VERSION ""

NS_ :

BS_:

BU_: DCM CCU C_ECU C_ECU_GW

BO_ 1546 BAT60A: 32 C_ECU_GW
 SG_ BAT60A_29_4_LVB_VOL : 236|8@1+ (0.1,0) [0|25] "V" Vector__XXX
 SG_ BAT60A_29_3_EXWATTMPERR : 235|1@1+ (1,0) [0|1] "" Vector__XXX
 SG_ BAT60A_29_2_SNSWATTMPERR : 234|1@1+ (1,0) [0|1] "" Vector__XXX
 SG_ BAT60A_29_1_SNSSMKEMSERR : 233|1@1+ (1,0) [0|1] "" Vector__XXX
 SG_ BAT60A_29_0_SNSEXTMP2ERR : 232|1@1+ (1,0) [0|1] "" Vector__XXX
 SG_ BAT60A_28_7_SNSEXTMP1ERR : 231|1@1+ (1,0) [0|1] "" Vector__XXX
 SG_ BAT60A_28_6_DEVTSTCK3ERR : 230|1@1+ (1,0) [0|1] "" Vector__XXX
 SG_ BAT60A_28_5_DEVTSTCK2ERR : 229|1@1+ (1,0) [0|1] "" Vector__XXX
 SG_ BAT60A_28_4_DEVTSTCK1ERR : 228|1@1+ (1,0) [0|1] "" Vector__XXX
 SG_ BAT60A_28_3_OVERTLVL2ERR : 227|1@1+ (1,0) [0|1] "" Vector__XXX
 SG_ BAT60A_28_2_OVERTLVL1ERR : 226|1@1+ (1,0) [0|1] "" Vector__XXX
 SG_ BAT60A_28_1_RESDEVERR : 225|1@1+ (1,0) [0|1] "" Vector__XXX
 SG_ BAT60A_28_0_PWLINEOV6ERR : 224|1@1+ (1,0) [0|1] "" Vector__XXX
 SG_ BAT60A_27_7_PWLINEOV5ERR : 223|1@1+ (1,0) [0|1] "" Vector__XXX
 SG_ BAT60A_27_6_PWLINEOV4ERR : 222|1@1+ (1,0) [0|1] "" Vector__XXX
 SG_ BAT60A_27_5_PWLINEOV3ERR : 221|1@1+ (1,0) [0|1] "" Vector__XXX
 SG_ BAT60A_27_4_PWLINEOV2ERR : 220|1@1+ (1,0) [0|1] "" Vector__XXX
 SG_ BAT60A_27_3_PWLINEOV1ERR : 219|1@1+ (1,0) [0|1] "" Vector__XXX
 SG_ BAT60A_27_2_VWOUTOVERERR : 218|1@1+ (1,0) [0|1] "" Vector__XXX
 SG_ BAT60A_27_1_VWINOVERERR : 217|1@1+ (1,0) [0|1] "" Vector__XXX
 SG_ BAT60A_27_0_ACTESTDEVERR : 216|1@1+ (1,0) [0|1] "" Vector__XXX
 SG_ BAT60A_26_7_RWOUTUNDERR : 215|1@1+ (1,0) [0|1] "" Vector__XXX
 SG_ BAT60A_26_6_RWINOVRERR : 214|1@1+ (1,0) [0|1] "" Vector__XXX
 SG_ BAT60A_26_5_HVOFFISOERR : 213|1@1+ (1,0) [0|1] "" Vector__XXX
 SG_ BAT60A_26_4_HVONISOERR : 212|1@1+ (1,0) [0|1] "" Vector__XXX
 SG_ BAT60A_26_3_HVSUMCOMPERR : 211|1@1+ (1,0) [0|1] "" Vector__XXX
 SG_ BAT60A_26_2_CEUNDULV2ERR : 210|1@1+ (1,0) [0|1] "" Vector__XXX
 SG_ BAT60A_26_1_CEOVRULV2ERR : 209|1@1+ (1,0) [0|1] "" Vector__XXX
 SG_ BAT60A_26_0_ICHPEAKERR : 208|1@1+ (1,0) [0|1] "" Vector__XXX
 SG_ BAT60A_25_7_IDCHAPEAKERR : 207|1@1+ (1,0) [0|1] "" Vector__XXX
 SG_ BAT60A_25_6_HVOVRULV2ERR : 206|1@1+ (1,0) [0|1] "" Vector__XXX
 SG_ BAT60A_25_5_HVUNDULV2ERR : 205|1@1+ (1,0) [0|1] "" Vector__XXX
 SG_ BAT60A_25_4_CEUNDULV1ERR : 204|1@1+ (1,0) [0|1] "" Vector__XXX
 SG_ BAT60A_25_3_CEOVRULV1ERR : 203|1@1+ (1,0) [0|1] "" Vector__XXX
 SG_ BAT60A_25_2_HVOVRULV1ERR : 202|1@1+ (1,0) [0|1] "" Vector__XXX
 SG_ BAT60A_25_1_CEUDIFDYNERR : 201|1@1+ (1,0) [0|1] "" Vector__XXX
 SG_ BAT60A_25_0_OVERSOCERR : 200|1@1+ (1,0) [0|1] "" Vector__XXX
 SG_ BAT60A_24_7_UNDERSOCERR : 199|1@1+ (1,0) [0|1] "" Vector__XXX
 SG_ BAT60A_24_6_HVUNDULV1ERR : 198|1@1+ (1,0) [0|1] "" Vector__XXX
 SG_ BAT60A_24_5_ISOMEASERR : 197|1@1+ (1,0) [0|1] "" Vector__XXX
 SG_ BAT60A_24_4_CHGAWINOVERR : 196|1@1+ (1,0) [0|1] "" Vector__XXX
 SG_ BAT60A_24_3_CEUHIDIFERR : 195|1@1+ (1,0) [0|1] "" Vector__XXX
 SG_ BAT60A_23_6_HVB_OUTLIMFCT : 190|5@1+ (1,0) [0|30] "" Vector__XXX
 SG_ BAT60A_23_1_HVB_INLIMFCT : 185|5@1+ (1,0) [0|30] "" Vector__XXX
 SG_ BAT60A_22_4_HVB_WOUT : 180|10@1- (1,-510) [-510|511] "kW" Vector__XXX
 SG_ BAT60A_21_2_HVB_WIN : 170|10@1- (1,-510) [-510|511] "kW" Vector__XXX
 SG_ BAT60A_20_5_HVB_OPRMODE : 165|5@1+ (1,0) [0|30] "" Vector__XXX
 SG_ BAT60A_19_1_HVB_CELLSOHRMIN : 153|7@1+ (1,0) [0|100] "%" Vector__XXX
 SG_ BAT60A_18_2_HVB_CELLSOHRMAX : 146|7@1+ (1,0) [0|100] "%" Vector__XXX
 SG_ BAT60A_17_3_HVB_CELLSOHCMIN : 139|7@1+ (1,0) [0|100] "%" Vector__XXX
 SG_ BAT60A_16_4_HVB_CELLSOHCMAX : 132|7@1+ (1,0) [0|100] "%" Vector__XXX
 SG_ BAT60A_15_5_HVB_SOC : 125|7@1+ (1,0) [0|100] "%" Vector__XXX
 SG_ BAT60A_14_5_HVB_WATTEMP : 117|8@1- (1,-125) [-125|126] "℃" Vector__XXX
 SG_ BAT60A_13_5_JB_TEMPSNS : 109|8@1- (1,-125) [-125|126] "℃" Vector__XXX
 SG_ BAT60A_12_5_HVB_CELLTEMPMINNO : 101|8@1+ (1,0) [0|255] "" Vector__XXX
 SG_ BAT60A_11_5_HVB_CELLTEMPMAXNO : 93|8@1+ (1,0) [0|255] "" Vector__XXX
 SG_ BAT60A_10_5_HVB_CELLTEMPMIN : 85|8@1- (1,-125) [-125|126] "℃" Vector__XXX
 SG_ BAT60A_9_5_HVB_CELLTEMPMAX : 77|8@1- (1,-125) [-125|126] "℃" Vector__XXX
 SG_ BAT60A_8_2_HVB_CUR : 66|11@1- (1,-1020) [-1020|1021] "A" Vector__XXX
 SG_ BAT60A_7_2_HVB_CELLVOLMINNO : 58|8@1+ (1,0) [0|255] "" Vector__XXX
 SG_ BAT60A_6_2_HVB_CELLVOLMAXNO : 50|8@1+ (1,0) [0|255] "" Vector__XXX
 SG_ BAT60A_4_5_HVB_CELLVOLMIN : 37|13@1+ (1,0) [0|8190] "mV" Vector__XXX
 SG_ BAT60A_3_0_HVB_CELLVOLMAX : 24|13@1+ (1,0) [0|8190] "mV" Vector__XXX
 SG_ BAT60A_2_0_E2E_COUNTER : 16|8@1+ (1,0) [0|255] "" Vector__XXX
 SG_ BAT60A_0_0_E2E_CRC : 0|16@1+ (1,0) [0|65535] "" Vector__XXX

BO_ 1680 BAT690: 32 C_ECU_GW
 SG_ BAT690_28_2_CHG_REMTI_GRF26 : 226|8@1+ (45,0) [0|10800] "sec"  CCU
 SG_ BAT690_27_2_CHG_REMTI_GRF25 : 218|8@1+ (45,0) [0|10800] "sec"  CCU
 SG_ BAT690_26_2_CHG_REMTI_GRF24 : 210|8@1+ (45,0) [0|10800] "sec"  CCU
 SG_ BAT690_25_2_CHG_REMTI_GRF23 : 202|8@1+ (45,0) [0|10800] "sec"  CCU
 SG_ BAT690_24_2_CHG_REMTI_GRF22 : 194|8@1+ (45,0) [0|10800] "sec"  CCU
 SG_ BAT690_23_2_CHG_REMTI_GRF21 : 186|8@1+ (45,0) [0|10800] "sec"  CCU
 SG_ BAT690_22_2_CHG_REMTI_GRF20 : 178|8@1+ (45,0) [0|10800] "sec"  CCU
 SG_ BAT690_21_2_CHG_REMTI_GRF19 : 170|8@1+ (45,0) [0|10800] "sec"  CCU
 SG_ BAT690_20_2_CHG_REMTI_GRF18 : 162|8@1+ (45,0) [0|10800] "sec"  CCU
 SG_ BAT690_19_2_CHG_REMTI_GRF17 : 154|8@1+ (45,0) [0|10800] "sec"  CCU
 SG_ BAT690_18_2_CHG_REMTI_GRF16 : 146|8@1+ (45,0) [0|10800] "sec"  CCU
 SG_ BAT690_17_2_CHG_REMTI_GRF15 : 138|8@1+ (45,0) [0|10800] "sec"  CCU
 SG_ BAT690_16_2_CHG_REMTI_GRF14 : 130|8@1+ (45,0) [0|10800] "sec"  CCU
 SG_ BAT690_15_2_CHG_REMTI_GRF13 : 122|8@1+ (45,0) [0|10800] "sec"  CCU
 SG_ BAT690_14_2_CHG_REMTI_GRF12 : 114|8@1+ (45,0) [0|10800] "sec"  CCU
 SG_ BAT690_13_2_CHG_REMTI_GRF11 : 106|8@1+ (45,0) [0|10800] "sec"  CCU
 SG_ BAT690_12_2_CHG_REMTI_GRF10 : 98|8@1+ (45,0) [0|10800] "sec"  CCU
 SG_ BAT690_11_2_CHG_REMTI_GRF9 : 90|8@1+ (45,0) [0|10800] "sec"  CCU
 SG_ BAT690_10_2_CHG_REMTI_GRF8 : 82|8@1+ (45,0) [0|10800] "sec"  CCU
 SG_ BAT690_9_2_CHG_REMTI_GRF7 : 74|8@1+ (45,0) [0|10800] "sec"  CCU
 SG_ BAT690_8_2_CHG_REMTI_GRF6 : 66|8@1+ (45,0) [0|10800] "sec"  CCU
 SG_ BAT690_7_2_CHG_REMTI_GRF5 : 58|8@1+ (45,0) [0|10800] "sec"  CCU
 SG_ BAT690_6_2_CHG_REMTI_GRF4 : 50|8@1+ (45,0) [0|10800] "sec"  CCU
 SG_ BAT690_5_2_CHG_REMTI_GRF3 : 42|8@1+ (45,0) [0|10800] "sec"  CCU
 SG_ BAT690_4_2_CHG_REMTI_GRF2 : 34|8@1+ (45,0) [0|10800] "sec"  CCU
 SG_ BAT690_3_2_CHG_REMTI_GRF1 : 26|8@1+ (45,0) [0|10800] "sec"  CCU
 SG_ BAT690_3_0_CHG_REMTI_GRF : 24|2@1+ (1,0) [0|3] ""  CCU
 SG_ BAT690_2_0_E2E_COUNTER : 16|8@1+ (1,0) [0|255] ""  CCU
 SG_ BAT690_0_0_E2E_CRC : 0|16@1+ (1,0) [0|65535] ""  CCU

BO_ 862 BAT35E: 32 C_ECU_GW
 SG_ BAT35E_4_4_HVB_CONDCHK_FLG : 36|2@1+ (1,0) [0|3] ""  DCM
 SG_ BAT35E_3_2_HVB_CTRLSOC_PERC : 26|10@1+ (0.1,0) [0|100] "%" Vector__XXX
 SG_ BAT35E_3_0_HVB_WRN_TEMP : 24|2@1+ (1,0) [0|3] "" Vector__XXX
 SG_ BAT35E_2_0_E2E_COUNTER : 16|8@1+ (1,0) [0|255] ""  DCM
 SG_ BAT35E_0_0_E2E_CRC : 0|16@1+ (1,0) [0|65535] ""  DCM

BO_ 861 BAT35D: 32 C_ECU_GW
 SG_ BAT35D_28_5_HVB_ACTCHGWIN : 229|16@1+ (1,0) [0|65533] "kW"  DCM,CCU
 SG_ BAT35D_27_2_HVB_TEMPAVE : 218|11@1+ (0.5,-50) [-50|150] "℃"  CCU
 SG_ BAT35D_25_1_HVB_AVBENE_UPL : 201|17@1+ (1,0) [0|131000] "Wh"  CCU
 SG_ BAT35D_23_0_HVB_AVBENE_CUR : 184|17@1+ (1,0) [0|131000] "Wh"  CCU
 SG_ BAT35D_20_7_HVB_AVBENE_LOL : 167|17@1+ (1,0) [0|131000] "Wh"  CCU
 SG_ BAT35D_18_2_HVB_DISPSOHODO : 146|21@1+ (1,0) [0|1609343] "km"  DCM
 SG_ BAT35D_17_0_HVB_DISPSOH_PERC : 136|8@1+ (1,0) [0|100] "%"  DCM
 SG_ BAT35D_15_7_HVB_DISPSOH_R_AH : 127|9@1+ (1,0) [0|500] "Ah"  DCM
 SG_ BAT35D_14_6_HVB_DISPSOH_AH : 118|9@1+ (1,0) [0|500] "Ah"  DCM
 SG_ BAT35D_13_0_CHG_REMTI_UPS_ACN : 104|14@1+ (1,0) [0|15840] "min"  DCM,CCU
 SG_ BAT35D_11_2_CHG_REMTI_UPS : 90|14@1+ (1,0) [0|15840] "min"  DCM,CCU
 SG_ BAT35D_9_4_CHG_REMTI_BLK_ACN : 76|14@1+ (1,0) [0|15840] "min"  DCM,CCU
 SG_ BAT35D_7_6_CHG_REMTI_BLK : 62|14@1+ (1,0) [0|15840] "min"  DCM,CCU
 SG_ BAT35D_6_0_CHG_REMTI_ACN : 48|14@1+ (1,0) [0|15840] "min"  CCU
 SG_ BAT35D_4_2_CHG_REMTI : 34|14@1+ (1,0) [0|15840] "min"  CCU
 SG_ BAT35D_3_0_HVB_DISPSOC_PERC : 24|8@1+ (1,0) [0|100] "%"  DCM,CCU
 SG_ BAT35D_2_0_E2E_COUNTER : 16|8@1+ (1,0) [0|255] ""  DCM
 SG_ BAT35D_0_0_E2E_CRC : 0|16@1+ (1,0) [0|65535] ""  DCM

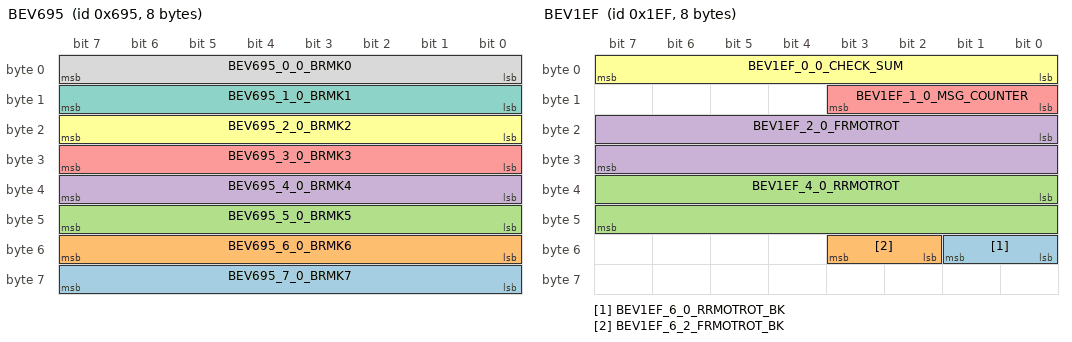
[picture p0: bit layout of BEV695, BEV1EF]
BO_ 1685 BEV695: 8 C_ECU_GW
 SG_ BEV695_7_0_BRMK7 : 56|8@1+ (1,0) [0|255] "" Vector__XXX
 SG_ BEV695_6_0_BRMK6 : 48|8@1+ (1,0) [0|255] "" Vector__XXX
 SG_ BEV695_5_0_BRMK5 : 40|8@1+ (1,0) [0|255] "" Vector__XXX
 SG_ BEV695_4_0_BRMK4 : 32|8@1+ (1,0) [0|255] "" Vector__XXX
 SG_ BEV695_3_0_BRMK3 : 24|8@1+ (1,0) [0|255] "" Vector__XXX
 SG_ BEV695_2_0_BRMK2 : 16|8@1+ (1,0) [0|255] "" Vector__XXX
 SG_ BEV695_1_0_BRMK1 : 8|8@1+ (1,0) [0|255] "" Vector__XXX
 SG_ BEV695_0_0_BRMK0 : 0|8@1+ (1,0) [0|255] "" Vector__XXX

BO_ 1539 BEV603: 32 C_ECU_GW
 SG_ BEV603_15_0_BATTEMPSTS_DISP : 120|3@1+ (1,0) [0|5] "" Vector__XXX
 SG_ BEV603_14_0_RR_MTRTEMPSTS_DISP : 112|3@1+ (1,0) [0|5] "" Vector__XXX
 SG_ BEV603_14_3_FR_MTRTEMPSTS_DISP : 115|3@1+ (1,0) [0|5] "" Vector__XXX
 SG_ BEV603_13_0_BATTEMP_DISP : 104|8@1+ (1,-30) [-30|225] "℃" Vector__XXX
 SG_ BEV603_12_0_RR_MTRTEMP_DISP : 96|8@1+ (1,-30) [-30|225] "℃" Vector__XXX
 SG_ BEV603_11_0_FR_MTRTEMP_DISP : 88|8@1+ (1,-30) [-30|225] "℃" Vector__XXX
 SG_ BEV603_10_2_TRQFLCREQ : 82|2@1+ (1,0) [0|3] "" Vector__XXX
 SG_ BEV603_10_4_TRQFLCNG : 84|1@1+ (1,0) [0|1] ""  CCU
 SG_ BEV603_10_5_TRQFLCSTATE : 85|1@1+ (1,0) [0|1] ""  CCU
 SG_ BEV603_10_6_TRQFLCDISP : 86|1@1+ (1,0) [0|1] ""  CCU
 SG_ BEV603_10_7_TRQVIBREQ : 87|1@1+ (1,0) [0|1] "" Vector__XXX
 SG_ BEV603_9_4_PADL_INHBUZ : 76|1@1+ (1,0) [0|1] "" Vector__XXX
 SG_ BEV603_9_5_PADL_LVL : 77|3@1+ (1,0) [0|7] "" Vector__XXX
 SG_ BEV603_8_1_XMODE_INH : 65|1@1+ (1,0) [0|1] ""  CCU
 SG_ BEV603_8_2_SIDRIVE_INH : 66|1@1+ (1,0) [0|1] ""  CCU
 SG_ BEV603_8_3_SIDRIVE_INHBUZ : 67|1@1+ (1,0) [0|1] "" Vector__XXX
 SG_ BEV603_8_4_ARBIT_SIDR : 68|1@1+ (1,0) [0|1] "" Vector__XXX
 SG_ BEV603_8_5_SIDRIVE_DISP : 69|3@1+ (1,0) [0|7] "" Vector__XXX
 SG_ BEV603_7_4_ADPDEC_INHBUZ : 60|1@1+ (1,0) [0|1] "" Vector__XXX
 SG_ BEV603_7_5_ADPDEC_INH_ALL : 61|1@1+ (1,0) [0|1] ""  CCU
 SG_ BEV603_7_6_ADPDEC_DISP : 62|1@1+ (1,0) [0|1] ""  CCU
 SG_ BEV603_7_7_ADPDEC_EQ : 63|1@1+ (1,0) [0|1] ""  CCU
 SG_ BEV603_6_0_AWD_MODE : 48|3@1+ (1,0) [0|7] "" Vector__XXX
 SG_ BEV603_6_3_AWD_STS_DISP : 51|4@1+ (1,0) [0|7] "" Vector__XXX
 SG_ BEV603_6_4_DECSEL_INHMSG : 52|4@1+ (1,0) [0|15] "" Vector__XXX
 SG_ BEV603_6_7_AWD_MODE_EQUIP : 55|1@1+ (1,0) [0|1] "" Vector__XXX
 SG_ BEV603_5_0_PDLBZR : 40|1@1+ (1,0) [0|1] "" Vector__XXX
 SG_ BEV603_5_1_SFTDN_PERM : 41|1@1+ (1,0) [0|1] "" Vector__XXX
 SG_ BEV603_5_2_SFTUP_PERM : 42|1@1+ (1,0) [0|1] "" Vector__XXX
 SG_ BEV603_5_3_GEARSFT_MODE : 43|2@1+ (1,0) [0|3] ""  CCU
 SG_ BEV603_5_4_DECSEL_INH_INDI : 44|1@1+ (1,0) [0|1] "" Vector__XXX
 SG_ BEV603_5_5_DECSEL_INH_B : 45|1@1+ (1,0) [0|1] "" Vector__XXX
 SG_ BEV603_5_6_DECSEL_INH_D : 46|1@1+ (1,0) [0|1] "" Vector__XXX
 SG_ BEV603_5_7_DECSEL_INH_ALL : 47|1@1+ (1,0) [0|1] "" Vector__XXX
 SG_ BEV603_4_1_DECSEL_DISP_INDI : 33|1@1+ (1,0) [0|1] "" Vector__XXX
 SG_ BEV603_4_2_DECSEL_DISP_B : 34|2@1+ (1,0) [0|3] "" Vector__XXX
 SG_ BEV603_4_4_DECLV_DECSEL : 36|4@1+ (1,0) [0|8] "" Vector__XXX
 SG_ BEV603_4_6_DECSEL_DISP_ALL : 38|2@1+ (1,0) [0|3] "" Vector__XXX
 SG_ BEV603_3_0_GEARLV_MANU : 24|4@1+ (1,0) [0|8] ""  CCU
 SG_ BEV603_3_1_DECSEL_EQ_INDI : 25|1@1+ (1,0) [0|1] "" Vector__XXX
 SG_ BEV603_3_2_DECSEL_EQ_B : 26|2@1+ (1,0) [0|3] "" Vector__XXX
 SG_ BEV603_3_4_GEARLV_AUTO : 28|4@1+ (1,0) [0|8] ""  CCU
 SG_ BEV603_3_6_DECSEL_EQ_ALL : 30|2@1+ (1,0) [0|3] "" Vector__XXX
 SG_ BEV603_2_0_E2E_COUNTER : 16|8@1+ (1,0) [0|255] ""  CCU
 SG_ BEV603_0_0_E2E_CRC : 0|16@1+ (1,0) [0|65535] ""  CCU

BO_ 1538 BEV602: 32 C_ECU_GW
 SG_ BEV602_18_0_V2L_OUTLET_VOLTAGE : 144|8@1+ (0.01,0) [0|250] "V"  CCU
 SG_ BEV602_16_0_LV_SYS_STATUS : 128|2@1+ (1,0) [0|3] "" Vector__XXX
 SG_ BEV602_15_0_DCM_REMOTE_INFO : 120|4@1+ (1,0) [0|7] ""  DCM
 SG_ BEV602_14_7_RR_DISPMSG_RES_UNADJ : 119|1@1+ (1,0) [0|1] "" Vector__XXX
 SG_ BEV602_14_6_FR_DISPMSG_RES_UNADJ : 118|1@1+ (1,0) [0|1] "" Vector__XXX
 SG_ BEV602_14_4_DISPMSG_SC_SGLPH : 116|2@1+ (1,0) [0|3] "" Vector__XXX
 SG_ BEV602_14_2_CERT2_MODE : 114|2@1+ (1,0) [0|2] "" Vector__XXX
 SG_ BEV602_14_0_SW_PWR_SPL : 112|2@1+ (1,0) [0|3] ""  CCU
 SG_ BEV602_13_0_TCSLMP_REQ : 104|1@1+ (1,0) [0|1] "" Vector__XXX
 SG_ BEV602_13_1_AWDLMP_REQ : 105|2@1+ (1,0) [0|3] "" Vector__XXX
 SG_ BEV602_13_3_AWDWRNMSG_REQ : 107|4@1+ (1,0) [0|2] "" Vector__XXX
 SG_ BEV602_12_0_BOSLMP_REQ : 96|2@1+ (1,0) [0|3] "" Vector__XXX
 SG_ BEV602_11_3_LVB_ABN : 91|3@1+ (1,0) [0|4] "" Vector__XXX
 SG_ BEV602_11_6_CERT4_MODE : 94|1@1+ (1,0) [0|1] "" Vector__XXX
 SG_ BEV602_11_7_CERT2_MODE : 95|1@1+ (1,0) [0|1] "" Vector__XXX
 SG_ BEV602_10_0_FACT_CERT_MODE : 80|1@1+ (1,0) [0|1] "" Vector__XXX
 SG_ BEV602_10_1_FACT_MODE : 81|1@1+ (1,0) [0|1] "" Vector__XXX
 SG_ BEV602_10_2_EVBATLO_CAU : 82|3@1+ (1,0) [0|7] ""  DCM,CCU
 SG_ BEV602_10_5_PWRLMT_ID : 85|3@1+ (1,0) [0|3] "" Vector__XXX
 SG_ BEV602_9_1_DCRCHK_DSP_REQ : 73|3@1+ (1,0) [0|4] "" Vector__XXX
 SG_ BEV602_9_4_LVB_FNCLMT_MSG : 76|3@1+ (1,0) [0|3] ""  CCU
 SG_ BEV602_9_7_CHG_MSG : 79|1@1+ (1,0) [0|1] "" Vector__XXX
 SG_ BEV602_8_0_LVB_ABN_DCDC : 64|3@1+ (1,0) [0|2] "" Vector__XXX
 SG_ BEV602_8_4_LVB_ABN_LIB : 68|3@1+ (1,0) [0|3] "" Vector__XXX
 SG_ BEV602_8_7_CHG_CAU : 71|1@1+ (1,0) [0|1] "" Vector__XXX
 SG_ BEV602_7_0_V2L_STOP_MSG : 56|8@1+ (1,0) [0|8] ""  DCM,CCU
 SG_ BEV602_6_0_V2L_SOC_LOWLMT : 48|8@1+ (0.01,0) [0|255] "%"  DCM,CCU
 SG_ BEV602_5_0_V2L_OUTSTS_2 : 40|1@1+ (1,0) [0|1] ""  CCU
 SG_ BEV602_5_1_V2L_OUTSTS_1 : 41|1@1+ (1,0) [0|1] ""  DCM,CCU
 SG_ BEV602_5_2_ACCHCAU : 42|1@1+ (1,0) [0|1] "" Vector__XXX
 SG_ BEV602_5_3_EVIND : 43|5@1+ (1,0) [0|49] ""  DCM
 SG_ BEV602_4_0_BEV_OBD_CAU : 32|3@1+ (1,0) [0|7] "" Vector__XXX
 SG_ BEV602_4_3_EV_CAU : 35|2@1+ (1,0) [0|3] "" Vector__XXX
 SG_ BEV602_4_5_PIROFF_MSG : 37|1@1+ (1,0) [0|1] "" Vector__XXX
 SG_ BEV602_3_0_DRVRDY : 24|2@1+ (1,0) [0|3] "" Vector__XXX
 SG_ BEV602_3_2_RANGE_POS : 26|3@1+ (1,0) [0|7] ""  CCU
 SG_ BEV602_2_0_E2E_COUNTER : 16|8@1+ (1,0) [0|255] ""  DCM,CCU
 SG_ BEV602_0_0_E2E_CRC : 0|16@1+ (1,0) [0|65535] ""  DCM,CCU

BO_ 541 BEV21D: 32 C_ECU_GW
 SG_ BEV21D_4_0_V2L_PWR_2 : 32|8@1+ (0.1,0) [0|25.5] "kW"  CCU
 SG_ BEV21D_3_0_V2L_PWR_1 : 24|8@1+ (0.1,0) [0|25.5] "kW"  DCM,CCU
 SG_ BEV21D_2_0_E2E_COUNTER : 16|8@1+ (1,0) [0|255] ""  DCM,CCU
 SG_ BEV21D_0_0_E2E_CRC : 0|16@1+ (1,0) [0|65535] ""  DCM,CCU

BO_ 269 BEV10D: 32 C_ECU_GW
 SG_ BEV10D_22_0_SNDGAIN_CHG : 176|4@1+ (1,0) [0|15] ""  CCU
 SG_ BEV10D_21_0_EVENT_VOL_B : 168|8@1+ (1,0) [0|255] ""  CCU
 SG_ BEV10D_20_0_EVENT_VOL_A : 160|8@1+ (1,0) [0|255] ""  CCU
 SG_ BEV10D_18_0_RR_MTRTRQ_SND : 144|16@1- (0.03125,0) [-1024|1023.96875] "Nm"  CCU
 SG_ BEV10D_16_0_FR_MTRTRQ_SND : 128|16@1- (0.03125,0) [-1024|1023.96875] "Nm"  CCU
 SG_ BEV10D_15_6_ENGON_SND : 126|1@1+ (1,0) [0|1] ""  CCU
 SG_ BEV10D_15_7_BKF_SND : 127|1@1+ (1,0) [0|1] ""  CCU
 SG_ BEV10D_14_0_V_ENGRPM_SND : 112|14@1+ (1,0) [0|16383] "rpm"  CCU
 SG_ BEV10D_12_0_V_RZRPM_DISP : 96|8@1+ (50,5000) [5000|17750] "rpm" Vector__XXX
 SG_ BEV10D_11_6_SNDOUT_SET : 94|1@1+ (1,0) [0|1] ""  CCU
 SG_ BEV10D_10_0_V_ENGRPM_DISP : 80|14@1+ (1,0) [0|16383] "rpm" Vector__XXX
 SG_ BEV10D_9_1_PMINPWRLMTNTC : 73|7@1+ (1,0) [0|100] "%" Vector__XXX
 SG_ BEV10D_8_0_PMOUTPWRLMTNTC : 64|9@1+ (1,0) [0|511] "%" Vector__XXX
 SG_ BEV10D_7_2_DCLLO_DISP : 58|2@1+ (1,0) [0|3] "" Vector__XXX
 SG_ BEV10D_7_4_PMINPWRLMTSTS : 60|1@1+ (1,0) [0|1] "" Vector__XXX
 SG_ BEV10D_7_5_PMOUTPWRLMTSTS : 61|1@1+ (1,0) [0|1] "" Vector__XXX
 SG_ BEV10D_6_0_PMPWR : 48|10@1- (1,0) [-512|511] "%" Vector__XXX
 SG_ BEV10D_5_1_PMINPWRLMT : 41|7@1+ (1,0) [0|100] "%" Vector__XXX
 SG_ BEV10D_4_0_PMOUTPWRLMT : 32|9@1+ (1,0) [0|511] "%" Vector__XXX
 SG_ BEV10D_3_0_LVB_SOC_LIB : 24|8@1+ (1,0) [0|255] ""  CCU
 SG_ BEV10D_2_0_E2E_COUNTER : 16|8@1+ (1,0) [0|255] ""  CCU
 SG_ BEV10D_0_0_E2E_CRC : 0|16@1+ (1,0) [0|65535] ""  CCU

BO_ 495 BEV1EF: 8 C_ECU_GW
 SG_ BEV1EF_6_0_RRMOTROT_BK : 48|2@1+ (1,0) [0|3] "" Vector__XXX
 SG_ BEV1EF_6_2_FRMOTROT_BK : 50|2@1+ (1,0) [0|3] "" Vector__XXX
 SG_ BEV1EF_4_0_RRMOTROT : 32|16@1- (1,0) [-32768|32767] "rpm" Vector__XXX
 SG_ BEV1EF_2_0_FRMOTROT : 16|16@1- (1,0) [-32768|32767] "rpm" Vector__XXX
 SG_ BEV1EF_1_0_MSG_COUNTER : 8|4@1+ (1,0) [0|15] "" Vector__XXX
 SG_ BEV1EF_0_0_CHECK_SUM : 0|8@1+ (1,0) [0|255] "" Vector__XXX

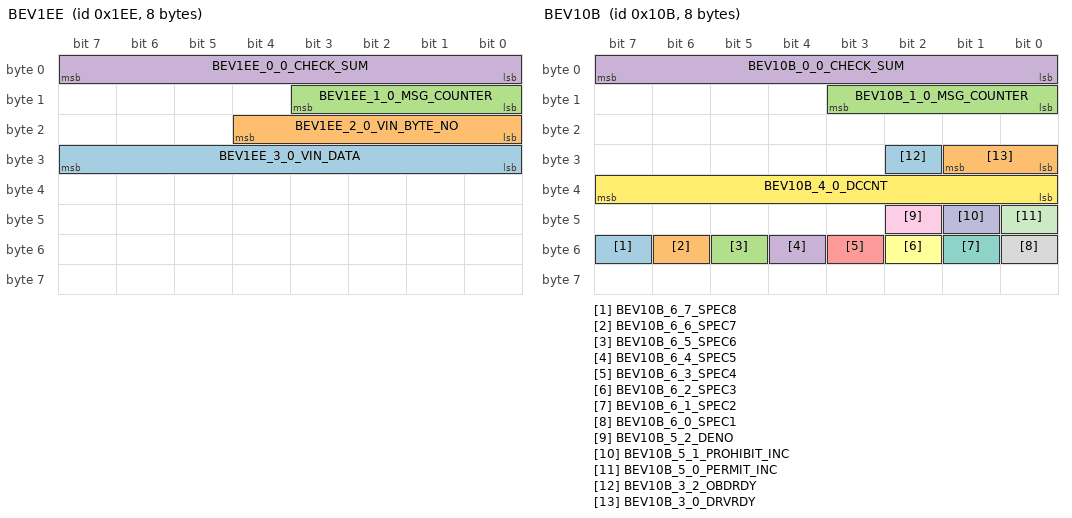
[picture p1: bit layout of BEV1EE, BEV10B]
BO_ 494 BEV1EE: 8 C_ECU_GW
 SG_ BEV1EE_3_0_VIN_DATA : 24|8@1+ (1,0) [0|255] ""  DCM,CCU
 SG_ BEV1EE_2_0_VIN_BYTE_NO : 16|5@1+ (1,0) [0|17] ""  DCM,CCU
 SG_ BEV1EE_1_0_MSG_COUNTER : 8|4@1+ (1,0) [0|15] ""  DCM
 SG_ BEV1EE_0_0_CHECK_SUM : 0|8@1+ (1,0) [0|255] ""  DCM

BO_ 267 BEV10B: 8 C_ECU_GW
 SG_ BEV10B_6_7_SPEC8 : 55|1@1+ (1,0) [0|1] "" Vector__XXX
 SG_ BEV10B_6_6_SPEC7 : 54|1@1+ (1,0) [0|1] "" Vector__XXX
 SG_ BEV10B_6_5_SPEC6 : 53|1@1+ (1,0) [0|1] "" Vector__XXX
 SG_ BEV10B_6_4_SPEC5 : 52|1@1+ (1,0) [0|1] "" Vector__XXX
 SG_ BEV10B_6_3_SPEC4 : 51|1@1+ (1,0) [0|1] "" Vector__XXX
 SG_ BEV10B_6_2_SPEC3 : 50|1@1+ (1,0) [0|1] "" Vector__XXX
 SG_ BEV10B_6_1_SPEC2 : 49|1@1+ (1,0) [0|1] "" Vector__XXX
 SG_ BEV10B_6_0_SPEC1 : 48|1@1+ (1,0) [0|1] "" Vector__XXX
 SG_ BEV10B_5_2_DENO : 42|1@1+ (1,0) [0|1] "" Vector__XXX
 SG_ BEV10B_5_1_PROHIBIT_INC : 41|1@1+ (1,0) [0|1] "" Vector__XXX
 SG_ BEV10B_5_0_PERMIT_INC : 40|1@1+ (1,0) [0|1] "" Vector__XXX
 SG_ BEV10B_4_0_DCCNT : 32|8@1+ (1,0) [0|255] "" Vector__XXX
 SG_ BEV10B_3_2_OBDRDY : 26|1@1+ (1,0) [0|1] "" Vector__XXX
 SG_ BEV10B_3_0_DRVRDY : 24|2@1+ (1,0) [0|3] "" Vector__XXX
 SG_ BEV10B_1_0_MSG_COUNTER : 8|4@1+ (1,0) [0|15] "" Vector__XXX
 SG_ BEV10B_0_0_CHECK_SUM : 0|8@1+ (1,0) [0|255] "" Vector__XXX

BO_ 117 BEV075: 8 C_ECU_GW
 SG_ BEV075_1_0_MSG_COUNTER : 8|4@1+ (1,0) [0|15] "" Vector__XXX
 SG_ BEV075_0_0_CHECK_SUM : 0|8@1+ (1,0) [0|255] "" Vector__XXX

BO_ 116 BEV074: 8 C_ECU_GW
 SG_ BEV074_7_0_LVPWRDWN : 56|6@1+ (1,0) [0|3] ""  CCU
 SG_ BEV074_7_6_CHRCONSTA : 62|1@1+ (1,0) [0|1] "" Vector__XXX
 SG_ BEV074_7_7_VEHICLE_IGN : 63|1@1+ (1,0) [0|1] "" Vector__XXX
 SG_ BEV074_6_0_EV_CAU : 48|2@1+ (1,0) [0|3] ""  DCM
 SG_ BEV074_6_2_BEV_OBD_CAU : 50|3@1+ (1,0) [0|7] "" Vector__XXX
 SG_ BEV074_6_5_SIDRIVE_DISP : 53|3@1+ (1,0) [0|7] "" Vector__XXX
 SG_ BEV074_5_0_ACCHG_STATE : 40|1@1+ (1,0) [0|1] ""  CCU
 SG_ BEV074_5_1_DCCHG_STATE : 41|1@1+ (1,0) [0|1] ""  CCU
 SG_ BEV074_5_2_RANGE_DG : 42|1@1+ (1,0) [0|1] "" Vector__XXX
 SG_ BEV074_5_3_ACCP_DG : 43|1@1+ (1,0) [0|1] "" Vector__XXX
 SG_ BEV074_5_4_REZ_SPD_BK : 44|2@1+ (1,0) [0|3] "" Vector__XXX
 SG_ BEV074_5_6_OBDRDY : 46|1@1+ (1,0) [0|1] "" Vector__XXX
 SG_ BEV074_5_7_FHVB : 47|1@1+ (1,0) [0|1] "" Vector__XXX
 SG_ BEV074_3_0_RANGE_POS : 24|3@1+ (1,0) [0|7] ""  DCM,CCU
 SG_ BEV074_3_3_DRVRDY : 27|2@1+ (1,0) [0|3] ""  DCM
 SG_ BEV074_3_5_HVSYSTS : 29|2@1+ (1,0) [0|3] "" Vector__XXX
 SG_ BEV074_3_7_REZ_SPD_GL : 31|9@1- (1,0) [-256|255] "km/h" Vector__XXX
 SG_ BEV074_2_0_ACCP_USR : 16|8@1+ (0.5,0) [0|127.5] "%" Vector__XXX
 SG_ BEV074_1_0_MSG_COUNTER : 8|4@1+ (1,0) [0|15] ""  DCM
 SG_ BEV074_1_4_RANGE_DG2 : 12|1@1+ (1,0) [0|1] "" Vector__XXX
 SG_ BEV074_1_5_REZ_SPD_BK : 13|3@1+ (1,0) [0|5] "" Vector__XXX
 SG_ BEV074_0_0_CHECK_SUM : 0|8@1+ (1,0) [0|255] ""  DCM

BO_ 2564481473 DCM18DAE1C1: 64 DCM
 SG_ DCM18DAE1C1_DIAG_DATA_EXT7 : 455|64@0+ (1,0) [0|1.844674407371E+19] ""  C_ECU
 SG_ DCM18DAE1C1_DIAG_DATA_EXT6 : 391|64@0+ (1,0) [0|1.844674407371E+19] ""  C_ECU
 SG_ DCM18DAE1C1_DIAG_DATA_EXT5 : 327|64@0+ (1,0) [0|1.844674407371E+19] ""  C_ECU
 SG_ DCM18DAE1C1_DIAG_DATA_EXT4 : 263|64@0+ (1,0) [0|1.844674407371E+19] ""  C_ECU
 SG_ DCM18DAE1C1_DIAG_DATA_EXT3 : 199|64@0+ (1,0) [0|1.844674407371E+19] ""  C_ECU
 SG_ DCM18DAE1C1_DIAG_DATA_EXT2 : 135|64@0+ (1,0) [0|1.844674407371E+19] ""  C_ECU
 SG_ DCM18DAE1C1_DIAG_DATA_EXT1 : 71|64@0+ (1,0) [0|1.844674407371E+19] ""  C_ECU
 SG_ DCM18DAE1C1_DIAG_DATA : 7|64@0+ (1,0) [0|1.844674407371E+19] ""  C_ECU

BO_ 2564473313 CECU18DAC1E1: 64 C_ECU
 SG_ CECU18DAC1E1_DIAG_DATA_EXT7 : 455|64@0+ (1,0) [0|1.844674407371E+19] ""  DCM
 SG_ CECU18DAC1E1_DIAG_DATA_EXT6 : 391|64@0+ (1,0) [0|1.844674407371E+19] ""  DCM
 SG_ CECU18DAC1E1_DIAG_DATA_EXT5 : 327|64@0+ (1,0) [0|1.844674407371E+19] ""  DCM
 SG_ CECU18DAC1E1_DIAG_DATA_EXT4 : 263|64@0+ (1,0) [0|1.844674407371E+19] ""  DCM
 SG_ CECU18DAC1E1_DIAG_DATA_EXT3 : 199|64@0+ (1,0) [0|1.844674407371E+19] ""  DCM
 SG_ CECU18DAC1E1_DIAG_DATA_EXT2 : 135|64@0+ (1,0) [0|1.844674407371E+19] ""  DCM
 SG_ CECU18DAC1E1_DIAG_DATA_EXT1 : 71|64@0+ (1,0) [0|1.844674407371E+19] ""  DCM
 SG_ CECU18DAC1E1_DIAG_DATA : 7|64@0+ (1,0) [0|1.844674407371E+19] ""  DCM

BO_ 2564481217 DCM18DAE0C1: 8 DCM
 SG_ DCM18DAE0C1_DIAG_DATA : 7|64@0+ (1,0) [0|1.844674407371E+19] ""  C_ECU_GW

BO_ 2564473312 DNT18DAC1E0: 8 C_ECU_GW
 SG_ DNT18DAC1E0_DIAG_DATA : 7|64@0+ (1,0) [0|1.844674407371E+19] ""  DCM

BO_ 2564468769 BIU18DAB021: 8 C_ECU_GW
 SG_ BIU18DAB021_DIAG_DATA : 7|64@0+ (1,0) [0|1.844674407371E+19] ""  CCU

BO_ 2564432304 AVN18DA21B0: 8 CCU
 SG_ AVN18DA21B0_DIAG_DATA : 7|64@0+ (1,0) [0|1.844674407371E+19] ""  C_ECU_GW

BO_ 2564481200 AVN18DAE0B0: 64 CCU
 SG_ AVN18DAE0B0_DIAG_DATA_EXT7 : 455|64@0+ (1,0) [0|1.844674407371E+19] ""  C_ECU_GW
 SG_ AVN18DAE0B0_DIAG_DATA_EXT6 : 391|64@0+ (1,0) [0|1.844674407371E+19] ""  C_ECU_GW
 SG_ AVN18DAE0B0_DIAG_DATA_EXT5 : 327|64@0+ (1,0) [0|1.844674407371E+19] ""  C_ECU_GW
 SG_ AVN18DAE0B0_DIAG_DATA_EXT4 : 263|64@0+ (1,0) [0|1.844674407371E+19] ""  C_ECU_GW
 SG_ AVN18DAE0B0_DIAG_DATA_EXT3 : 199|64@0+ (1,0) [0|1.844674407371E+19] ""  C_ECU_GW
 SG_ AVN18DAE0B0_DIAG_DATA_EXT2 : 135|64@0+ (1,0) [0|1.844674407371E+19] ""  C_ECU_GW
 SG_ AVN18DAE0B0_DIAG_DATA_EXT1 : 71|64@0+ (1,0) [0|1.844674407371E+19] ""  C_ECU_GW
 SG_ AVN18DAE0B0_DIAG_DATA : 7|64@0+ (1,0) [0|1.844674407371E+19] ""  C_ECU_GW

BO_ 2564468960 DNT18DAB0E0: 64 C_ECU_GW
 SG_ DNT18DAB0E0_DIAG_DATA_EXT7 : 455|64@0+ (1,0) [0|1.844674407371E+19] ""  CCU
 SG_ DNT18DAB0E0_DIAG_DATA_EXT6 : 391|64@0+ (1,0) [0|1.844674407371E+19] ""  CCU
 SG_ DNT18DAB0E0_DIAG_DATA_EXT5 : 327|64@0+ (1,0) [0|1.844674407371E+19] ""  CCU
 SG_ DNT18DAB0E0_DIAG_DATA_EXT4 : 263|64@0+ (1,0) [0|1.844674407371E+19] ""  CCU
 SG_ DNT18DAB0E0_DIAG_DATA_EXT3 : 199|64@0+ (1,0) [0|1.844674407371E+19] ""  CCU
 SG_ DNT18DAB0E0_DIAG_DATA_EXT2 : 135|64@0+ (1,0) [0|1.844674407371E+19] ""  CCU
 SG_ DNT18DAB0E0_DIAG_DATA_EXT1 : 71|64@0+ (1,0) [0|1.844674407371E+19] ""  CCU
 SG_ DNT18DAB0E0_DIAG_DATA : 7|64@0+ (1,0) [0|1.844674407371E+19] ""  CCU

BO_ 2564550625 CECU18DBEFE1: 8 C_ECU
 SG_ CECU18DBEFE1_DIAG_DATA : 7|64@0+ (1,0) [0|1.844674407371E+19] ""  DCM,CCU

BO_ 2564550624 DNT18DBEFE0: 8 C_ECU_GW
 SG_ DNT18DBEFE0_DIAG_DATA : 7|64@0+ (1,0) [0|1.844674407371E+19] ""  DCM,CCU

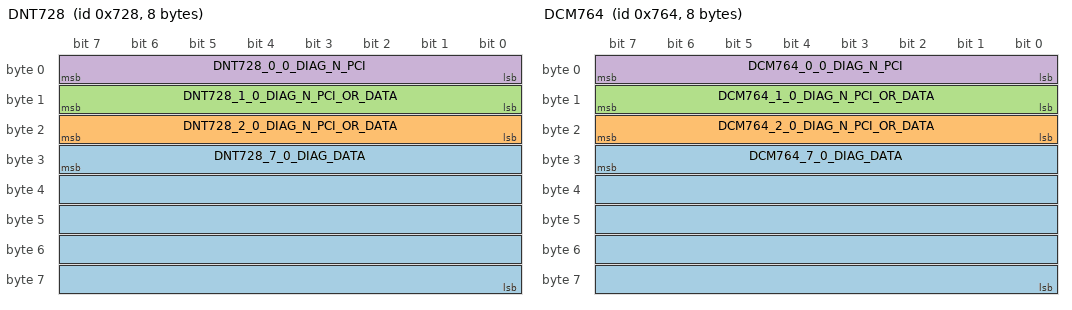
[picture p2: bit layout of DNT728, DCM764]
BO_ 1832 DNT728: 8 C_ECU_GW
 SG_ DNT728_7_0_DIAG_DATA : 31|40@0+ (1,0) [0|1099511627775] "" Vector__XXX
 SG_ DNT728_2_0_DIAG_N_PCI_OR_DATA : 23|8@0+ (1,0) [0|255] "" Vector__XXX
 SG_ DNT728_1_0_DIAG_N_PCI_OR_DATA : 15|8@0+ (1,0) [0|255] "" Vector__XXX
 SG_ DNT728_0_0_DIAG_N_PCI : 7|8@0+ (1,0) [0|255] "" Vector__XXX

BO_ 2564481456 AVN18DAE1B0: 64 CCU
 SG_ AVN18DAE1B0_DIAG_DATA_EXT7 : 455|64@0+ (1,0) [0|1.844674407371E+19] ""  C_ECU
 SG_ AVN18DAE1B0_DIAG_DATA_EXT6 : 391|64@0+ (1,0) [0|1.844674407371E+19] ""  C_ECU
 SG_ AVN18DAE1B0_DIAG_DATA_EXT5 : 327|64@0+ (1,0) [0|1.844674407371E+19] ""  C_ECU
 SG_ AVN18DAE1B0_DIAG_DATA_EXT4 : 263|64@0+ (1,0) [0|1.844674407371E+19] ""  C_ECU
 SG_ AVN18DAE1B0_DIAG_DATA_EXT3 : 199|64@0+ (1,0) [0|1.844674407371E+19] ""  C_ECU
 SG_ AVN18DAE1B0_DIAG_DATA_EXT2 : 135|64@0+ (1,0) [0|1.844674407371E+19] ""  C_ECU
 SG_ AVN18DAE1B0_DIAG_DATA_EXT1 : 71|64@0+ (1,0) [0|1.844674407371E+19] ""  C_ECU
 SG_ AVN18DAE1B0_DIAG_DATA : 7|64@0+ (1,0) [0|1.844674407371E+19] ""  C_ECU

BO_ 2564468961 CECU18DAB0E1: 64 C_ECU
 SG_ CECU18DAB0E1_DIAG_DATA_EXT7 : 455|64@0+ (1,0) [0|1.844674407371E+19] ""  CCU
 SG_ CECU18DAB0E1_DIAG_DATA_EXT6 : 391|64@0+ (1,0) [0|1.844674407371E+19] ""  CCU
 SG_ CECU18DAB0E1_DIAG_DATA_EXT5 : 327|64@0+ (1,0) [0|1.844674407371E+19] ""  CCU
 SG_ CECU18DAB0E1_DIAG_DATA_EXT4 : 263|64@0+ (1,0) [0|1.844674407371E+19] ""  CCU
 SG_ CECU18DAB0E1_DIAG_DATA_EXT3 : 199|64@0+ (1,0) [0|1.844674407371E+19] ""  CCU
 SG_ CECU18DAB0E1_DIAG_DATA_EXT2 : 135|64@0+ (1,0) [0|1.844674407371E+19] ""  CCU
 SG_ CECU18DAB0E1_DIAG_DATA_EXT1 : 71|64@0+ (1,0) [0|1.844674407371E+19] ""  CCU
 SG_ CECU18DAB0E1_DIAG_DATA : 7|64@0+ (1,0) [0|1.844674407371E+19] ""  CCU

BO_ 2564481573 CECU18DAE225: 64 C_ECU
 SG_ CECU18DAE225_DIAG_DATA_EXT7 : 455|64@0+ (1,0) [0|1.844674407371E+19] ""  DCM
 SG_ CECU18DAE225_DIAG_DATA_EXT6 : 391|64@0+ (1,0) [0|1.844674407371E+19] ""  DCM
 SG_ CECU18DAE225_DIAG_DATA_EXT5 : 327|64@0+ (1,0) [0|1.844674407371E+19] ""  DCM
 SG_ CECU18DAE225_DIAG_DATA_EXT4 : 263|64@0+ (1,0) [0|1.844674407371E+19] ""  DCM
 SG_ CECU18DAE225_DIAG_DATA_EXT3 : 199|64@0+ (1,0) [0|1.844674407371E+19] ""  DCM
 SG_ CECU18DAE225_DIAG_DATA_EXT2 : 135|64@0+ (1,0) [0|1.844674407371E+19] ""  DCM
 SG_ CECU18DAE225_DIAG_DATA_EXT1 : 71|64@0+ (1,0) [0|1.844674407371E+19] ""  DCM
 SG_ CECU18DAE225_DIAG_DATA : 7|64@0+ (1,0) [0|1.844674407371E+19] ""  DCM

BO_ 2564433378 DCM18DA25E2: 64 DCM
 SG_ DCM18DA25E2_DIAG_DATA_EXT7 : 455|64@0+ (1,0) [0|1.844674407371E+19] ""  C_ECU
 SG_ DCM18DA25E2_DIAG_DATA_EXT6 : 391|64@0+ (1,0) [0|1.844674407371E+19] ""  C_ECU
 SG_ DCM18DA25E2_DIAG_DATA_EXT5 : 327|64@0+ (1,0) [0|1.844674407371E+19] ""  C_ECU
 SG_ DCM18DA25E2_DIAG_DATA_EXT4 : 263|64@0+ (1,0) [0|1.844674407371E+19] ""  C_ECU
 SG_ DCM18DA25E2_DIAG_DATA_EXT3 : 199|64@0+ (1,0) [0|1.844674407371E+19] ""  C_ECU
 SG_ DCM18DA25E2_DIAG_DATA_EXT2 : 135|64@0+ (1,0) [0|1.844674407371E+19] ""  C_ECU
 SG_ DCM18DA25E2_DIAG_DATA_EXT1 : 71|64@0+ (1,0) [0|1.844674407371E+19] ""  C_ECU
 SG_ DCM18DA25E2_DIAG_DATA : 7|64@0+ (1,0) [0|1.844674407371E+19] ""  C_ECU

BO_ 1892 DCM764: 8 Vector__XXX
 SG_ DCM764_7_0_DIAG_DATA : 31|40@0+ (1,0) [0|1099511627775] ""  C_ECU_GW
 SG_ DCM764_2_0_DIAG_N_PCI_OR_DATA : 23|8@0+ (1,0) [0|255] ""  C_ECU_GW
 SG_ DCM764_1_0_DIAG_N_PCI_OR_DATA : 15|8@0+ (1,0) [0|255] ""  C_ECU_GW
 SG_ DCM764_0_0_DIAG_N_PCI : 7|8@0+ (1,0) [0|255] ""  C_ECU_GW

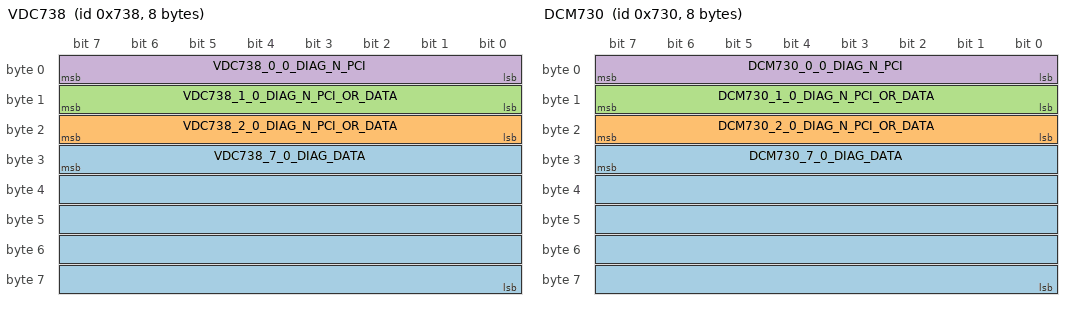
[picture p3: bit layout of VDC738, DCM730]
BO_ 1848 VDC738: 8 C_ECU_GW
 SG_ VDC738_7_0_DIAG_DATA : 31|40@0+ (1,0) [0|1099511627775] "" Vector__XXX
 SG_ VDC738_2_0_DIAG_N_PCI_OR_DATA : 23|8@0+ (1,0) [0|255] "" Vector__XXX
 SG_ VDC738_1_0_DIAG_N_PCI_OR_DATA : 15|8@0+ (1,0) [0|255] "" Vector__XXX
 SG_ VDC738_0_0_DIAG_N_PCI : 7|8@0+ (1,0) [0|255] "" Vector__XXX

BO_ 1840 DCM730: 8 Vector__XXX
 SG_ DCM730_7_0_DIAG_DATA : 31|40@0+ (1,0) [0|1099511627775] ""  C_ECU_GW
 SG_ DCM730_2_0_DIAG_N_PCI_OR_DATA : 23|8@0+ (1,0) [0|255] ""  C_ECU_GW
 SG_ DCM730_1_0_DIAG_N_PCI_OR_DATA : 15|8@0+ (1,0) [0|255] ""  C_ECU_GW
 SG_ DCM730_0_0_DIAG_N_PCI : 7|8@0+ (1,0) [0|255] ""  C_ECU_GW

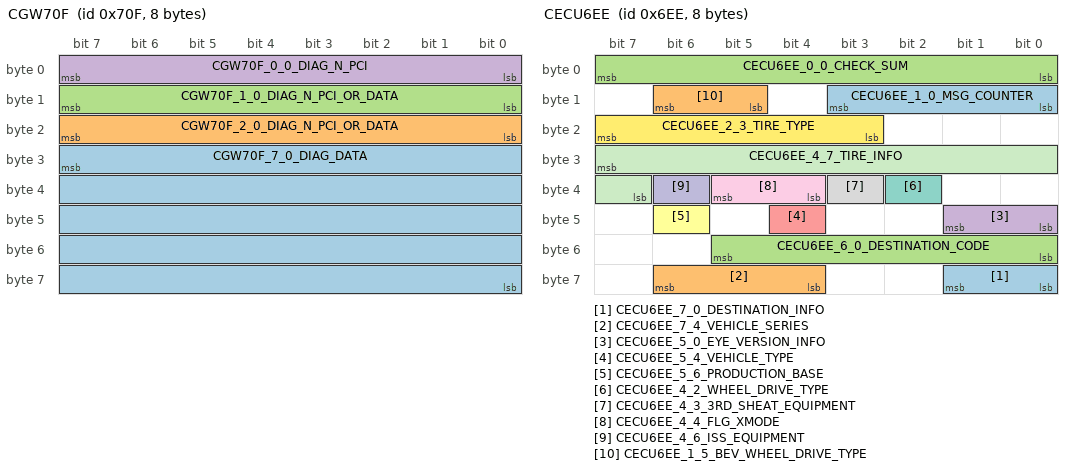
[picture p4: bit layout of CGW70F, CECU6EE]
BO_ 1807 CGW70F: 8 C_ECU
 SG_ CGW70F_7_0_DIAG_DATA : 31|40@0+ (1,0) [0|1099511627775] "" Vector__XXX
 SG_ CGW70F_2_0_DIAG_N_PCI_OR_DATA : 23|8@0+ (1,0) [0|255] "" Vector__XXX
 SG_ CGW70F_1_0_DIAG_N_PCI_OR_DATA : 15|8@0+ (1,0) [0|255] "" Vector__XXX
 SG_ CGW70F_0_0_DIAG_N_PCI : 7|8@0+ (1,0) [0|255] "" Vector__XXX

BO_ 1774 CECU6EE: 8 C_ECU
 SG_ CECU6EE_7_0_DESTINATION_INFO : 57|2@0+ (1,0) [0|3] ""  DCM
 SG_ CECU6EE_7_4_VEHICLE_SERIES : 62|3@0+ (1,0) [0|7] ""  DCM,CCU
 SG_ CECU6EE_6_0_DESTINATION_CODE : 53|6@0+ (1,0) [0|37] ""  DCM,CCU
 SG_ CECU6EE_5_0_EYE_VERSION_INFO : 41|2@0+ (1,0) [0|3] ""  DCM
 SG_ CECU6EE_5_4_VEHICLE_TYPE : 44|1@0+ (1,0) [0|1] ""  DCM,CCU
 SG_ CECU6EE_5_6_PRODUCTION_BASE : 46|1@0+ (1,0) [0|1] "" Vector__XXX
 SG_ CECU6EE_4_2_WHEEL_DRIVE_TYPE : 34|1@0+ (1,0) [0|1] "" Vector__XXX
 SG_ CECU6EE_4_3_3RD_SHEAT_EQUIPMENT : 35|1@0+ (1,0) [0|1] ""  DCM
 SG_ CECU6EE_4_4_FLG_XMODE : 37|2@0+ (1,0) [0|3] ""  DCM
 SG_ CECU6EE_4_6_ISS_EQUIPMENT : 38|1@0+ (1,0) [0|1] ""  CCU
 SG_ CECU6EE_4_7_TIRE_INFO : 31|9@0+ (1,0) [0|381] "" Vector__XXX
 SG_ CECU6EE_2_3_TIRE_TYPE : 23|5@0+ (1,0) [0|511] "" Vector__XXX
 SG_ CECU6EE_1_0_MSG_COUNTER : 11|4@0+ (1,0) [0|15] ""  DCM,CCU
 SG_ CECU6EE_1_5_BEV_WHEEL_DRIVE_TYPE : 14|2@0+ (1,0) [0|3] ""  CCU
 SG_ CECU6EE_0_0_CHECK_SUM : 7|8@0+ (1,0) [0|255] ""  DCM,CCU

BO_ 1773 CECU6ED: 8 C_ECU
 SG_ CECU6ED_7_0_VEHICLE_TYPE_DETAIL : 59|4@0+ (1,0) [0|15] ""  DCM,CCU
 SG_ CECU6ED_7_7_STEERHEAT_EQUIPMENT : 63|1@0+ (1,0) [0|1] ""  CCU
 SG_ CECU6ED_6_0_SRH_EQUIPMENT : 48|1@0+ (1,0) [0|1] ""  CCU
 SG_ CECU6ED_6_1_EMBENAVI_EQUIPMENT : 49|1@0+ (1,0) [0|1] ""  CCU
 SG_ CECU6ED_6_2_RAB_EQUIPMENT_INFO : 50|1@0+ (1,0) [0|1] "" Vector__XXX
 SG_ CECU6ED_6_3_RRHEACON_EQUIPMENT : 51|1@0+ (1,0) [0|1] ""  CCU
 SG_ CECU6ED_6_4_AUTOMIRROR_EQUIPMENT : 52|1@0+ (1,0) [0|1] ""  CCU
 SG_ CECU6ED_6_5_SXMANTENNA_EQUIPMENT : 53|1@0+ (1,0) [0|1] ""  CCU
 SG_ CECU6ED_6_7_SPORTSCONT_EQUIPMENT : 55|1@0+ (1,0) [0|1] ""  CCU
 SG_ CECU6ED_5_0_TRANSMISSION_TYPE : 40|1@0+ (1,0) [0|1] ""  DCM,CCU
 SG_ CECU6ED_5_2_KICKSENSOR_EQUIPMENT : 42|1@0+ (1,0) [0|1] ""  CCU
 SG_ CECU6ED_5_3_RRSEAT_OCCUPANT : 43|1@0+ (1,0) [0|1] "" Vector__XXX
 SG_ CECU6ED_5_4_HANDLE : 44|1@0+ (1,0) [0|1] ""  DCM,CCU
 SG_ CECU6ED_5_5_RRWIPER_EQUIPMENT : 45|1@0+ (1,0) [0|1] ""  CCU
 SG_ CECU6ED_5_7_SRM_EQUIPMENT : 47|1@0+ (1,0) [0|1] ""  CCU
 SG_ CECU6ED_4_0_VEHICLE_HEIGHT : 34|3@0+ (1,0) [0|7] "" Vector__XXX
 SG_ CECU6ED_4_4_SEATHEATER_EQUIPMENT : 37|2@0+ (1,0) [0|3] ""  DCM,CCU
 SG_ CECU6ED_3_0_YEAR_CHANGE : 27|4@0+ (1,0) [0|15] ""  CCU
 SG_ CECU6ED_3_4_HEV_INFO : 30|3@0+ (1,0) [0|7] ""  DCM,CCU
 SG_ CECU6ED_2_0_RRDIFF_TEMPLAMP_INFO : 17|2@0+ (1,0) [0|3] "" Vector__XXX
 SG_ CECU6ED_2_2_AHL_EQUIPMENT : 19|2@0+ (1,0) [0|3] "" Vector__XXX
 SG_ CECU6ED_2_4_LSD_TYPE : 23|4@0+ (1,0) [0|15] "" Vector__XXX
 SG_ CECU6ED_1_0_MSG_COUNTER : 11|4@0+ (1,0) [0|15] ""  DCM,CCU
 SG_ CECU6ED_1_5_WARNINGBOX_EQUIPMENT : 13|1@0+ (1,0) [0|1] "" Vector__XXX
 SG_ CECU6ED_0_0_CHECK_SUM : 7|8@0+ (1,0) [0|255] ""  DCM,CCU

BO_ 1772 CECU6EC: 8 C_ECU
 SG_ CECU6EC_7_0_ACC_B_EQUIPMENT : 63|8@0+ (1,0) [0|255] "" Vector__XXX
 SG_ CECU6EC_6_0_SMT_EQUIPMENT : 48|1@0+ (1,0) [0|1] ""  CCU
 SG_ CECU6EC_6_1_DCCD_EQUIPMENT : 49|1@0+ (1,0) [0|1] "" Vector__XXX
 SG_ CECU6EC_6_2_PRG_EQUIPMENT : 50|1@0+ (1,0) [0|1] ""  CCU
 SG_ CECU6EC_6_3_DKY_EQUIPMENT : 51|1@0+ (1,0) [0|1] ""  CCU
 SG_ CECU6EC_6_4_PSC_EQUIPMENT : 52|1@0+ (1,0) [0|1] ""  CCU
 SG_ CECU6EC_6_5_ILLUM_EQUIPMENT : 53|1@0+ (1,0) [0|1] "" Vector__XXX
 SG_ CECU6EC_6_6_CAB_EQUIPMENT : 54|1@0+ (1,0) [0|1] "" Vector__XXX
 SG_ CECU6EC_6_7_ACC_A_EQUIPMENT : 55|1@0+ (1,0) [0|1] "" Vector__XXX
 SG_ CECU6EC_5_0_CCU_EQUIPMENT : 40|1@0+ (1,0) [0|1] "" Vector__XXX
 SG_ CECU6EC_5_1_EAM_EQUIPMENT : 41|1@0+ (1,0) [0|1] ""  CCU
 SG_ CECU6EC_5_2_RCR_L_EQUIPMENT : 42|1@0+ (1,0) [0|1] "" Vector__XXX
 SG_ CECU6EC_5_3_RCR_R_EQUIPMENT : 43|1@0+ (1,0) [0|1] "" Vector__XXX
 SG_ CECU6EC_5_4_FCR_L_EQUIPMENT : 44|1@0+ (1,0) [0|1] ""  CCU
 SG_ CECU6EC_5_5_FCR_R_EQUIPMENT : 45|1@0+ (1,0) [0|1] ""  CCU
 SG_ CECU6EC_5_6_VSS_EQUIPMENT : 46|1@0+ (1,0) [0|1] ""  CCU
 SG_ CECU6EC_5_7_RES_EQUIPMENT : 47|1@0+ (1,0) [0|1] "" Vector__XXX
 SG_ CECU6EC_4_0_LCT_EQUIPMENT : 32|1@0+ (1,0) [0|1] "" Vector__XXX
 SG_ CECU6EC_4_1_DAM_EQUIPMENT : 33|1@0+ (1,0) [0|1] "" Vector__XXX
 SG_ CECU6EC_4_2_MVS_EQUIPMENT : 34|1@0+ (1,0) [0|1] "" Vector__XXX
 SG_ CECU6EC_4_3_TCU_EQUIPMENT : 35|1@0+ (1,0) [0|1] "" Vector__XXX
 SG_ CECU6EC_4_4_TPM_EQUIPMENT : 36|1@0+ (1,0) [0|1] ""  CCU
 SG_ CECU6EC_4_5_DCM_EQUIPMENT : 37|1@0+ (1,0) [0|1] ""  CCU
 SG_ CECU6EC_4_6_MED_EQUIPMENT : 38|1@0+ (1,0) [0|1] "" Vector__XXX
 SG_ CECU6EC_4_7_MEP_EQUIPMENT : 39|1@0+ (1,0) [0|1] "" Vector__XXX
 SG_ CECU6EC_3_0_DATA_STATE : 24|1@0+ (1,0) [0|1] ""  CCU
 SG_ CECU6EC_3_1_EYE_EQUIPMENT : 25|1@0+ (1,0) [0|1] ""  CCU
 SG_ CECU6EC_3_2_HEV_EQUIPMENT : 26|1@0+ (1,0) [0|1] "" Vector__XXX
 SG_ CECU6EC_3_3_SNR_EQUIPMENT : 27|1@0+ (1,0) [0|1] "" Vector__XXX
 SG_ CECU6EC_3_4_EPB_EQUIPMENT : 28|1@0+ (1,0) [0|1] ""  CCU
 SG_ CECU6EC_3_5_DMS_EQUIPMENT : 29|1@0+ (1,0) [0|1] ""  CCU
 SG_ CECU6EC_3_6_BST_EQUIPMENT : 30|1@0+ (1,0) [0|1] "" Vector__XXX
 SG_ CECU6EC_3_7_MCA_EQUIPMENT : 31|1@0+ (1,0) [0|1] "" Vector__XXX
 SG_ CECU6EC_1_0_MSG_COUNTER : 11|4@0+ (1,0) [0|15] ""  DCM,CCU
 SG_ CECU6EC_0_0_CHECK_SUM : 7|8@0+ (1,0) [0|255] ""  DCM,CCU

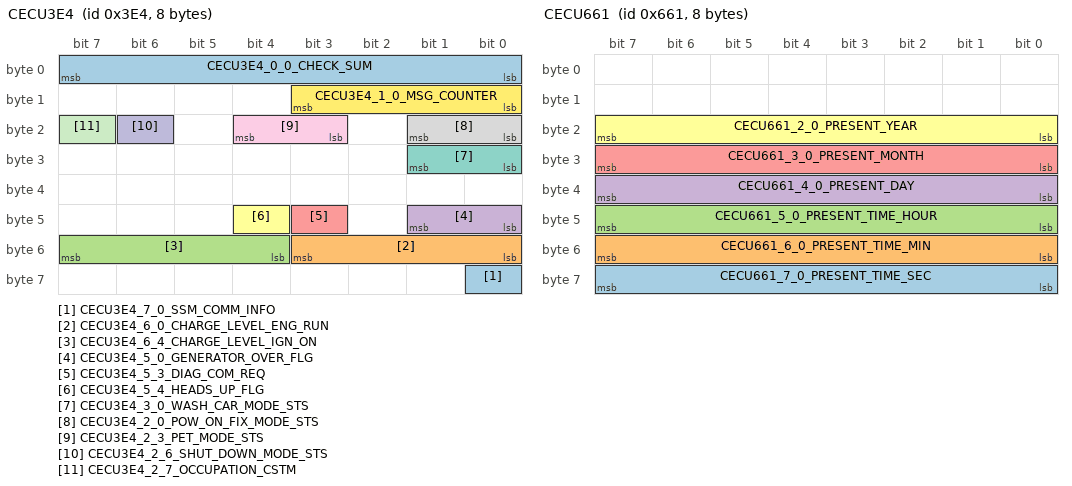
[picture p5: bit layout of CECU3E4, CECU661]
BO_ 996 CECU3E4: 8 C_ECU
 SG_ CECU3E4_7_0_SSM_COMM_INFO : 56|1@0+ (1,0) [0|1] "" Vector__XXX
 SG_ CECU3E4_6_0_CHARGE_LEVEL_ENG_RUN : 51|4@0+ (1,0) [0|9] "" Vector__XXX
 SG_ CECU3E4_6_4_CHARGE_LEVEL_IGN_ON : 55|4@0+ (1,0) [0|9] ""  CCU
 SG_ CECU3E4_5_0_GENERATOR_OVER_FLG : 41|2@0+ (1,0) [0|3] "" Vector__XXX
 SG_ CECU3E4_5_3_DIAG_COM_REQ : 43|1@0+ (1,0) [0|1] "" Vector__XXX
 SG_ CECU3E4_5_4_HEADS_UP_FLG : 44|1@0+ (1,0) [0|1] "" Vector__XXX
 SG_ CECU3E4_3_0_WASH_CAR_MODE_STS : 25|2@0+ (1,0) [0|3] "" Vector__XXX
 SG_ CECU3E4_2_0_POW_ON_FIX_MODE_STS : 17|2@0+ (1,0) [0|3] ""  CCU
 SG_ CECU3E4_2_3_PET_MODE_STS : 20|2@0+ (1,0) [0|3] ""  CCU
 SG_ CECU3E4_2_6_SHUT_DOWN_MODE_STS : 22|1@0+ (1,0) [0|1] ""  CCU
 SG_ CECU3E4_2_7_OCCUPATION_CSTM : 23|1@0+ (1,0) [0|1] ""  CCU
 SG_ CECU3E4_1_0_MSG_COUNTER : 11|4@0+ (1,0) [0|15] ""  CCU
 SG_ CECU3E4_0_0_CHECK_SUM : 7|8@0+ (1,0) [0|255] ""  CCU

BO_ 1280 CGW500: 8 C_ECU
 SG_ CGW500_1_4_ActiveWakeUpBit : 12|1@1+ (1,0) [0|1] ""  DCM,CCU
 SG_ CGW500_0_0_SourceNodeID : 0|8@1+ (1,0) [0|255] ""  DCM,CCU

BO_ 1633 CECU661: 8 C_ECU
 SG_ CECU661_7_0_PRESENT_TIME_SEC : 63|8@0+ (1,0) [0|89] "s"  DCM,CCU
 SG_ CECU661_6_0_PRESENT_TIME_MIN : 55|8@0+ (1,0) [0|89] "m"  DCM,CCU
 SG_ CECU661_5_0_PRESENT_TIME_HOUR : 47|8@0+ (1,0) [0|35] "h"  DCM,CCU
 SG_ CECU661_4_0_PRESENT_DAY : 39|8@0+ (1,0) [1|49] "Day"  DCM,CCU
 SG_ CECU661_3_0_PRESENT_MONTH : 31|8@0+ (1,0) [1|18] "Month"  DCM,CCU
 SG_ CECU661_2_0_PRESENT_YEAR : 23|8@0+ (1,0) [0|153] "Year"  DCM,CCU

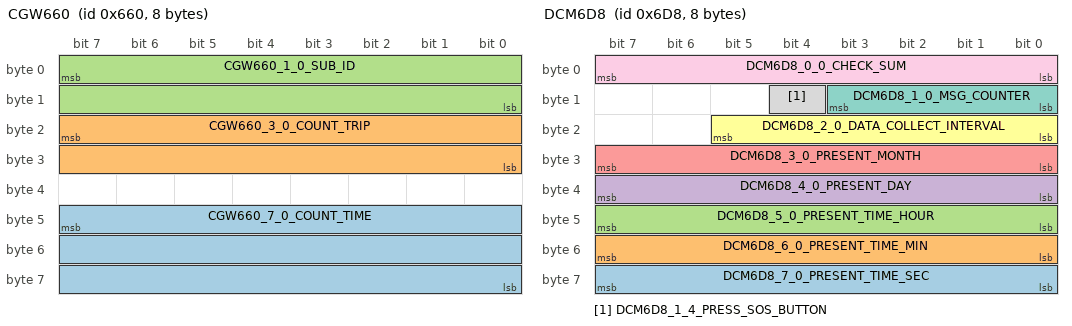
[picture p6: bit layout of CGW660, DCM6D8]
BO_ 1632 CGW660: 8 C_ECU
 SG_ CGW660_7_0_COUNT_TIME : 47|24@0+ (100,0) [0|1677721400] "ms"  DCM,CCU
 SG_ CGW660_3_0_COUNT_TRIP : 23|16@0+ (1,0) [0|65534] "trip"  DCM,CCU
 SG_ CGW660_1_0_SUB_ID : 7|16@0+ (1,0) [0|65535] ""  DCM

BO_ 1752 DCM6D8: 8 DCM
 SG_ DCM6D8_7_0_PRESENT_TIME_SEC : 56|8@1+ (1,0) [0|255] "s"  C_ECU_GW
 SG_ DCM6D8_6_0_PRESENT_TIME_MIN : 48|8@1+ (1,0) [0|255] "m"  C_ECU_GW
 SG_ DCM6D8_5_0_PRESENT_TIME_HOUR : 40|8@1+ (1,0) [0|255] "h"  C_ECU_GW
 SG_ DCM6D8_4_0_PRESENT_DAY : 32|8@1+ (1,0) [0|255] "Day"  C_ECU_GW
 SG_ DCM6D8_3_0_PRESENT_MONTH : 24|8@1+ (1,0) [0|255] "Month"  C_ECU_GW
 SG_ DCM6D8_2_0_DATA_COLLECT_INTERVAL : 16|6@1+ (1,0) [0|63] "min"  C_ECU_GW
 SG_ DCM6D8_1_0_MSG_COUNTER : 8|4@1+ (1,0) [0|15] ""  C_ECU_GW
 SG_ DCM6D8_1_4_PRESS_SOS_BUTTON : 12|1@1+ (1,0) [0|1] ""  C_ECU_GW
 SG_ DCM6D8_0_0_CHECK_SUM : 0|8@1+ (1,0) [0|255] ""  C_ECU_GW

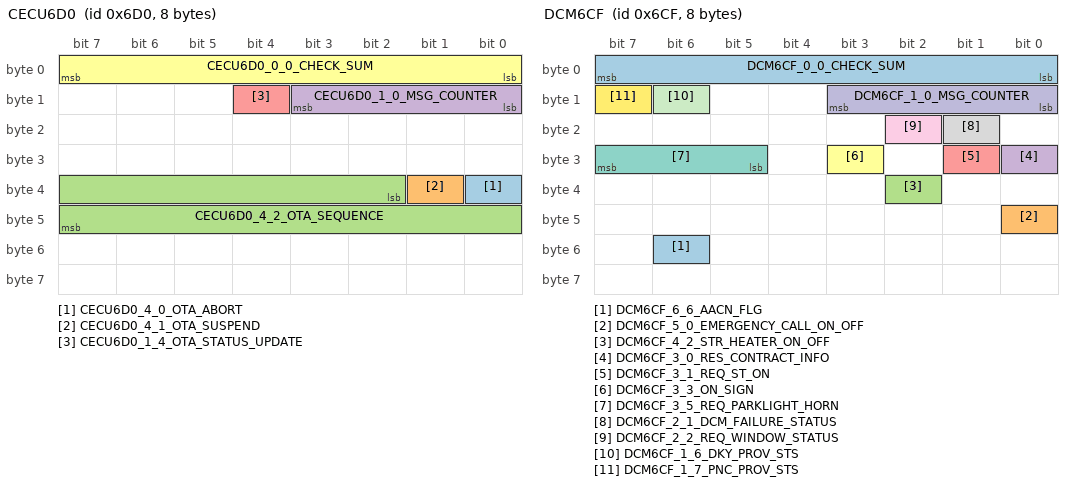
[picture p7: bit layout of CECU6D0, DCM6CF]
BO_ 1744 CECU6D0: 8 C_ECU
 SG_ CECU6D0_4_0_OTA_ABORT : 32|1@1+ (1,0) [0|1] ""  DCM
 SG_ CECU6D0_4_1_OTA_SUSPEND : 33|1@1+ (1,0) [0|1] ""  DCM
 SG_ CECU6D0_4_2_OTA_SEQUENCE : 34|14@1+ (1,0) [0|33170] ""  DCM
 SG_ CECU6D0_1_0_MSG_COUNTER : 8|4@1+ (1,0) [0|15] ""  DCM,CCU
 SG_ CECU6D0_1_4_OTA_STATUS_UPDATE : 12|1@1+ (1,0) [0|0] ""  CCU
 SG_ CECU6D0_0_0_CHECK_SUM : 0|8@1+ (1,0) [0|255] ""  DCM,CCU

BO_ 1743 DCM6CF: 8 DCM
 SG_ DCM6CF_6_6_AACN_FLG : 54|1@1+ (1,0) [0|1] ""  C_ECU_GW
 SG_ DCM6CF_5_0_EMERGENCY_CALL_ON_OFF : 40|1@1+ (1,0) [0|1] ""  C_ECU_GW
 SG_ DCM6CF_4_2_STR_HEATER_ON_OFF : 34|1@1+ (1,0) [0|1] ""  CCU,C_ECU_GW
 SG_ DCM6CF_3_0_RES_CONTRACT_INFO : 24|1@1+ (1,0) [0|1] ""  C_ECU_GW
 SG_ DCM6CF_3_1_REQ_ST_ON : 25|1@1+ (1,0) [0|1] ""  C_ECU_GW
 SG_ DCM6CF_3_3_ON_SIGN : 27|1@1+ (1,0) [0|1] ""  C_ECU_GW
 SG_ DCM6CF_3_5_REQ_PARKLIGHT_HORN : 29|3@1+ (1,0) [0|7] ""  C_ECU_GW
 SG_ DCM6CF_2_1_DCM_FAILURE_STATUS : 17|1@1+ (1,0) [0|1] ""  C_ECU,C_ECU_GW
 SG_ DCM6CF_2_2_REQ_WINDOW_STATUS : 18|1@1+ (1,0) [0|1] ""  C_ECU_GW
 SG_ DCM6CF_1_0_MSG_COUNTER : 8|4@1+ (1,0) [0|15] ""  CCU,C_ECU,C_ECU_GW
 SG_ DCM6CF_1_6_DKY_PROV_STS : 14|1@1+ (1,0) [0|1] ""  CCU,C_ECU,C_ECU_GW
 SG_ DCM6CF_1_7_PNC_PROV_STS : 15|1@1+ (1,0) [0|1] ""  C_ECU_GW
 SG_ DCM6CF_0_0_CHECK_SUM : 0|8@1+ (1,0) [0|255] ""  CCU,C_ECU,C_ECU_GW

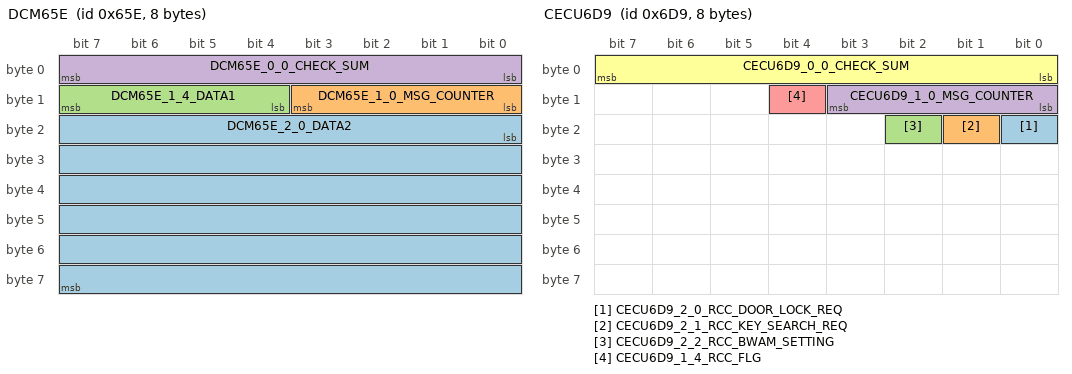
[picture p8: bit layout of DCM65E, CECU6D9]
BO_ 1630 DCM65E: 8 DCM
 SG_ DCM65E_2_0_DATA2 : 16|48@1+ (1,0) [0|281474976710660] ""  C_ECU_GW
 SG_ DCM65E_1_0_MSG_COUNTER : 8|4@1+ (1,0) [0|15] ""  C_ECU_GW
 SG_ DCM65E_1_4_DATA1 : 12|4@1+ (1,0) [0|15] ""  C_ECU_GW
 SG_ DCM65E_0_0_CHECK_SUM : 0|8@1+ (1,0) [0|255] ""  C_ECU_GW

BO_ 1301 DCM515: 8 DCM
 SG_ DCM515_1_4_ActiveWakeUpBit : 12|1@1+ (1,0) [0|1] ""  CCU,C_ECU
 SG_ DCM515_0_0_SourceNodeID : 0|8@1+ (1,0) [0|255] ""  CCU,C_ECU

BO_ 1749 CECU6D5: 8 C_ECU
 SG_ CECU6D5_6_0_CSTM_FMHD : 48|3@1+ (1,0) [0|7] ""  CCU
 SG_ CECU6D5_5_0_CSTM_WRH : 40|1@1+ (1,0) [0|1] ""  CCU
 SG_ CECU6D5_5_1_CSTM_LMHD : 41|2@1+ (1,0) [0|3] ""  CCU
 SG_ CECU6D5_5_3 : 43|2@1+ (1,0) [0|3] ""  CCU
 SG_ CECU6D5_5_5_CSTM_HBA : 45|2@1+ (1,0) [0|3] "" Vector__XXX
 SG_ CECU6D5_5_7_ADB_ACTIVE : 47|1@1+ (1,0) [0|1] "" Vector__XXX
 SG_ CECU6D5_4_0_JUDGE_ILL : 32|1@1+ (1,0) [0|1] "" Vector__XXX
 SG_ CECU6D5_4_1_HEADLAMP_AUTO_SW : 33|1@1+ (1,0) [0|1] ""  CCU
 SG_ CECU6D5_4_2_IND_ACTIVE_HBA : 34|2@1+ (1,0) [0|3] "" Vector__XXX
 SG_ CECU6D5_4_4_FGT_LGTOFF_WARNING : 36|1@1+ (1,0) [0|1] "" Vector__XXX
 SG_ CECU6D5_3_0_CRN_R_REQ : 24|2@1+ (1,0) [0|3] "" Vector__XXX
 SG_ CECU6D5_3_2_CRN_L_REQ : 26|2@1+ (1,0) [0|3] "" Vector__XXX
 SG_ CECU6D5_3_4_FMH : 28|1@1+ (1,0) [0|1] "" Vector__XXX
 SG_ CECU6D5_3_5_LMH : 29|1@1+ (1,0) [0|1] "" Vector__XXX
 SG_ CECU6D5_2_0_LGT_1 : 16|1@1+ (1,0) [0|1] "" Vector__XXX
 SG_ CECU6D5_2_1_LGT_LO : 17|1@1+ (1,0) [0|1] "" Vector__XXX
 SG_ CECU6D5_2_2_LGT_HI : 18|2@1+ (1,0) [0|1] "" Vector__XXX
 SG_ CECU6D5_2_4_FFOG_RELAY_REQ : 20|1@1+ (1,0) [0|1] "" Vector__XXX
 SG_ CECU6D5_2_5_RFOG_RELAY_REQ : 21|1@1+ (1,0) [0|1] "" Vector__XXX
 SG_ CECU6D5_2_6_LGT_DRL : 22|1@1+ (1,0) [0|1] "" Vector__XXX
 SG_ CECU6D5_1_0_MSG_COUNTER : 8|4@1+ (1,0) [0|15] ""  CCU
 SG_ CECU6D5_0_0_CHECK_SUM : 0|8@1+ (1,0) [0|255] ""  CCU

BO_ 1753 CECU6D9: 8 C_ECU
 SG_ CECU6D9_2_0_RCC_DOOR_LOCK_REQ : 16|1@1+ (1,0) [0|1] "" Vector__XXX
 SG_ CECU6D9_2_1_RCC_KEY_SEARCH_REQ : 17|1@1+ (1,0) [0|1] "" Vector__XXX
 SG_ CECU6D9_2_2_RCC_BWAM_SETTING : 18|1@1+ (1,0) [0|1] "" Vector__XXX
 SG_ CECU6D9_1_0_MSG_COUNTER : 8|4@1+ (1,0) [0|15] ""  DCM
 SG_ CECU6D9_1_4_RCC_FLG : 12|1@1+ (1,0) [0|1] ""  DCM,CCU
 SG_ CECU6D9_0_0_CHECK_SUM : 0|8@1+ (1,0) [0|255] ""  DCM

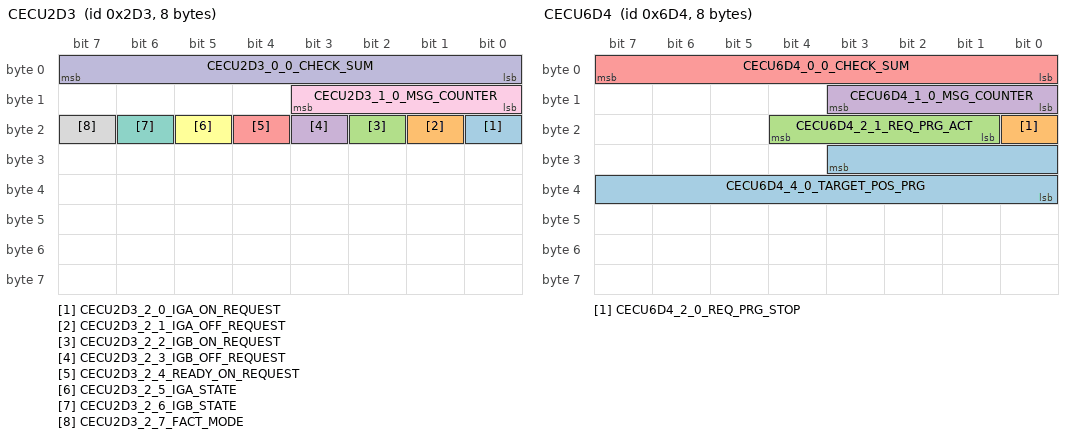
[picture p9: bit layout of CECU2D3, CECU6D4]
BO_ 723 CECU2D3: 8 C_ECU
 SG_ CECU2D3_2_0_IGA_ON_REQUEST : 16|1@1+ (1,0) [0|1] "" Vector__XXX
 SG_ CECU2D3_2_1_IGA_OFF_REQUEST : 17|1@1+ (1,0) [0|1] "" Vector__XXX
 SG_ CECU2D3_2_2_IGB_ON_REQUEST : 18|1@1+ (1,0) [0|1] "" Vector__XXX
 SG_ CECU2D3_2_3_IGB_OFF_REQUEST : 19|1@1+ (1,0) [0|1] "" Vector__XXX
 SG_ CECU2D3_2_4_READY_ON_REQUEST : 20|1@1+ (1,0) [0|1] "" Vector__XXX
 SG_ CECU2D3_2_5_IGA_STATE : 21|1@1+ (1,0) [0|1] ""  DCM,CCU
 SG_ CECU2D3_2_6_IGB_STATE : 22|1@1+ (1,0) [0|1] ""  DCM,CCU
 SG_ CECU2D3_2_7_FACT_MODE : 23|1@1+ (1,0) [0|1] "" Vector__XXX
 SG_ CECU2D3_1_0_MSG_COUNTER : 8|4@1+ (1,0) [0|15] ""  DCM
 SG_ CECU2D3_0_0_CHECK_SUM : 0|8@1+ (1,0) [0|255] ""  DCM

BO_ 1748 CECU6D4: 8 C_ECU
 SG_ CECU6D4_4_0_TARGET_POS_PRG : 27|12@0+ (1,0) [0|4095] "" Vector__XXX
 SG_ CECU6D4_2_0_REQ_PRG_STOP : 16|1@0+ (1,0) [0|1] "" Vector__XXX
 SG_ CECU6D4_2_1_REQ_PRG_ACT : 20|4@0+ (1,0) [0|5] "" Vector__XXX
 SG_ CECU6D4_1_0_MSG_COUNTER : 11|4@0+ (1,0) [0|15] "" Vector__XXX
 SG_ CECU6D4_0_0_CHECK_SUM : 7|8@0+ (1,0) [0|255] "" Vector__XXX

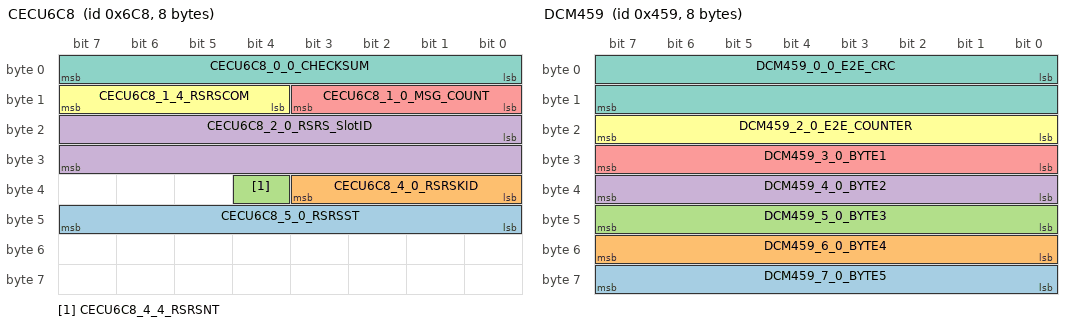
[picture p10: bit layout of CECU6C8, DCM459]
BO_ 1736 CECU6C8: 8 C_ECU
 SG_ CECU6C8_5_0_RSRSST : 40|8@1+ (1,0) [0|255] ""  DCM
 SG_ CECU6C8_4_0_RSRSKID : 32|4@1+ (1,0) [0|15] ""  DCM
 SG_ CECU6C8_4_4_RSRSNT : 36|1@1+ (1,0) [0|1] ""  DCM
 SG_ CECU6C8_2_0_RSRS_SlotID : 16|16@1+ (1,0) [0|65535] ""  DCM
 SG_ CECU6C8_1_0_MSG_COUNT : 8|4@1+ (1,0) [0|15] ""  DCM
 SG_ CECU6C8_1_4_RSRSCOM : 12|4@1+ (1,0) [0|14] ""  DCM
 SG_ CECU6C8_0_0_CHECKSUM : 0|8@1+ (1,0) [0|255] ""  DCM

BO_ 1701 CECU6A5: 32 C_ECU
 SG_ CECU6A5_10_0_DCM_SHUTDOWN_RESULT : 81|2@0+ (1,0) [0|3] ""  DCM
 SG_ CECU6A5_8_0_NOTIFICATION_REQ : 63|16@0+ (1,0) [0|65535] ""  DCM
 SG_ CECU6A5_6_0_VEHICLE_STATE_INFO : 55|8@0+ (1,0) [0|17] ""  DCM
 SG_ CECU6A5_5_0_ALERT_FACTOR : 39|16@0+ (1,0) [0|65535] ""  DCM
 SG_ CECU6A5_3_0_TARGET_FUNC : 31|8@0+ (1,0) [0|4] ""  DCM
 SG_ CECU6A5_2_0_E2E_COUNTER : 23|8@0+ (1,0) [0|255] ""  DCM
 SG_ CECU6A5_1_0_E2E_CRC : 7|16@0+ (1,0) [0|65535] ""  DCM

BO_ 1699 CECU6A3: 8 C_ECU
 SG_ CECU6A3_7_4_ACC4ONOFF : 60|1@1+ (1,0) [0|0] "" Vector__XXX
 SG_ CECU6A3_7_5_ACC3ONOFF : 61|1@1+ (1,0) [0|0] "" Vector__XXX
 SG_ CECU6A3_7_6_ACC2ONOFF : 62|1@1+ (1,0) [0|0] "" Vector__XXX
 SG_ CECU6A3_7_7_ACC1ONOFF : 63|1@1+ (1,0) [0|0] "" Vector__XXX
 SG_ CECU6A3_6_0_CAB_SYSC_EQUIPMENT : 48|1@1+ (1,0) [0|0] "" Vector__XXX
 SG_ CECU6A3_6_1_CAB_SYSB_EQUIPMENT : 49|1@1+ (1,0) [0|0] "" Vector__XXX
 SG_ CECU6A3_6_2_CAB_SYSA_EQUIPMENT : 50|1@1+ (1,0) [0|0] "" Vector__XXX
 SG_ CECU6A3_6_3_CAB_EQUIPMENT : 51|1@1+ (1,0) [0|0] "" Vector__XXX
 SG_ CECU6A3_6_4_ACC_B_ONOFF : 52|1@1+ (1,0) [0|0] "" Vector__XXX
 SG_ CECU6A3_6_5_ACC_B_EQUIPMENT : 53|1@1+ (1,0) [0|0] "" Vector__XXX
 SG_ CECU6A3_6_6_ACC_A_ONOFF : 54|1@1+ (1,0) [0|0] "" Vector__XXX
 SG_ CECU6A3_6_7_ACC_A_EQUIPMENT : 55|1@1+ (1,0) [0|0] "" Vector__XXX
 SG_ CECU6A3_5_0_AMBI_ILLUM_SPEC : 40|1@1+ (1,0) [0|0] ""  CCU
 SG_ CECU6A3_4_6_SI_DRIVE_S : 38|1@1+ (1,0) [0|0] "" Vector__XXX
 SG_ CECU6A3_4_5_SI_DRIVE_I : 37|1@1+ (1,0) [0|0] "" Vector__XXX
 SG_ CECU6A3_4_4_SI_DRIVE_ECO : 36|1@1+ (1,0) [0|0] "" Vector__XXX
 SG_ CECU6A3_4_3_TOWING_OPT : 35|1@1+ (1,0) [0|0] ""  CCU
 SG_ CECU6A3_3_4_MOTOR_GENERAT_OUTPUT : 28|1@1+ (1,0) [0|0] "" Vector__XXX
 SG_ CECU6A3_3_0_HIGH_VOLT_CAPACITY : 24|1@1+ (1,0) [0|0] "" Vector__XXX
 SG_ CECU6A3_2_4_REAR_WHEEL_STEER : 20|1@1+ (1,0) [0|0] "" Vector__XXX
 SG_ CECU6A3_2_0_POWER_CHARGE : 16|1@1+ (1,0) [0|0] ""  CCU
 SG_ CECU6A3_1_5_ACOUTLET_EQUIPMENT : 13|1@1+ (1,0) [0|0] ""  CCU
 SG_ CECU6A3_1_0_MSG_COUNTER : 8|1@1+ (1,0) [0|0] ""  CCU
 SG_ CECU6A3_0_0_CHECK_SUM : 0|1@1+ (1,0) [0|0] ""  CCU

BO_ 1739 DCM6CB: 8 DCM
 SG_ DCM6CB_7_0 : 56|40@1+ (1,0) [0|1099511627775] ""  C_ECU_GW
 SG_ DCM6CB_5_0_DKY_SLOT_ID : 40|16@1+ (1,0) [0|65535] ""  C_ECU,C_ECU_GW
 SG_ DCM6CB_4_0_DKY_COM_REQ : 32|4@1+ (1,0) [0|18] ""  C_ECU,C_ECU_GW
 SG_ DCM6CB_3_5_PNC_SW_REQ_SRV : 29|3@1+ (1,0) [0|5] ""  CCU,C_ECU_GW
 SG_ DCM6CB_2_0_SHUTDOWN_REQ : 16|1@1+ (1,0) [0|1] ""  C_ECU,C_ECU_GW
 SG_ DCM6CB_2_3_IGB_OFF_REQUEST : 19|1@1+ (1,0) [0|1] ""  C_ECU,C_ECU_GW
 SG_ DCM6CB_2_4_IGB_ON_REQUEST : 20|1@1+ (1,0) [0|1] ""  C_ECU,C_ECU_GW
 SG_ DCM6CB_2_5_REARGATE_UNLOCK_REQ : 21|1@1+ (1,0) [0|1] ""  C_ECU_GW
 SG_ DCM6CB_2_6_DOOR_UNLOCK_REQ : 22|1@1+ (1,0) [0|1] ""  C_ECU_GW
 SG_ DCM6CB_2_7_DOOR_LOCK_REQUEST : 23|1@1+ (1,0) [0|1] ""  C_ECU_GW
 SG_ DCM6CB_1_0_MSG_COUNTER : 8|4@1+ (1,0) [0|15] ""  C_ECU,C_ECU_GW
 SG_ DCM6CB_1_4_REQ_SVR_HAZARD_ON : 12|1@1+ (1,0) [0|1] ""  C_ECU_GW
 SG_ DCM6CB_1_5_HORNHZRD_DEACT_REQ : 13|1@1+ (1,0) [0|1] ""  C_ECU_GW
 SG_ DCM6CB_1_6_HAZARD_ACT_REQ : 14|1@1+ (1,0) [0|1] ""  C_ECU_GW
 SG_ DCM6CB_1_7_HORNHAZARD_ACT_REQ : 15|1@1+ (1,0) [0|1] ""  C_ECU_GW
 SG_ DCM6CB_0_0_CHECK_SUM : 0|8@1+ (1,0) [0|255] ""  C_ECU,C_ECU_GW

BO_ 1155 DCM483: 32 DCM
 SG_ DCM483_18_0_DEP_TIM4_WEEKDAY_REQ : 144|8@1+ (1,0) [0|255] ""  CCU
 SG_ DCM483_16_0_DEP_TIM4_ST_TIME_REQ : 128|11@1+ (1,0) [0|1439] "min"  CCU
 SG_ DCM483_15_5_DEP_TIM4_SW_REQ : 125|2@1+ (1,0) [0|3] ""  CCU
 SG_ DCM483_15_7_DEP_TIM4_PERFLG_REQ : 127|1@1+ (1,0) [0|1] ""  CCU
 SG_ DCM483_14_0_DEP_TIM3_WEEKDAY_REQ : 112|8@1+ (1,0) [0|255] ""  CCU
 SG_ DCM483_12_0_DEP_TIM3_ST_TIME_REQ : 96|11@1+ (1,0) [0|1439] "min"  CCU
 SG_ DCM483_11_5_DEP_TIM3_SW_REQ : 93|2@1+ (1,0) [0|3] ""  CCU
 SG_ DCM483_11_7_DEP_TIM3_PERFLG_REQ : 95|1@1+ (1,0) [0|1] ""  CCU
 SG_ DCM483_10_0_DEP_TIM2_WEEKDAY_REQ : 80|8@1+ (1,0) [0|255] ""  CCU
 SG_ DCM483_8_0_DEP_TIM2_ST_TIME_REQ : 64|11@1+ (1,0) [0|1439] "min"  CCU
 SG_ DCM483_7_7_DEP_TIM2_PERFLG_REQ : 57|1@1+ (1,0) [0|1] ""  CCU
 SG_ DCM483_7_5_DEP_TIM2_SW_REQ : 61|2@1+ (1,0) [0|3] ""  CCU
 SG_ DCM483_6_0_DEP_TIM1_WEEKDAY_REQ : 48|8@1+ (1,0) [0|255] ""  CCU
 SG_ DCM483_4_0_DEP_TIM1_ST_TIME_REQ : 32|11@1+ (1,0) [0|1439] "min"  CCU
 SG_ DCM483_3_5_DEP_TIM1_SW_REQ : 29|2@1+ (1,0) [0|3] ""  CCU
 SG_ DCM483_3_7_DEP_TIM1_PERFLG_REQ : 31|1@1+ (1,0) [0|1] ""  CCU
 SG_ DCM483_2_0_E2E_COUNTER : 16|8@1+ (1,0) [0|255] ""  CCU
 SG_ DCM483_0_0_E2E_CRC : 0|16@1+ (1,0) [0|65535] ""  CCU

BO_ 1154 DCM482: 32 DCM
 SG_ DCM482_30_0_CHG_BTN_SET_REQ : 240|3@1+ (1,0) [0|3] ""  CCU
 SG_ DCM482_29_0_FED_LOLMT_REQ : 232|8@1+ (1,0) [0|255] "0.01"  CCU
 SG_ DCM482_28_0_ACCHG_CURUPLMT_REQ : 224|4@1+ (1,0) [0|15] ""  CCU
 SG_ DCM482_28_4_DCCHG_PWRUPLMT_REQ : 228|4@1+ (1,0) [0|15] ""  CCU
 SG_ DCM482_27_0_CHG_HILMT_REQ : 216|7@1+ (1,0) [0|127] ""  CCU
 SG_ DCM482_26_0_TIM4_CHG_WEEKDAY_REQ : 208|8@1+ (1,0) [0|255] ""  CCU
 SG_ DCM482_24_0_TIM4_CHG_ENDTIME_REQ : 192|11@1+ (1,0) [0|1439] "min"  CCU
 SG_ DCM482_22_0_TIM4_CHG_SETTYPE_REQ : 176|2@1+ (1,0) [0|2] ""  CCU
 SG_ DCM482_22_2_TIM4_CHG_ST_TIME_REQ : 178|11@1+ (1,0) [0|1439] "min"  CCU
 SG_ DCM482_21_5_TIM4_CHG_SW_REQ : 173|2@1+ (1,0) [0|3] ""  CCU
 SG_ DCM482_20_0_TIM3_CHG_WEEKDAY_REQ : 160|8@1+ (1,0) [0|255] ""  CCU
 SG_ DCM482_18_0_TIM3_CHG_ENDTIME_REQ : 144|11@1+ (1,0) [0|1439] "min"  CCU
 SG_ DCM482_16_0_TIM3_CHG_SETTYPE_REQ : 128|2@1+ (1,0) [0|2] ""  CCU
 SG_ DCM482_16_2_TIM3_CHG_ST_TIME_REQ : 130|11@1+ (1,0) [0|1439] "min"  CCU
 SG_ DCM482_15_5_TIM3_CHG_SW_REQ : 125|2@1+ (1,0) [0|3] ""  CCU
 SG_ DCM482_14_0_TIM2_CHG_WEEKDAY_REQ : 112|8@1+ (1,0) [0|255] ""  CCU
 SG_ DCM482_12_0_TIM2_CHG_ENDTIME_REQ : 96|11@1+ (1,0) [0|1439] "min"  CCU
 SG_ DCM482_10_0_TIM2_CHG_SETTYPE_REQ : 80|2@1+ (1,0) [0|2] ""  CCU
 SG_ DCM482_10_2_TIM2_CHG_ST_TIME_REQ : 82|11@1+ (1,0) [0|1439] "min"  CCU
 SG_ DCM482_9_5_TIM2_CHG_SW_REQ : 77|2@1+ (1,0) [0|3] ""  CCU
 SG_ DCM482_8_0_TIM1_CHG_WEEKDAY_REQ : 64|8@1+ (1,0) [0|255] ""  CCU
 SG_ DCM482_6_0_TIM1_CHG_ENDTIME_REQ : 48|11@1+ (1,0) [0|1439] "min"  CCU
 SG_ DCM482_4_0_TIM1_CHG_SETTYPE_REQ : 32|2@1+ (1,0) [0|2] ""  CCU
 SG_ DCM482_4_2_TIM1_CHG_ST_TIME_REQ : 34|11@1+ (1,0) [0|1439] "min"  CCU
 SG_ DCM482_3_5_TIM1_CHG_SW_REQ : 29|2@1+ (1,0) [0|3] ""  CCU
 SG_ DCM482_2_0_E2E_COUNTER : 16|8@1+ (1,0) [0|255] ""  CCU
 SG_ DCM482_0_0_E2E_CRC : 0|16@1+ (1,0) [0|65535] ""  CCU

BO_ 1113 DCM459: 8 DCM
 SG_ DCM459_7_0_BYTE5 : 56|8@1+ (1,0) [0|255] ""  C_ECU_GW
 SG_ DCM459_6_0_BYTE4 : 48|8@1+ (1,0) [0|255] ""  C_ECU_GW
 SG_ DCM459_5_0_BYTE3 : 40|8@1+ (1,0) [0|255] ""  C_ECU_GW
 SG_ DCM459_4_0_BYTE2 : 32|8@1+ (1,0) [0|255] ""  C_ECU_GW
 SG_ DCM459_3_0_BYTE1 : 24|8@1+ (1,0) [0|255] ""  C_ECU_GW
 SG_ DCM459_2_0_E2E_COUNTER : 16|8@1+ (1,0) [0|255] ""  C_ECU_GW
 SG_ DCM459_0_0_E2E_CRC : 0|16@1+ (1,0) [0|65535] ""  C_ECU_GW

BO_ 1107 DCM453: 32 DCM
 SG_ DCM453_31_0_BYTE29 : 248|8@1+ (1,0) [0|255] ""  C_ECU_GW
 SG_ DCM453_30_0_BYTE28 : 240|8@1+ (1,0) [0|255] ""  C_ECU_GW
 SG_ DCM453_29_0_BYTE27 : 232|8@1+ (1,0) [0|255] ""  C_ECU_GW
 SG_ DCM453_28_0_BYTE26 : 224|8@1+ (1,0) [0|255] ""  C_ECU_GW
 SG_ DCM453_27_0_BYTE25 : 216|8@1+ (1,0) [0|255] ""  C_ECU_GW
 SG_ DCM453_26_0_BYTE24 : 208|8@1+ (1,0) [0|255] ""  C_ECU_GW
 SG_ DCM453_25_0_BYTE23 : 200|8@1+ (1,0) [0|255] ""  C_ECU_GW
 SG_ DCM453_24_0_BYTE22 : 192|8@1+ (1,0) [0|255] ""  C_ECU_GW
 SG_ DCM453_23_0_BYTE21 : 184|8@1+ (1,0) [0|255] ""  C_ECU_GW
 SG_ DCM453_22_0_BYTE20 : 176|8@1+ (1,0) [0|255] ""  C_ECU_GW
 SG_ DCM453_21_0_BYTE19 : 168|8@1+ (1,0) [0|255] ""  C_ECU_GW
 SG_ DCM453_20_0_BYTE18 : 160|8@1+ (1,0) [0|255] ""  C_ECU_GW
 SG_ DCM453_19_0_BYTE17 : 152|8@1+ (1,0) [0|255] ""  C_ECU_GW
 SG_ DCM453_18_0_BYTE16 : 144|8@1+ (1,0) [0|255] ""  C_ECU_GW
 SG_ DCM453_17_0_BYTE15 : 136|8@1+ (1,0) [0|255] ""  C_ECU_GW
 SG_ DCM453_16_0_BYTE14 : 128|8@1+ (1,0) [0|255] ""  C_ECU_GW
 SG_ DCM453_15_0_BYTE13 : 120|8@1+ (1,0) [0|255] ""  C_ECU_GW
 SG_ DCM453_14_0_BYTE12 : 112|8@1+ (1,0) [0|255] ""  C_ECU_GW
 SG_ DCM453_13_0_BYTE11 : 104|8@1+ (1,0) [0|255] ""  C_ECU_GW
 SG_ DCM453_12_0_BYTE10 : 96|8@1+ (1,0) [0|255] ""  C_ECU_GW
 SG_ DCM453_11_0_BYTE9 : 88|8@1+ (1,0) [0|255] ""  C_ECU_GW
 SG_ DCM453_10_0_BYTE8 : 80|8@1+ (1,0) [0|255] ""  C_ECU_GW
 SG_ DCM453_9_0_BYTE7 : 72|8@1+ (1,0) [0|255] ""  C_ECU_GW
 SG_ DCM453_8_0_BYTE6 : 64|8@1+ (1,0) [0|255] ""  C_ECU_GW
 SG_ DCM453_7_0_BYTE5 : 56|8@1+ (1,0) [0|255] ""  C_ECU_GW
 SG_ DCM453_6_0_BYTE4 : 48|8@1+ (1,0) [0|255] ""  C_ECU_GW
 SG_ DCM453_5_0_BYTE3 : 40|8@1+ (1,0) [0|255] ""  C_ECU_GW
 SG_ DCM453_4_0_BYTE2 : 32|8@1+ (1,0) [0|255] ""  C_ECU_GW
 SG_ DCM453_3_0_BYTE1 : 24|8@1+ (1,0) [0|255] ""  C_ECU_GW
 SG_ DCM453_2_0_E2E_COUNTER : 16|8@1+ (1,0) [0|255] ""  C_ECU_GW
 SG_ DCM453_0_0_E2E_CRC : 0|16@1+ (1,0) [0|65535] ""  C_ECU_GW

BO_ 1705 MVS6A9: 8 C_ECU_GW
 SG_ MVS6A9_6_0_CSTM_HITCHLINE_DSPREQ : 48|2@1+ (1,0) [0|3] ""  CCU
 SG_ MVS6A9_6_2_CSTM_HITCHLINE : 50|1@1+ (1,0) [0|1] ""  CCU
 SG_ MVS6A9_5_0_RR_WIDE_VIEW_SW_STATE : 40|2@1+ (1,0) [0|3] ""  CCU
 SG_ MVS6A9_5_2_RR_NRW_VIEW_SW_STATE : 42|2@1+ (1,0) [0|3] ""  CCU
 SG_ MVS6A9_5_4_HITCH_VIEW_SW_STATE : 44|2@1+ (1,0) [0|3] ""  CCU
 SG_ MVS6A9_4_0_FT_NRW_VIEW_SW_STATE : 32|2@1+ (1,0) [0|3] ""  CCU
 SG_ MVS6A9_4_2_FT_WIDE_VIEW_SW_STATE : 34|2@1+ (1,0) [0|3] ""  CCU
 SG_ MVS6A9_4_4_SIDE_VIEW_SW_STATE : 36|2@1+ (1,0) [0|3] ""  CCU
 SG_ MVS6A9_4_6_3D_VIEW_SW_STATE : 38|2@1+ (1,0) [0|3] ""  CCU
 SG_ MVS6A9_3_0_CSTM_AUTO_DISPLAY_SET : 24|1@1+ (1,0) [0|1] ""  CCU
 SG_ MVS6A9_3_1_CSTM_AUTO_DISPLAY : 25|1@1+ (1,0) [0|1] ""  CCU
 SG_ MVS6A9_3_2_VIEW_MODE : 26|3@1+ (1,0) [0|3] ""  CCU
 SG_ MVS6A9_3_5_STOP_SWITCH : 29|1@1+ (1,0) [0|1] ""  CCU
 SG_ MVS6A9_3_6_CSTM_HITCH_VIEW : 30|1@1+ (1,0) [0|1] ""  CCU
 SG_ MVS6A9_2_0_CURRENT_VIEW : 16|5@1+ (1,0) [0|31] ""  CCU
 SG_ MVS6A9_2_5_HOLD_TIME : 21|1@1+ (1,0) [0|1] ""  CCU
 SG_ MVS6A9_1_0_MSG_COUNTER : 8|4@1+ (1,0) [0|15] ""  CCU
 SG_ MVS6A9_1_4_FAIL_MVS : 12|1@1+ (1,0) [0|1] ""  CCU
 SG_ MVS6A9_1_5_FAIL_MVS_CAUSE : 13|3@1+ (1,0) [0|7] "" Vector__XXX
 SG_ MVS6A9_0_0_CHECK_SUM : 0|8@1+ (1,0) [0|255] ""  CCU

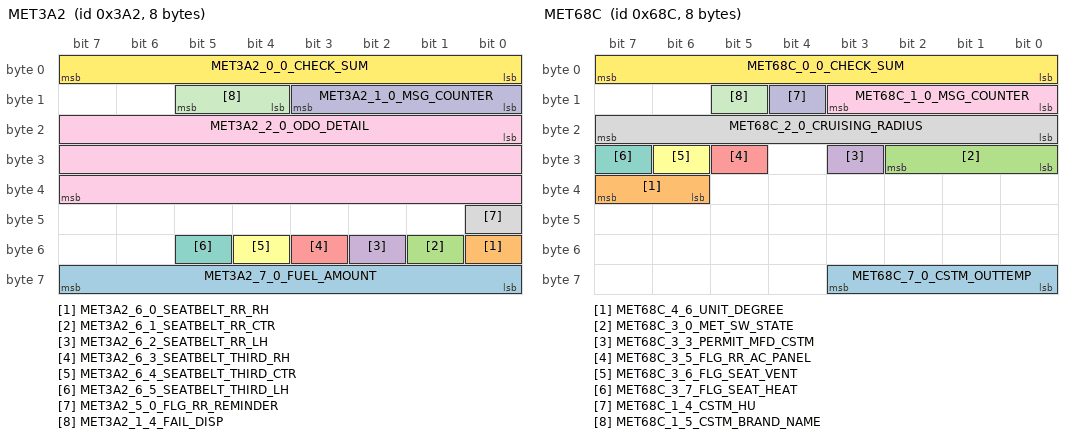
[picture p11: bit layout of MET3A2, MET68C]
BO_ 930 MET3A2: 8 C_ECU_GW
 SG_ MET3A2_7_0_FUEL_AMOUNT : 56|8@1+ (1,0) [0|100] "%" Vector__XXX
 SG_ MET3A2_6_0_SEATBELT_RR_RH : 48|1@1+ (1,0) [0|1] ""  CCU
 SG_ MET3A2_6_1_SEATBELT_RR_CTR : 49|1@1+ (1,0) [0|1] ""  CCU
 SG_ MET3A2_6_2_SEATBELT_RR_LH : 50|1@1+ (1,0) [0|1] ""  CCU
 SG_ MET3A2_6_3_SEATBELT_THIRD_RH : 51|1@1+ (1,0) [0|1] ""  CCU
 SG_ MET3A2_6_4_SEATBELT_THIRD_CTR : 52|1@1+ (1,0) [0|1] ""  CCU
 SG_ MET3A2_6_5_SEATBELT_THIRD_LH : 53|1@1+ (1,0) [0|1] ""  CCU
 SG_ MET3A2_5_0_FLG_RR_REMINDER : 40|1@1+ (1,0) [0|1] "" Vector__XXX
 SG_ MET3A2_2_0_ODO_DETAIL : 16|24@1+ (0.1,0) [0|1609103.5] "km" Vector__XXX
 SG_ MET3A2_1_0_MSG_COUNTER : 8|4@1+ (1,0) [0|15] "" Vector__XXX
 SG_ MET3A2_1_4_FAIL_DISP : 12|2@1+ (1,0) [0|3] ""  CCU
 SG_ MET3A2_0_0_CHECK_SUM : 0|8@1+ (1,0) [0|255] "" Vector__XXX

BO_ 1677 MET68D: 8 C_ECU_GW
 SG_ MET68D_7_0_STATUS_WASHER_LAMP : 56|1@1+ (1,0) [0|1] ""  DCM
 SG_ MET68D_7_1_OILPRESSURE_SW : 57|1@1+ (1,0) [0|1] "" Vector__XXX
 SG_ MET68D_7_2_FLG_EAM : 58|1@1+ (1,0) [0|1] "" Vector__XXX
 SG_ MET68D_7_3_CSTM_IND_RED : 59|1@1+ (1,0) [0|1] "" Vector__XXX
 SG_ MET68D_7_4_CSTM_IND_YELLOW : 60|1@1+ (1,0) [0|1] "" Vector__XXX
 SG_ MET68D_7_5_CSTM_IND_GREEN : 61|1@1+ (1,0) [0|1] "" Vector__XXX
 SG_ MET68D_7_6_REQ_CSTM_SRH : 62|1@1+ (1,0) [0|1] "" Vector__XXX
 SG_ MET68D_7_7_CSTM_SRH : 63|1@1+ (1,0) [0|1] "" Vector__XXX
 SG_ MET68D_6_5_REQ_CHG_CSTM_RAB : 53|1@1+ (1,0) [0|1] "" Vector__XXX
 SG_ MET68D_6_6_CSTM_RAB : 54|1@1+ (1,0) [0|1] "" Vector__XXX
 SG_ MET68D_6_7_CSTM_SONNER : 55|1@1+ (1,0) [0|1] "" Vector__XXX
 SG_ MET68D_5_0_TEMP_FOR_PPA : 40|13@1- (0.1,-400) [-400|419.1] "℃" Vector__XXX
 SG_ MET68D_2_0_ODO : 16|24@1+ (0.1,0) [0|999999.9] "km"  DCM,CCU
 SG_ MET68D_1_0_MSG_COUNTER : 8|4@1+ (1,0) [0|15] ""  DCM,CCU
 SG_ MET68D_1_4_RESET_CSTM_TPMS_RAEB : 12|1@1+ (1,0) [0|1] "" Vector__XXX
 SG_ MET68D_1_5_REQ_CHG_CSTM_TPMS : 13|1@1+ (1,0) [0|1] "" Vector__XXX
 SG_ MET68D_1_6_CSTM_TIRE_UNIT : 14|2@1+ (1,0) [0|3] "" Vector__XXX
 SG_ MET68D_0_0_CHECK_SUM : 0|8@1+ (1,0) [0|255] ""  DCM,CCU

BO_ 1676 MET68C: 8 C_ECU_GW
 SG_ MET68C_7_0_CSTM_OUTTEMP : 56|4@1+ (1,0) [0|15] "℃" Vector__XXX
 SG_ MET68C_4_6_UNIT_DEGREE : 38|2@1+ (1,0) [0|3] ""  CCU
 SG_ MET68C_3_0_MET_SW_STATE : 24|3@1+ (1,0) [0|3] "" Vector__XXX
 SG_ MET68C_3_3_PERMIT_MFD_CSTM : 27|1@1+ (1,0) [0|1] "" Vector__XXX
 SG_ MET68C_3_5_FLG_RR_AC_PANEL : 29|1@1+ (1,0) [0|1] "" Vector__XXX
 SG_ MET68C_3_6_FLG_SEAT_VENT : 30|1@1+ (1,0) [0|1] "" Vector__XXX
 SG_ MET68C_3_7_FLG_SEAT_HEAT : 31|1@1+ (1,0) [0|1] "" Vector__XXX
 SG_ MET68C_2_0_CRUISING_RADIUS : 16|8@1+ (10,0) [10|2540] "km(mile)"  CCU
 SG_ MET68C_1_0_MSG_COUNTER : 8|4@1+ (1,0) [0|15] "" Vector__XXX
 SG_ MET68C_1_4_CSTM_HU : 12|1@1+ (1,0) [0|1] "" Vector__XXX
 SG_ MET68C_1_5_CSTM_BRAND_NAME : 13|1@1+ (1,0) [0|1] "" Vector__XXX
 SG_ MET68C_0_0_CHECK_SUM : 0|8@1+ (1,0) [0|255] "" Vector__XXX

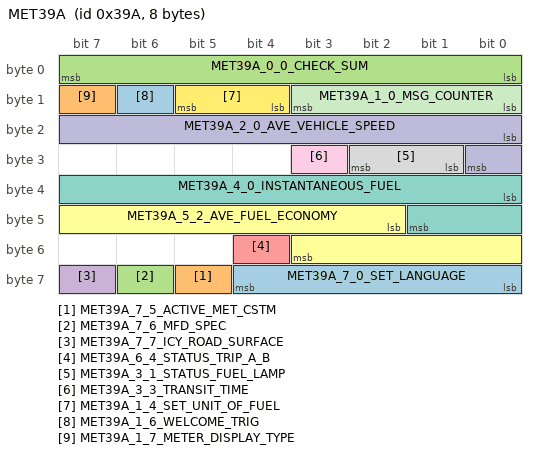
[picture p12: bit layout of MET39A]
BO_ 922 MET39A: 8 C_ECU_GW
 SG_ MET39A_7_0_SET_LANGUAGE : 56|5@1+ (1,0) [0|21] "" Vector__XXX
 SG_ MET39A_7_5_ACTIVE_MET_CSTM : 61|1@1+ (1,0) [0|1] "" Vector__XXX
 SG_ MET39A_7_6_MFD_SPEC : 62|1@1+ (1,0) [0|1] "" Vector__XXX
 SG_ MET39A_7_7_ICY_ROAD_SURFACE : 63|1@1+ (1,0) [0|2] "" Vector__XXX
 SG_ MET39A_6_4_STATUS_TRIP_A_B : 52|1@1+ (1,0) [0|1] ""  CCU
 SG_ MET39A_5_2_AVE_FUEL_ECONOMY : 42|10@1+ (0.1,0) [0|99.9] "km/l,l/100km,MPG"  CCU
 SG_ MET39A_4_0_INSTANTANEOUS_FUEL : 32|10@1+ (0.1,0) [0|99.9] "km/l,l/100km,MPG" Vector__XXX
 SG_ MET39A_3_1_STATUS_FUEL_LAMP : 25|2@1+ (1,0) [0|3] ""  CCU
 SG_ MET39A_3_3_TRANSIT_TIME : 27|1@1+ (1,0) [0|1] "" Vector__XXX
 SG_ MET39A_2_0_AVE_VEHICLE_SPEED : 16|9@1+ (1,0) [0|300] "km/h(MPH)"  CCU
 SG_ MET39A_1_0_MSG_COUNTER : 8|4@1+ (1,0) [0|15] ""  CCU
 SG_ MET39A_1_4_SET_UNIT_OF_FUEL : 12|2@1+ (1,0) [0|3] ""  CCU
 SG_ MET39A_1_6_WELCOME_TRIG : 14|1@1+ (1,0) [0|2] ""  CCU
 SG_ MET39A_1_7_METER_DISPLAY_TYPE : 15|1@1+ (1,0) [0|2] "" Vector__XXX
 SG_ MET39A_0_0_CHECK_SUM : 0|8@1+ (1,0) [0|255] ""  CCU

BO_ 915 MET393: 8 C_ECU_GW
 SG_ MET393_7_0_REQ_CHG_CSTM_EYE : 56|1@1+ (1,0) [0|1] "" Vector__XXX
 SG_ MET393_7_1_REQ_RESET_CSTM_EYE : 57|1@1+ (1,0) [0|1] "" Vector__XXX
 SG_ MET393_7_2_CSTM_ALK : 58|1@1+ (1,0) [0|1] "" Vector__XXX
 SG_ MET393_7_3_CSTM_HBA : 59|1@1+ (1,0) [0|1] "" Vector__XXX
 SG_ MET393_7_4_CSTM_MIS_AT_BACK : 60|2@1+ (1,0) [0|3] "" Vector__XXX
 SG_ MET393_7_6_CSTM_ACC_CONT : 62|2@1+ (1,0) [0|3] "" Vector__XXX
 SG_ MET393_6_0_R_DIFF_TEMP : 48|8@1+ (1,-50) [-50|200] "℃" Vector__XXX
 SG_ MET393_5_2_WARN_R_DIFF_TEMP : 42|2@1+ (1,0) [0|3] "" Vector__XXX
 SG_ MET393_5_4_ADAPTIVECC_NOALIVE : 44|1@1+ (1,0) [0|1] "" Vector__XXX
 SG_ MET393_5_5_DUAL_RANGE_LO : 45|1@1+ (1,0) [0|1] "" Vector__XXX
 SG_ MET393_5_6_CSTM_SPD_LIMITER : 46|1@1+ (1,0) [0|1] "" Vector__XXX
 SG_ MET393_5_7_CSTM_LANE_CONT : 47|1@1+ (1,0) [0|1] "" Vector__XXX
 SG_ MET393_4_0_FUEL_LEVEL_RESIST : 32|10@1+ (0.5,0) [0|480] "ohm"  CCU
 SG_ MET393_3_5_SI_DRIVE_SW : 29|3@1+ (1,0) [0|7] ""  CCU
 SG_ MET393_2_0_OUTTEMP_FOR_DIAG : 16|13@1+ (0.1,-400) [-400|419.1] "℃" Vector__XXX
 SG_ MET393_1_0_MSG_COUNTER : 8|4@1+ (1,0) [0|15] ""  CCU
 SG_ MET393_1_4_CSTM_IND_BLUE : 12|1@1+ (1,0) [0|1] "" Vector__XXX
 SG_ MET393_1_5_CSTM_AES_CONT : 13|1@1+ (1,0) [0|1] "" Vector__XXX
 SG_ MET393_1_6_FLG_PEDESTRIAN_AIRBAG : 14|1@1+ (1,0) [0|1] "" Vector__XXX
 SG_ MET393_0_0_CHECK_SUM : 0|8@1+ (1,0) [0|255] ""  CCU

BO_ 912 MET390: 8 C_ECU_GW
 SG_ MET390_7_0_VDC_ON_OFF : 56|2@1+ (1,0) [0|3] "" Vector__XXX
 SG_ MET390_7_2_RR_DOOR_RECORD_L : 58|1@1+ (1,0) [0|1] "" Vector__XXX
 SG_ MET390_7_3_RR_DOOR_RECORD_R : 59|1@1+ (1,0) [0|1] "" Vector__XXX
 SG_ MET390_7_4_REQ_CHG_CSTM_PSM : 60|1@1+ (1,0) [0|1] "" Vector__XXX
 SG_ MET390_7_5_REQ_RESET_CSTM_PSM : 61|1@1+ (1,0) [0|1] "" Vector__XXX
 SG_ MET390_7_6_CSTM_MIR_AFOLD_CONT : 62|1@1+ (1,0) [0|1] "" Vector__XXX
 SG_ MET390_7_7_CSTM_MIR_RTILT_CONT : 63|1@1+ (1,0) [0|1] "" Vector__XXX
 SG_ MET390_6_0_SEATBELT_DRVR : 48|1@1+ (1,0) [0|1] ""  CCU
 SG_ MET390_6_1_SEATBELT_PASS : 49|1@1+ (1,0) [0|1] ""  CCU
 SG_ MET390_6_2_TURN_SIG_LEFT : 50|1@1+ (1,0) [0|1] "" Vector__XXX
 SG_ MET390_6_3_TURN_SIG_RIGHT : 51|1@1+ (1,0) [0|1] "" Vector__XXX
 SG_ MET390_6_4_BRIGHT_SW : 52|1@1+ (1,0) [0|1] ""  CCU
 SG_ MET390_6_5_FAIL_UART_WA_BOX : 53|1@1+ (1,0) [0|1] "" Vector__XXX
 SG_ MET390_6_6_ISS_OFF_SW : 54|1@1+ (1,0) [0|1] "" Vector__XXX
 SG_ MET390_6_7_FLG_DMS : 55|1@1+ (1,0) [0|1] "" Vector__XXX
 SG_ MET390_5_0_ILL_BRIGHTNESS : 40|8@1+ (0.4,0) [0|100] "%"  CCU
 SG_ MET390_4_0_OUTTEMP_FOR_IND : 32|8@1+ (0.5,-40) [-40|80] "℃"  DCM,CCU
 SG_ MET390_3_0_UNIT_SPEED_TRIP : 24|1@1+ (1,0) [0|1] ""  DCM,CCU
 SG_ MET390_3_1_FLG_EYESIGHT : 25|1@1+ (1,0) [0|1] "" Vector__XXX
 SG_ MET390_3_2_FLG_ISS : 26|1@1+ (1,0) [0|1] "" Vector__XXX
 SG_ MET390_3_3_FLG_HEV : 27|1@1+ (1,0) [0|1] "" Vector__XXX
 SG_ MET390_3_4_FLG_IMB : 28|1@1+ (1,0) [0|1] "" Vector__XXX
 SG_ MET390_3_5_TIRE_SIZE : 29|1@1+ (1,0) [0|1] "" Vector__XXX
 SG_ MET390_3_6_FLG_XMODE : 30|2@1+ (1,0) [0|3] ""  CCU
 SG_ MET390_2_0_VEHICLE_SERIES : 16|3@1+ (1,0) [0|7] ""  DCM
 SG_ MET390_2_3_DESTINATION : 19|4@1+ (1,0) [0|12] ""  CCU
 SG_ MET390_2_7_PASS_DOOR_RECORD : 23|1@1+ (1,0) [0|1] "" Vector__XXX
 SG_ MET390_1_0_MSG_COUNTER : 8|4@1+ (1,0) [0|15] ""  DCM,CCU
 SG_ MET390_1_4_WAKE_UP_FRAME : 12|1@1+ (1,0) [0|1] "" Vector__XXX
 SG_ MET390_1_5_REQ_COMM_CONT : 13|1@1+ (1,0) [0|1] "" Vector__XXX
 SG_ MET390_1_6_DMS_ID_SET : 14|1@1+ (1,0) [0|1] ""  CCU
 SG_ MET390_1_7_FAIL_EEPROM : 15|1@1+ (1,0) [0|1] "" Vector__XXX
 SG_ MET390_0_0_CHECK_SUM : 0|8@1+ (1,0) [0|255] ""  DCM,CCU

CM_ SG_ 1546 BAT60A_29_4_LVB_VOL "高電圧バッテリ_補機電圧
";
CM_ SG_ 1546 BAT60A_29_3_EXWATTMPERR "高電圧_出口水温合理性異常
";
CM_ SG_ 1546 BAT60A_29_2_SNSWATTMPERR "高電圧_水温センサ合理性異常
";
CM_ SG_ 1546 BAT60A_29_1_SNSSMKEMSERR "高電圧_排煙異常
";
CM_ SG_ 1546 BAT60A_29_0_SNSEXTMP2ERR "高電圧_排気温度センサ合理性異常2
";
CM_ SG_ 1546 BAT60A_28_7_SNSEXTMP1ERR "高電圧_排気温度センサ合理性異常1
";
CM_ SG_ 1546 BAT60A_28_6_DEVTSTCK3ERR "高電圧_セル温度偏差異常(スタック3)
";
CM_ SG_ 1546 BAT60A_28_5_DEVTSTCK2ERR "高電圧_セル温度偏差異常(スタック2)
";
CM_ SG_ 1546 BAT60A_28_4_DEVTSTCK1ERR "高電圧_セル温度偏差異常(スタック1)
";
CM_ SG_ 1546 BAT60A_28_3_OVERTLVL2ERR "高電圧_セル温度上限超過Lv2異常
";
CM_ SG_ 1546 BAT60A_28_2_OVERTLVL1ERR "高電圧_セル温度上限超過Lv1異常
";
CM_ SG_ 1546 BAT60A_28_1_RESDEVERR "高電圧_電池抵抗偏差異常
";
CM_ SG_ 1546 BAT60A_28_0_PWLINEOV6ERR "高電圧_MSOP評価値超過異常6
";
CM_ SG_ 1546 BAT60A_27_7_PWLINEOV5ERR "高電圧_MSOP評価値超過異常5
";
CM_ SG_ 1546 BAT60A_27_6_PWLINEOV4ERR "高電圧_MSOP評価値超過異常4
";
CM_ SG_ 1546 BAT60A_27_5_PWLINEOV3ERR "高電圧_MSOP評価値超過異常3
";
CM_ SG_ 1546 BAT60A_27_4_PWLINEOV2ERR "高電圧_MSOP評価値超過異常2
";
CM_ SG_ 1546 BAT60A_27_3_PWLINEOV1ERR "高電圧_MSOP評価値超過異常1
";
CM_ SG_ 1546 BAT60A_27_2_VWOUTOVERERR "高電圧_Vwout超過異常
";
CM_ SG_ 1546 BAT60A_27_1_VWINOVERERR "高電圧_VWin超過異常
";
CM_ SG_ 1546 BAT60A_27_0_ACTESTDEVERR "高電圧_電池容量低下異常
";
CM_ SG_ 1546 BAT60A_26_7_RWOUTUNDERR "高電圧_Wout超過異常
";
CM_ SG_ 1546 BAT60A_26_6_RWINOVRERR "高電圧_Win超過異常
";
CM_ SG_ 1546 BAT60A_26_5_HVOFFISOERR "高電圧_絶縁抵抗低下異常(HVOFF)
";
CM_ SG_ 1546 BAT60A_26_4_HVONISOERR "高電圧_絶縁抵抗低下異常(HVON)
";
CM_ SG_ 1546 BAT60A_26_3_HVSUMCOMPERR "高電圧_セル電圧総和/総電圧比較異常
";
CM_ SG_ 1546 BAT60A_26_2_CEUNDULV2ERR "高電圧_セル電圧下限Lv2異常
";
CM_ SG_ 1546 BAT60A_26_1_CEOVRULV2ERR "高電圧_セル電圧上限Lv2異常
";
CM_ SG_ 1546 BAT60A_26_0_ICHPEAKERR "高電圧_充電過電流異常
";
CM_ SG_ 1546 BAT60A_25_7_IDCHAPEAKERR "高電圧_放電過電流異常
";
CM_ SG_ 1546 BAT60A_25_6_HVOVRULV2ERR "高電圧_総電圧上限Lv2異常
";
CM_ SG_ 1546 BAT60A_25_5_HVUNDULV2ERR "高電圧_総電圧上限Lv2異常
";
CM_ SG_ 1546 BAT60A_25_4_CEUNDULV1ERR "高電圧_セル電圧下限Lv1異常
";
CM_ SG_ 1546 BAT60A_25_3_CEOVRULV1ERR "高電圧_セル電圧上限Lv1異常
";
CM_ SG_ 1546 BAT60A_25_2_HVOVRULV1ERR "高電圧_総電圧上限Lv1異常
";
CM_ SG_ 1546 BAT60A_25_1_CEUDIFDYNERR "高電圧_セル電圧偏差異常(OCC)
";
CM_ SG_ 1546 BAT60A_25_0_OVERSOCERR "高電圧_SOC上限異常
";
CM_ SG_ 1546 BAT60A_24_7_UNDERSOCERR "高電圧_SOC下限異常
";
CM_ SG_ 1546 BAT60A_24_6_HVUNDULV1ERR "高電圧_総電圧下限Lv1異常
";
CM_ SG_ 1546 BAT60A_24_5_ISOMEASERR "高電圧_絶縁抵抗測定異常
";
CM_ SG_ 1546 BAT60A_24_4_CHGAWINOVERR "高電圧_Win超過異常(外部充電中)
";
CM_ SG_ 1546 BAT60A_24_3_CEUHIDIFERR "高電圧_セル電圧偏差異常(OCV)
";
CM_ SG_ 1546 BAT60A_23_6_HVB_OUTLIMFCT "高電圧バッテリ_出力制限要因
";
CM_ SG_ 1546 BAT60A_23_1_HVB_INLIMFCT "高電圧バッテリ_入力制限要因
";
CM_ SG_ 1546 BAT60A_22_4_HVB_WOUT "高電圧バッテリ_Wout
";
CM_ SG_ 1546 BAT60A_21_2_HVB_WIN "高電圧バッテリ_Win
";
CM_ SG_ 1546 BAT60A_20_5_HVB_OPRMODE "高電圧バッテリ_動作モード
";
CM_ SG_ 1546 BAT60A_19_1_HVB_CELLSOHRMIN "高電圧バッテリ_最小セル抵抗劣化率
";
CM_ SG_ 1546 BAT60A_18_2_HVB_CELLSOHRMAX "高電圧バッテリ_最大セル抵抗劣化率
";
CM_ SG_ 1546 BAT60A_17_3_HVB_CELLSOHCMIN "高電圧バッテリ_最小セル容量劣化率
";
CM_ SG_ 1546 BAT60A_16_4_HVB_CELLSOHCMAX "高電圧バッテリ_最大セル容量劣化率
";
CM_ SG_ 1546 BAT60A_15_5_HVB_SOC "高電圧バッテリ_SOC
";
CM_ SG_ 1546 BAT60A_14_5_HVB_WATTEMP "高電圧バッテリ_電池水温
";
CM_ SG_ 1546 BAT60A_13_5_JB_TEMPSNS "JB_温度センサ
";
CM_ SG_ 1546 BAT60A_12_5_HVB_CELLTEMPMINNO "高電圧バッテリ_最小温度セル番号
";
CM_ SG_ 1546 BAT60A_11_5_HVB_CELLTEMPMAXNO "高電圧バッテリ_最大温度セル番号
";
CM_ SG_ 1546 BAT60A_10_5_HVB_CELLTEMPMIN "高電圧バッテリ_最小セル温度
";
CM_ SG_ 1546 BAT60A_9_5_HVB_CELLTEMPMAX "高電圧バッテリ_最大セル温度
";
CM_ SG_ 1546 BAT60A_8_2_HVB_CUR "高電圧バッテリ_電流
";
CM_ SG_ 1546 BAT60A_7_2_HVB_CELLVOLMINNO "高電圧バッテリ_最小電圧セル番号
";
CM_ SG_ 1546 BAT60A_6_2_HVB_CELLVOLMAXNO "高電圧バッテリ_最大電圧セル番号
";
CM_ SG_ 1546 BAT60A_4_5_HVB_CELLVOLMIN "高電圧バッテリ_最小セル電圧
";
CM_ SG_ 1546 BAT60A_3_0_HVB_CELLVOLMAX "高電圧バッテリ_最大セル電圧
";
CM_ SG_ 1546 BAT60A_2_0_E2E_COUNTER "E2Eカウンタ
";
CM_ SG_ 1546 BAT60A_0_0_E2E_CRC "CRC
";
CM_ SG_ 1680 BAT690_28_2_CHG_REMTI_GRF26 "残充電時間_グラフ26
";
CM_ SG_ 1680 BAT690_27_2_CHG_REMTI_GRF25 "残充電時間_グラフ25
";
CM_ SG_ 1680 BAT690_26_2_CHG_REMTI_GRF24 "残充電時間_グラフ24
";
CM_ SG_ 1680 BAT690_25_2_CHG_REMTI_GRF23 "残充電時間_グラフ23
";
CM_ SG_ 1680 BAT690_24_2_CHG_REMTI_GRF22 "残充電時間_グラフ22
";
CM_ SG_ 1680 BAT690_23_2_CHG_REMTI_GRF21 "残充電時間_グラフ21
";
CM_ SG_ 1680 BAT690_22_2_CHG_REMTI_GRF20 "残充電時間_グラフ20
";
CM_ SG_ 1680 BAT690_21_2_CHG_REMTI_GRF19 "残充電時間_グラフ19
";
CM_ SG_ 1680 BAT690_20_2_CHG_REMTI_GRF18 "残充電時間_グラフ18
";
CM_ SG_ 1680 BAT690_19_2_CHG_REMTI_GRF17 "残充電時間_グラフ17
";
CM_ SG_ 1680 BAT690_18_2_CHG_REMTI_GRF16 "残充電時間_グラフ16
";
CM_ SG_ 1680 BAT690_17_2_CHG_REMTI_GRF15 "残充電時間_グラフ15
";
CM_ SG_ 1680 BAT690_16_2_CHG_REMTI_GRF14 "残充電時間_グラフ14
";
CM_ SG_ 1680 BAT690_15_2_CHG_REMTI_GRF13 "残充電時間_グラフ13
";
CM_ SG_ 1680 BAT690_14_2_CHG_REMTI_GRF12 "残充電時間_グラフ12
";
CM_ SG_ 1680 BAT690_13_2_CHG_REMTI_GRF11 "残充電時間_グラフ11
";
CM_ SG_ 1680 BAT690_12_2_CHG_REMTI_GRF10 "残充電時間_グラフ10
";
CM_ SG_ 1680 BAT690_11_2_CHG_REMTI_GRF9 "残充電時間_グラフ9
";
CM_ SG_ 1680 BAT690_10_2_CHG_REMTI_GRF8 "残充電時間_グラフ8
";
CM_ SG_ 1680 BAT690_9_2_CHG_REMTI_GRF7 "残充電時間_グラフ7
";
CM_ SG_ 1680 BAT690_8_2_CHG_REMTI_GRF6 "残充電時間_グラフ6
";
CM_ SG_ 1680 BAT690_7_2_CHG_REMTI_GRF5 "残充電時間_グラフ5
";
CM_ SG_ 1680 BAT690_6_2_CHG_REMTI_GRF4 "残充電時間_グラフ4
";
CM_ SG_ 1680 BAT690_5_2_CHG_REMTI_GRF3 "残充電時間_グラフ3
";
CM_ SG_ 1680 BAT690_4_2_CHG_REMTI_GRF2 "残充電時間_グラフ2
";
CM_ SG_ 1680 BAT690_3_2_CHG_REMTI_GRF1 "残充電時間_グラフ1
";
CM_ SG_ 1680 BAT690_3_0_CHG_REMTI_GRF "残充電時間_グラフ_種類
";
CM_ SG_ 1680 BAT690_2_0_E2E_COUNTER "E2Eカウンタ
";
CM_ SG_ 1680 BAT690_0_0_E2E_CRC "CRC
";
CM_ SG_ 862 BAT35E_4_4_HVB_CONDCHK_FLG "高電圧バッテリ_点検お知らせ
";
CM_ SG_ 862 BAT35E_3_2_HVB_CTRLSOC_PERC "高電圧バッテリ_制御SOC_perc
";
CM_ SG_ 862 BAT35E_3_0_HVB_WRN_TEMP "高電圧バッテリ_温度通知要求
";
CM_ SG_ 862 BAT35E_2_0_E2E_COUNTER "E2Eカウンタ
";
CM_ SG_ 862 BAT35E_0_0_E2E_CRC "CRC
";
CM_ SG_ 861 BAT35D_28_5_HVB_ACTCHGWIN "高電圧バッテリ_実充電電力(瞬時値)
";
CM_ SG_ 861 BAT35D_27_2_HVB_TEMPAVE "高電圧バッテリ_温度_平均_degC
";
CM_ SG_ 861 BAT35D_25_1_HVB_AVBENE_UPL "高電圧バッテリ_使用可能エネルギー_上限_wh
";
CM_ SG_ 861 BAT35D_23_0_HVB_AVBENE_CUR "高電圧バッテリ_使用可能エネルギー_現在_wh
";
CM_ SG_ 861 BAT35D_20_7_HVB_AVBENE_LOL "高電圧バッテリ_使用可能エネルギー_下限_wh
";
CM_ SG_ 861 BAT35D_18_2_HVB_DISPSOHODO "高電圧バッテリ_表示SOH更新後走行距離
";
CM_ SG_ 861 BAT35D_17_0_HVB_DISPSOH_PERC "高電圧バッテリ_表示SOH_バッテリ劣化率_perc
";
CM_ SG_ 861 BAT35D_15_7_HVB_DISPSOH_R_AH "高電圧バッテリ_表示SOH_リザーブ容量_ah
";
CM_ SG_ 861 BAT35D_14_6_HVB_DISPSOH_AH "高電圧バッテリ_表示SOH_バッテリ容量_ah
";
CM_ SG_ 861 BAT35D_13_0_CHG_REMTI_UPS_ACN "残充電時間_充電量上限設定_空調ON_min
";
CM_ SG_ 861 BAT35D_11_2_CHG_REMTI_UPS "残充電時間_充電量上限設定_空調OFF_min
";
CM_ SG_ 861 BAT35D_9_4_CHG_REMTI_BLK_ACN "残充電時間_バルクSOC_空調ON_min
";
CM_ SG_ 861 BAT35D_7_6_CHG_REMTI_BLK "残充電時間_バルクSOC_空調OFF_min
";
CM_ SG_ 861 BAT35D_6_0_CHG_REMTI_ACN "残充電時間_空調ON_min
";
CM_ SG_ 861 BAT35D_4_2_CHG_REMTI "残充電時間_空調OFF_min
";
CM_ SG_ 861 BAT35D_3_0_HVB_DISPSOC_PERC "高電圧バッテリ_表示SOC_perc
";
CM_ SG_ 861 BAT35D_2_0_E2E_COUNTER "E2Eカウンタ
";
CM_ SG_ 861 BAT35D_0_0_E2E_CRC "CRC
";
CM_ SG_ 1685 BEV695_7_0_BRMK7 "トラシュ用データ7
";
CM_ SG_ 1685 BEV695_6_0_BRMK6 "トラシュ用データ6
";
CM_ SG_ 1685 BEV695_5_0_BRMK5 "トラシュ用データ5
";
CM_ SG_ 1685 BEV695_4_0_BRMK4 "トラシュ用データ4
";
CM_ SG_ 1685 BEV695_3_0_BRMK3 "トラシュ用データ3
";
CM_ SG_ 1685 BEV695_2_0_BRMK2 "トラシュ用データ2
";
CM_ SG_ 1685 BEV695_1_0_BRMK1 "トラシュ用データ1
";
CM_ SG_ 1685 BEV695_0_0_BRMK0 "トラシュ用データ0
";
CM_ SG_ 1539 BEV603_15_0_BATTEMPSTS_DISP "バッテリ温度状態(表示用)
";
CM_ SG_ 1539 BEV603_14_0_RR_MTRTEMPSTS_DISP "Rrモータ温度状態(表示用)
";
CM_ SG_ 1539 BEV603_14_3_FR_MTRTEMPSTS_DISP "Frモータ温度状態(表示用)
";
CM_ SG_ 1539 BEV603_13_0_BATTEMP_DISP "バッテリ温度(表示用)
";
CM_ SG_ 1539 BEV603_12_0_RR_MTRTEMP_DISP "Rrモータ温度(表示用)
";
CM_ SG_ 1539 BEV603_11_0_FR_MTRTEMP_DISP "Frモータ温度(表示用)
";
CM_ SG_ 1539 BEV603_10_2_TRQFLCREQ "トルク変動モード実施中表示要求
";
CM_ SG_ 1539 BEV603_10_4_TRQFLCNG "トルク変動モード禁止表示要求
";
CM_ SG_ 1539 BEV603_10_5_TRQFLCSTATE "トルク変動モード現在値
";
CM_ SG_ 1539 BEV603_10_6_TRQFLCDISP "トルク変動モード表示有無
";
CM_ SG_ 1539 BEV603_10_7_TRQVIBREQ "トルク変動モード実施中表示要求
";
CM_ SG_ 1539 BEV603_9_4_PADL_INHBUZ "パドル禁止時ブザー吹鳴フラグ
";
CM_ SG_ 1539 BEV603_9_5_PADL_LVL "パドル段数
";
CM_ SG_ 1539 BEV603_8_1_XMODE_INH "X-MODE選択禁止フラグ
";
CM_ SG_ 1539 BEV603_8_2_SIDRIVE_INH "SIドライブ選択禁止フラグ
";
CM_ SG_ 1539 BEV603_8_3_SIDRIVE_INHBUZ "SIドライブ禁止ブザー吹鳴フラグ
";
CM_ SG_ 1539 BEV603_8_4_ARBIT_SIDR "SIドライブ調停優先状態
";
CM_ SG_ 1539 BEV603_8_5_SIDRIVE_DISP "SIドライブモード表示情報
";
CM_ SG_ 1539 BEV603_7_4_ADPDEC_INHBUZ "アダプティブ減速禁止ブザー吹鳴フラグ
";
CM_ SG_ 1539 BEV603_7_5_ADPDEC_INH_ALL "アダプティブ減速禁止フラグ
";
CM_ SG_ 1539 BEV603_7_6_ADPDEC_DISP "アダプティブ減速表示情報
";
CM_ SG_ 1539 BEV603_7_7_ADPDEC_EQ "アダプティブ減速装備情報
";
CM_ SG_ 1539 BEV603_6_0_AWD_MODE "AWDモード
";
CM_ SG_ 1539 BEV603_6_3_AWD_STS_DISP "AWDモード割り込み表示要求
";
CM_ SG_ 1539 BEV603_6_4_DECSEL_INHMSG "減速度セレクト割り込み禁止表示要求
";
CM_ SG_ 1539 BEV603_6_7_AWD_MODE_EQUIP "AWDモード機能有無
";
CM_ SG_ 1539 BEV603_5_0_PDLBZR "パドル操作リジェクトブザー
";
CM_ SG_ 1539 BEV603_5_1_SFTDN_PERM "シフトダウン許可フラグ
";
CM_ SG_ 1539 BEV603_5_2_SFTUP_PERM "シフトアップ許可フラグ
";
CM_ SG_ 1539 BEV603_5_3_GEARSFT_MODE "変速モード
";
CM_ SG_ 1539 BEV603_5_4_DECSEL_INH_INDI "減速度セレクト禁止フラグ_Individual
";
CM_ SG_ 1539 BEV603_5_5_DECSEL_INH_B "減速度セレクト禁止フラグ_B
";
CM_ SG_ 1539 BEV603_5_6_DECSEL_INH_D "減速度セレクト禁止フラグ_D
";
CM_ SG_ 1539 BEV603_5_7_DECSEL_INH_ALL "減速度セレクト禁止フラグ_ALL
";
CM_ SG_ 1539 BEV603_4_1_DECSEL_DISP_INDI "減速度セレクト表示情報_Individual
";
CM_ SG_ 1539 BEV603_4_2_DECSEL_DISP_B "減速度セレクト表示情報_B
";
CM_ SG_ 1539 BEV603_4_4_DECLV_DECSEL "減速度レベル(減速度セレクト)
";
CM_ SG_ 1539 BEV603_4_6_DECSEL_DISP_ALL "減速度セレクト表示情報_ALL
";
CM_ SG_ 1539 BEV603_3_0_GEARLV_MANU "ギア段(多段手動変速)
";
CM_ SG_ 1539 BEV603_3_1_DECSEL_EQ_INDI "減速度セレクト段数装備情報_Individual
";
CM_ SG_ 1539 BEV603_3_2_DECSEL_EQ_B "減速度セレクト段数装備情報_B
";
CM_ SG_ 1539 BEV603_3_4_GEARLV_AUTO "ギア段(多段自動変速)
";
CM_ SG_ 1539 BEV603_3_6_DECSEL_EQ_ALL "減速度セレクト段数装備情報_ALL
";
CM_ SG_ 1539 BEV603_2_0_E2E_COUNTER "E2Eカウンタ
";
CM_ SG_ 1539 BEV603_0_0_E2E_CRC "CRC
";
CM_ SG_ 1538 BEV602_18_0_V2L_OUTLET_VOLTAGE "車内AC給電_コンセント電圧値
";
CM_ SG_ 1538 BEV602_16_0_LV_SYS_STATUS "12V電源システム状態
";
CM_ SG_ 1538 BEV602_15_0_DCM_REMOTE_INFO "DCMリモート指令情報
";
CM_ SG_ 1538 BEV602_14_7_RR_DISPMSG_RES_UNADJ "RrMG_レゾルバ未調整メッセージ表示要求
";
CM_ SG_ 1538 BEV602_14_6_FR_DISPMSG_RES_UNADJ "FrMG_レゾルバ未調整メッセージ表示要求
";
CM_ SG_ 1538 BEV602_14_4_DISPMSG_SC_SGLPH "Fr/RrMG_一相ON固着メッセージ表示要求
";
CM_ SG_ 1538 BEV602_14_2_CERT2_MODE "認証モード(2WD)
";
CM_ SG_ 1538 BEV602_14_0_SW_PWR_SPL "車内AC給電スイッチON/OFF状態
";
CM_ SG_ 1538 BEV602_13_0_TCSLMP_REQ "TCS作動灯要求
";
CM_ SG_ 1538 BEV602_13_1_AWDLMP_REQ "AWD警告点灯要求
";
CM_ SG_ 1538 BEV602_13_3_AWDWRNMSG_REQ "AWD警告灯メッセージ要求
";
CM_ SG_ 1538 BEV602_12_0_BOSLMP_REQ "BOS作動灯表示要求
";
CM_ SG_ 1538 BEV602_11_3_LVB_ABN "12Vバッテリ異常警告
";
CM_ SG_ 1538 BEV602_11_6_CERT4_MODE "認証モード(AWD)
";
CM_ SG_ 1538 BEV602_11_7_CERT2_MODE "認証モード(2WD)
";
CM_ SG_ 1538 BEV602_10_0_FACT_CERT_MODE "工場/認証モード
";
CM_ SG_ 1538 BEV602_10_1_FACT_MODE "工場モード
";
CM_ SG_ 1538 BEV602_10_2_EVBATLO_CAU "電欠警告灯点灯要求
";
CM_ SG_ 1538 BEV602_10_5_PWRLMT_ID "出力制限_原因種別
";
CM_ SG_ 1538 BEV602_9_1_DCRCHK_DSP_REQ "DCR溶着再診断表示要求
";
CM_ SG_ 1538 BEV602_9_4_LVB_FNCLMT_MSG "機能制限アナウンス（制限前の消費電力低減提言含む）
";
CM_ SG_ 1538 BEV602_9_7_CHG_MSG "充電中補助表示_表示要求
";
CM_ SG_ 1538 BEV602_8_0_LVB_ABN_DCDC "12Vバッテリ異常警告_種別（DCDC異常）
";
CM_ SG_ 1538 BEV602_8_4_LVB_ABN_LIB "12Vバッテリ異常通知（Lib）_表示要求
";
CM_ SG_ 1538 BEV602_8_7_CHG_CAU "チャージ警告灯
";
CM_ SG_ 1538 BEV602_7_0_V2L_STOP_MSG "車内AC給電停止要因通知
";
CM_ SG_ 1538 BEV602_6_0_V2L_SOC_LOWLMT "車内AC給電停止SOC値現在設定値
";
CM_ SG_ 1538 BEV602_5_0_V2L_OUTSTS_2 "車内AC給電状態_コンセント2
";
CM_ SG_ 1538 BEV602_5_1_V2L_OUTSTS_1 "車内AC給電状態_コンセント1
";
CM_ SG_ 1538 BEV602_5_2_ACCHCAU "アクセルホールド警報要求
";
CM_ SG_ 1538 BEV602_5_3_EVIND "EVｼｽﾃﾑ機能不全文言信号
";
CM_ SG_ 1538 BEV602_4_0_BEV_OBD_CAU "BEV_OBD警告灯点灯要求
";
CM_ SG_ 1538 BEV602_4_3_EV_CAU "EVコーション点灯要求
";
CM_ SG_ 1538 BEV602_4_5_PIROFF_MSG "引き摺り防止強制停止表示要求
";
CM_ SG_ 1538 BEV602_3_0_DRVRDY "運転可能表示状態
";
CM_ SG_ 1538 BEV602_3_2_RANGE_POS "現在レンジ位置情報
";
CM_ SG_ 1538 BEV602_2_0_E2E_COUNTER "E2Eカウンタ
";
CM_ SG_ 1538 BEV602_0_0_E2E_CRC "CRC
";
CM_ SG_ 541 BEV21D_4_0_V2L_PWR_2 "車内AC給電消費電力_コンセント2
";
CM_ SG_ 541 BEV21D_3_0_V2L_PWR_1 "車内AC給電消費電力_コンセント1
";
CM_ SG_ 541 BEV21D_2_0_E2E_COUNTER "E2Eカウンタ
";
CM_ SG_ 541 BEV21D_0_0_E2E_CRC "CRC
";
CM_ SG_ 269 BEV10D_22_0_SNDGAIN_CHG "音調整ゲインマップ切替信号
";
CM_ SG_ 269 BEV10D_21_0_EVENT_VOL_B "イベント音量B
";
CM_ SG_ 269 BEV10D_20_0_EVENT_VOL_A "イベント音量A
";
CM_ SG_ 269 BEV10D_18_0_RR_MTRTRQ_SND "Rrモータトルク(サウンド用)
";
CM_ SG_ 269 BEV10D_16_0_FR_MTRTRQ_SND "Frモータトルク(サウンド用)
";
CM_ SG_ 269 BEV10D_15_6_ENGON_SND "エンジン始動音演出トリガー
";
CM_ SG_ 269 BEV10D_15_7_BKF_SND "バックファイア音演出トリガー
";
CM_ SG_ 269 BEV10D_14_0_V_ENGRPM_SND "仮想エンジン回転数(サウンド用)
";
CM_ SG_ 269 BEV10D_12_0_V_RZRPM_DISP "レッドゾーン開始回転数
";
CM_ SG_ 269 BEV10D_11_6_SNDOUT_SET "音出力設定
";
CM_ SG_ 269 BEV10D_10_0_V_ENGRPM_DISP "仮想エンジン回転数(表示用)
";
CM_ SG_ 269 BEV10D_9_1_PMINPWRLMTNTC "回生制限(予告)_表示値
";
CM_ SG_ 269 BEV10D_8_0_PMOUTPWRLMTNTC "出力制限(予告)_表示値
";
CM_ SG_ 269 BEV10D_7_2_DCLLO_DISP "減速度低下表示
";
CM_ SG_ 269 BEV10D_7_4_PMINPWRLMTSTS "回生制限状態通知
";
CM_ SG_ 269 BEV10D_7_5_PMOUTPWRLMTSTS "出力制限状態通知
";
CM_ SG_ 269 BEV10D_6_0_PMPWR "車両パワー表示状態量
";
CM_ SG_ 269 BEV10D_5_1_PMINPWRLMT "回生制限_表示値
";
CM_ SG_ 269 BEV10D_4_0_PMOUTPWRLMT "出力制限_表示値
";
CM_ SG_ 269 BEV10D_3_0_LVB_SOC_LIB "12Vバッテリ容量（LiB）
";
CM_ SG_ 269 BEV10D_2_0_E2E_COUNTER "E2Eカウンタ
";
CM_ SG_ 269 BEV10D_0_0_E2E_CRC "CRC
";
CM_ SG_ 495 BEV1EF_6_0_RRMOTROT_BK "リアモータ回転数バックアップ状態
";
CM_ SG_ 495 BEV1EF_6_2_FRMOTROT_BK "フロントモータ回転数バックアップ状態
";
CM_ SG_ 495 BEV1EF_4_0_RRMOTROT "リアモータ回転数
";
CM_ SG_ 495 BEV1EF_2_0_FRMOTROT "フロントモータ回転数
";
CM_ SG_ 495 BEV1EF_1_0_MSG_COUNTER "ﾒｯｾｰｼﾞｶｳﾝﾀ
";
CM_ SG_ 495 BEV1EF_0_0_CHECK_SUM "ﾁｪｯｸｻﾑ
";
CM_ SG_ 494 BEV1EE_3_0_VIN_DATA "VIN Data
";
CM_ SG_ 494 BEV1EE_2_0_VIN_BYTE_NO "VIN ByteNo
";
CM_ SG_ 494 BEV1EE_1_0_MSG_COUNTER "ﾒｯｾｰｼﾞｶｳﾝﾀ
";
CM_ SG_ 494 BEV1EE_0_0_CHECK_SUM "ﾁｪｯｸｻﾑ
";
CM_ SG_ 267 BEV10B_6_7_SPEC8 "特殊分母8
";
CM_ SG_ 267 BEV10B_6_6_SPEC7 "特殊分母7
";
CM_ SG_ 267 BEV10B_6_5_SPEC6 "特殊分母6
";
CM_ SG_ 267 BEV10B_6_4_SPEC5 "特殊分母5
";
CM_ SG_ 267 BEV10B_6_3_SPEC4 "特殊分母4
";
CM_ SG_ 267 BEV10B_6_2_SPEC3 "特殊分母3
";
CM_ SG_ 267 BEV10B_6_1_SPEC2 "特殊分母2
";
CM_ SG_ 267 BEV10B_6_0_SPEC1 "特殊分母1
";
CM_ SG_ 267 BEV10B_5_2_DENO "一般分母
";
CM_ SG_ 267 BEV10B_5_1_PROHIBIT_INC "分子分母インクリメント禁止フラグ
";
CM_ SG_ 267 BEV10B_5_0_PERMIT_INC "一般分母インクリメント許可フラグ
";
CM_ SG_ 267 BEV10B_4_0_DCCNT "ドライビングサイクルカウンタ
";
CM_ SG_ 267 BEV10B_3_2_OBDRDY "OBD Ready状態
";
CM_ SG_ 267 BEV10B_3_0_DRVRDY "運転可能表示状態
";
CM_ SG_ 267 BEV10B_1_0_MSG_COUNTER "ﾒｯｾｰｼﾞｶｳﾝﾀ
";
CM_ SG_ 267 BEV10B_0_0_CHECK_SUM "ﾁｪｯｸｻﾑ
";
CM_ SG_ 117 BEV075_1_0_MSG_COUNTER "ﾒｯｾｰｼﾞｶｳﾝﾀ
";
CM_ SG_ 117 BEV075_0_0_CHECK_SUM "ﾁｪｯｸｻﾑ
";
CM_ SG_ 116 BEV074_7_0_LVPWRDWN "12V電力抑制信号
";
CM_ SG_ 116 BEV074_7_6_CHRCONSTA "充電コネクタ接続状態
";
CM_ SG_ 116 BEV074_7_7_VEHICLE_IGN "車両イグニッション情報
";
CM_ SG_ 116 BEV074_6_0_EV_CAU "EVコーション点灯要求
";
CM_ SG_ 116 BEV074_6_2_BEV_OBD_CAU "BEV_OBD警告灯点灯要求
";
CM_ SG_ 116 BEV074_6_5_SIDRIVE_DISP "SIドライブモード表示情報
";
CM_ SG_ 116 BEV074_5_0_ACCHG_STATE "AC充電状態
";
CM_ SG_ 116 BEV074_5_1_DCCHG_STATE "DC充電状態
";
CM_ SG_ 116 BEV074_5_2_RANGE_DG "シフト故障状態
";
CM_ SG_ 116 BEV074_5_3_ACCP_DG "アクセル故障状態
";
CM_ SG_ 116 BEV074_5_4_REZ_SPD_BK "レゾルバ車速バックアップ状態
";
CM_ SG_ 116 BEV074_5_6_OBDRDY "OBD Ready状態
";
CM_ SG_ 116 BEV074_5_7_FHVB "高電圧バッテリ異常
";
CM_ SG_ 116 BEV074_3_0_RANGE_POS "現在レンジ位置情報
";
CM_ SG_ 116 BEV074_3_3_DRVRDY "運転可能表示状態
";
CM_ SG_ 116 BEV074_3_5_HVSYSTS "高電圧システムステータス
";
CM_ SG_ 116 BEV074_3_7_REZ_SPD_GL "レゾルバ車速_GL
";
CM_ SG_ 116 BEV074_2_0_ACCP_USR "アクセル開度(ユーザー)
";
CM_ SG_ 116 BEV074_1_0_MSG_COUNTER "ﾒｯｾｰｼﾞｶｳﾝﾀ
";
CM_ SG_ 116 BEV074_1_4_RANGE_DG2 "シフト故障状態2
";
CM_ SG_ 116 BEV074_1_5_REZ_SPD_BK "レゾルバ車速バックアップ状態
";
CM_ SG_ 116 BEV074_0_0_CHECK_SUM "ﾁｪｯｸｻﾑ
";
CM_ SG_ 2564481473 DCM18DAE1C1_DIAG_DATA_EXT7 "ﾃﾞｰﾀ
";
CM_ SG_ 2564481473 DCM18DAE1C1_DIAG_DATA_EXT6 "ﾃﾞｰﾀ
";
CM_ SG_ 2564481473 DCM18DAE1C1_DIAG_DATA_EXT5 "ﾃﾞｰﾀ
";
CM_ SG_ 2564481473 DCM18DAE1C1_DIAG_DATA_EXT4 "ﾃﾞｰﾀ
";
CM_ SG_ 2564481473 DCM18DAE1C1_DIAG_DATA_EXT3 "ﾃﾞｰﾀ
";
CM_ SG_ 2564481473 DCM18DAE1C1_DIAG_DATA_EXT2 "ﾃﾞｰﾀ
";
CM_ SG_ 2564481473 DCM18DAE1C1_DIAG_DATA_EXT1 "ﾃﾞｰﾀ
";
CM_ SG_ 2564481473 DCM18DAE1C1_DIAG_DATA "ﾃﾞｰﾀ
";
CM_ SG_ 2564473313 CECU18DAC1E1_DIAG_DATA_EXT7 "ﾃﾞｰﾀ
";
CM_ SG_ 2564473313 CECU18DAC1E1_DIAG_DATA_EXT6 "ﾃﾞｰﾀ
";
CM_ SG_ 2564473313 CECU18DAC1E1_DIAG_DATA_EXT5 "ﾃﾞｰﾀ
";
CM_ SG_ 2564473313 CECU18DAC1E1_DIAG_DATA_EXT4 "ﾃﾞｰﾀ
";
CM_ SG_ 2564473313 CECU18DAC1E1_DIAG_DATA_EXT3 "ﾃﾞｰﾀ
";
CM_ SG_ 2564473313 CECU18DAC1E1_DIAG_DATA_EXT2 "ﾃﾞｰﾀ
";
CM_ SG_ 2564473313 CECU18DAC1E1_DIAG_DATA_EXT1 "ﾃﾞｰﾀ
";
CM_ SG_ 2564473313 CECU18DAC1E1_DIAG_DATA "ﾃﾞｰﾀ
";
CM_ SG_ 2564481217 DCM18DAE0C1_DIAG_DATA "ﾃﾞｰﾀ
";
CM_ SG_ 2564473312 DNT18DAC1E0_DIAG_DATA "ﾃﾞｰﾀ
";
CM_ SG_ 2564468769 BIU18DAB021_DIAG_DATA "ﾃﾞｰﾀ
";
CM_ SG_ 2564432304 AVN18DA21B0_DIAG_DATA "ﾃﾞｰﾀ
";
CM_ SG_ 2564481200 AVN18DAE0B0_DIAG_DATA_EXT7 "ﾃﾞｰﾀ
";
CM_ SG_ 2564481200 AVN18DAE0B0_DIAG_DATA_EXT6 "ﾃﾞｰﾀ
";
CM_ SG_ 2564481200 AVN18DAE0B0_DIAG_DATA_EXT5 "ﾃﾞｰﾀ
";
CM_ SG_ 2564481200 AVN18DAE0B0_DIAG_DATA_EXT4 "ﾃﾞｰﾀ
";
CM_ SG_ 2564481200 AVN18DAE0B0_DIAG_DATA_EXT3 "ﾃﾞｰﾀ
";
CM_ SG_ 2564481200 AVN18DAE0B0_DIAG_DATA_EXT2 "ﾃﾞｰﾀ
";
CM_ SG_ 2564481200 AVN18DAE0B0_DIAG_DATA_EXT1 "ﾃﾞｰﾀ
";
CM_ SG_ 2564481200 AVN18DAE0B0_DIAG_DATA "ﾃﾞｰﾀ
";
CM_ SG_ 2564468960 DNT18DAB0E0_DIAG_DATA_EXT7 "ﾃﾞｰﾀ
";
CM_ SG_ 2564468960 DNT18DAB0E0_DIAG_DATA_EXT6 "ﾃﾞｰﾀ
";
CM_ SG_ 2564468960 DNT18DAB0E0_DIAG_DATA_EXT5 "ﾃﾞｰﾀ
";
CM_ SG_ 2564468960 DNT18DAB0E0_DIAG_DATA_EXT4 "ﾃﾞｰﾀ
";
CM_ SG_ 2564468960 DNT18DAB0E0_DIAG_DATA_EXT3 "ﾃﾞｰﾀ
";
CM_ SG_ 2564468960 DNT18DAB0E0_DIAG_DATA_EXT2 "ﾃﾞｰﾀ
";
CM_ SG_ 2564468960 DNT18DAB0E0_DIAG_DATA_EXT1 "ﾃﾞｰﾀ
";
CM_ SG_ 2564468960 DNT18DAB0E0_DIAG_DATA "ﾃﾞｰﾀ
";
CM_ SG_ 2564550625 CECU18DBEFE1_DIAG_DATA "ﾃﾞｰﾀ
";
CM_ SG_ 2564550624 DNT18DBEFE0_DIAG_DATA "ﾃﾞｰﾀ
";
CM_ SG_ 1832 DNT728_7_0_DIAG_DATA "ﾃﾞｰﾀ
";
CM_ SG_ 1832 DNT728_2_0_DIAG_N_PCI_OR_DATA "N_PCI　 or 　ﾃﾞｰﾀ
";
CM_ SG_ 1832 DNT728_1_0_DIAG_N_PCI_OR_DATA "N_PCI　 or 　ﾃﾞｰﾀ
";
CM_ SG_ 1832 DNT728_0_0_DIAG_N_PCI "N_PCI
";
CM_ SG_ 2564481456 AVN18DAE1B0_DIAG_DATA_EXT7 "ﾃﾞｰﾀ
";
CM_ SG_ 2564481456 AVN18DAE1B0_DIAG_DATA_EXT6 "ﾃﾞｰﾀ
";
CM_ SG_ 2564481456 AVN18DAE1B0_DIAG_DATA_EXT5 "ﾃﾞｰﾀ
";
CM_ SG_ 2564481456 AVN18DAE1B0_DIAG_DATA_EXT4 "ﾃﾞｰﾀ
";
CM_ SG_ 2564481456 AVN18DAE1B0_DIAG_DATA_EXT3 "ﾃﾞｰﾀ
";
CM_ SG_ 2564481456 AVN18DAE1B0_DIAG_DATA_EXT2 "ﾃﾞｰﾀ
";
CM_ SG_ 2564481456 AVN18DAE1B0_DIAG_DATA_EXT1 "ﾃﾞｰﾀ
";
CM_ SG_ 2564481456 AVN18DAE1B0_DIAG_DATA "ﾃﾞｰﾀ
";
CM_ SG_ 2564468961 CECU18DAB0E1_DIAG_DATA_EXT7 "ﾃﾞｰﾀ
";
CM_ SG_ 2564468961 CECU18DAB0E1_DIAG_DATA_EXT6 "ﾃﾞｰﾀ
";
CM_ SG_ 2564468961 CECU18DAB0E1_DIAG_DATA_EXT5 "ﾃﾞｰﾀ
";
CM_ SG_ 2564468961 CECU18DAB0E1_DIAG_DATA_EXT4 "ﾃﾞｰﾀ
";
CM_ SG_ 2564468961 CECU18DAB0E1_DIAG_DATA_EXT3 "ﾃﾞｰﾀ
";
CM_ SG_ 2564468961 CECU18DAB0E1_DIAG_DATA_EXT2 "ﾃﾞｰﾀ
";
CM_ SG_ 2564468961 CECU18DAB0E1_DIAG_DATA_EXT1 "ﾃﾞｰﾀ
";
CM_ SG_ 2564468961 CECU18DAB0E1_DIAG_DATA "ﾃﾞｰﾀ
";
CM_ SG_ 2564481573 CECU18DAE225_DIAG_DATA_EXT7 "ﾃﾞｰﾀ
";
CM_ SG_ 2564481573 CECU18DAE225_DIAG_DATA_EXT6 "ﾃﾞｰﾀ
";
CM_ SG_ 2564481573 CECU18DAE225_DIAG_DATA_EXT5 "ﾃﾞｰﾀ
";
CM_ SG_ 2564481573 CECU18DAE225_DIAG_DATA_EXT4 "ﾃﾞｰﾀ
";
CM_ SG_ 2564481573 CECU18DAE225_DIAG_DATA_EXT3 "ﾃﾞｰﾀ
";
CM_ SG_ 2564481573 CECU18DAE225_DIAG_DATA_EXT2 "ﾃﾞｰﾀ
";
CM_ SG_ 2564481573 CECU18DAE225_DIAG_DATA_EXT1 "ﾃﾞｰﾀ
";
CM_ SG_ 2564481573 CECU18DAE225_DIAG_DATA "ﾃﾞｰﾀ
";
CM_ SG_ 2564433378 DCM18DA25E2_DIAG_DATA_EXT7 "ﾃﾞｰﾀ
";
CM_ SG_ 2564433378 DCM18DA25E2_DIAG_DATA_EXT6 "ﾃﾞｰﾀ
";
CM_ SG_ 2564433378 DCM18DA25E2_DIAG_DATA_EXT5 "ﾃﾞｰﾀ
";
CM_ SG_ 2564433378 DCM18DA25E2_DIAG_DATA_EXT4 "ﾃﾞｰﾀ
";
CM_ SG_ 2564433378 DCM18DA25E2_DIAG_DATA_EXT3 "ﾃﾞｰﾀ
";
CM_ SG_ 2564433378 DCM18DA25E2_DIAG_DATA_EXT2 "ﾃﾞｰﾀ
";
CM_ SG_ 2564433378 DCM18DA25E2_DIAG_DATA_EXT1 "ﾃﾞｰﾀ
";
CM_ SG_ 2564433378 DCM18DA25E2_DIAG_DATA "ﾃﾞｰﾀ
";
CM_ SG_ 1892 DCM764_7_0_DIAG_DATA "ﾃﾞｰﾀ
";
CM_ SG_ 1892 DCM764_2_0_DIAG_N_PCI_OR_DATA "N_PCI　 or 　ﾃﾞｰﾀ
";
CM_ SG_ 1892 DCM764_1_0_DIAG_N_PCI_OR_DATA "N_PCI　 or 　ﾃﾞｰﾀ
";
CM_ SG_ 1892 DCM764_0_0_DIAG_N_PCI "N_PCI
";
CM_ SG_ 1848 VDC738_7_0_DIAG_DATA "ﾃﾞｰﾀ
";
CM_ SG_ 1848 VDC738_2_0_DIAG_N_PCI_OR_DATA "N_PCI　 or 　ﾃﾞｰﾀ
";
CM_ SG_ 1848 VDC738_1_0_DIAG_N_PCI_OR_DATA "N_PCI　 or 　ﾃﾞｰﾀ
";
CM_ SG_ 1848 VDC738_0_0_DIAG_N_PCI "N_PCI
";
CM_ SG_ 1840 DCM730_7_0_DIAG_DATA "ﾃﾞｰﾀ
";
CM_ SG_ 1840 DCM730_2_0_DIAG_N_PCI_OR_DATA "N_PCI　 or 　ﾃﾞｰﾀ
";
CM_ SG_ 1840 DCM730_1_0_DIAG_N_PCI_OR_DATA "N_PCI　 or 　ﾃﾞｰﾀ
";
CM_ SG_ 1840 DCM730_0_0_DIAG_N_PCI "N_PCI
";
CM_ SG_ 1807 CGW70F_7_0_DIAG_DATA "ﾃﾞｰﾀ
";
CM_ SG_ 1807 CGW70F_2_0_DIAG_N_PCI_OR_DATA "N_PCI　 or 　ﾃﾞｰﾀ
";
CM_ SG_ 1807 CGW70F_1_0_DIAG_N_PCI_OR_DATA "N_PCI　 or 　ﾃﾞｰﾀ
";
CM_ SG_ 1807 CGW70F_0_0_DIAG_N_PCI "N_PCI
";
CM_ SG_ 1774 CECU6EE_7_0_DESTINATION_INFO "仕向地情報
";
CM_ SG_ 1774 CECU6EE_7_4_VEHICLE_SERIES "車系情報
";
CM_ SG_ 1774 CECU6EE_6_0_DESTINATION_CODE "仕向地ｺｰﾄﾞ
";
CM_ SG_ 1774 CECU6EE_5_0_EYE_VERSION_INFO "ｱｲｻｲﾄVer情報
";
CM_ SG_ 1774 CECU6EE_5_4_VEHICLE_TYPE "車型情報
";
CM_ SG_ 1774 CECU6EE_5_6_PRODUCTION_BASE "生産拠点
";
CM_ SG_ 1774 CECU6EE_4_2_WHEEL_DRIVE_TYPE "駆動方式
";
CM_ SG_ 1774 CECU6EE_4_3_3RD_SHEAT_EQUIPMENT "3rdｼｰﾄ有無
";
CM_ SG_ 1774 CECU6EE_4_4_FLG_XMODE "Xﾓｰﾄﾞ有無
";
CM_ SG_ 1774 CECU6EE_4_6_ISS_EQUIPMENT "ISS有無
";
CM_ SG_ 1774 CECU6EE_4_7_TIRE_INFO "ﾀｲﾔ情報
";
CM_ SG_ 1774 CECU6EE_1_0_MSG_COUNTER "ﾒｯｾｰｼﾞｶｳﾝﾀ
";
CM_ SG_ 1774 CECU6EE_1_5_BEV_WHEEL_DRIVE_TYPE "駆動方式(BEV)
";
CM_ SG_ 1774 CECU6EE_0_0_CHECK_SUM "ﾁｪｯｸｻﾑ
";
CM_ SG_ 1773 CECU6ED_7_0_VEHICLE_TYPE_DETAIL "車型情報(詳細)
";
CM_ SG_ 1773 CECU6ED_5_0_TRANSMISSION_TYPE "ﾄﾗﾝｽﾐｯｼｮﾝ情報
";
CM_ SG_ 1773 CECU6ED_5_4_HANDLE "ﾊﾝﾄﾞﾙ情報
";
CM_ SG_ 1773 CECU6ED_4_0_VEHICLE_HEIGHT "車高情報
";
CM_ SG_ 1773 CECU6ED_4_4_SEATHEATER_EQUIPMENT "ｼｰﾄﾋｰﾀｰ有無
";
CM_ SG_ 1773 CECU6ED_3_0_YEAR_CHANGE "年改情報
";
CM_ SG_ 1773 CECU6ED_3_4_HEV_INFO "HEV情報
";
CM_ SG_ 1773 CECU6ED_1_0_MSG_COUNTER "ﾒｯｾｰｼﾞｶｳﾝﾀ
";
CM_ SG_ 1773 CECU6ED_0_0_CHECK_SUM "ﾁｪｯｸｻﾑ
";
CM_ SG_ 1772 CECU6EC_6_0_SMT_EQUIPMENT "SMT有無
";
CM_ SG_ 1772 CECU6EC_6_1_DCCD_EQUIPMENT "DCCD有無
";
CM_ SG_ 1772 CECU6EC_6_2_PRG_EQUIPMENT "PRG有無
";
CM_ SG_ 1772 CECU6EC_6_3_DKY_EQUIPMENT "DKY有無
";
CM_ SG_ 1772 CECU6EC_6_4_PSC_EQUIPMENT "PSC有無
";
CM_ SG_ 1772 CECU6EC_5_0_CCU_EQUIPMENT "CCU有無
";
CM_ SG_ 1772 CECU6EC_5_1_EAM_EQUIPMENT "EAM有無
";
CM_ SG_ 1772 CECU6EC_5_2_RCR_L_EQUIPMENT "RCR-L有無
";
CM_ SG_ 1772 CECU6EC_5_3_RCR_R_EQUIPMENT "RCR-R有無
";
CM_ SG_ 1772 CECU6EC_5_4_FCR_L_EQUIPMENT "FCR-L有無
";
CM_ SG_ 1772 CECU6EC_5_5_FCR_R_EQUIPMENT "FCR-R有無
";
CM_ SG_ 1772 CECU6EC_5_6_VSS_EQUIPMENT "VSS有無
";
CM_ SG_ 1772 CECU6EC_5_7_RES_EQUIPMENT "RES有無
";
CM_ SG_ 1772 CECU6EC_4_0_LCT_EQUIPMENT "LCT有無
";
CM_ SG_ 1772 CECU6EC_4_1_DAM_EQUIPMENT "DAM有無
";
CM_ SG_ 1772 CECU6EC_4_2_MVS_EQUIPMENT "MVS有無
";
CM_ SG_ 1772 CECU6EC_4_3_TCU_EQUIPMENT "TCU有無
";
CM_ SG_ 1772 CECU6EC_4_4_TPM_EQUIPMENT "TPM有無
";
CM_ SG_ 1772 CECU6EC_4_5_DCM_EQUIPMENT "DCM有無
";
CM_ SG_ 1772 CECU6EC_4_6_MED_EQUIPMENT "MED有無
";
CM_ SG_ 1772 CECU6EC_4_7_MEP_EQUIPMENT "MEP有無
";
CM_ SG_ 1772 CECU6EC_3_0_DATA_STATE "ﾃﾞｰﾀ状態
";
CM_ SG_ 1772 CECU6EC_3_1_EYE_EQUIPMENT "EYE有無
";
CM_ SG_ 1772 CECU6EC_3_2_HEV_EQUIPMENT "HEV有無
";
CM_ SG_ 1772 CECU6EC_3_3_SNR_EQUIPMENT "SNR有無
";
CM_ SG_ 1772 CECU6EC_3_4_EPB_EQUIPMENT "EPB有無
";
CM_ SG_ 1772 CECU6EC_3_5_DMS_EQUIPMENT "DMS有無
";
CM_ SG_ 1772 CECU6EC_3_6_BST_EQUIPMENT "BST有無
";
CM_ SG_ 1772 CECU6EC_3_7_MCA_EQUIPMENT "MCA有無
";
CM_ SG_ 1772 CECU6EC_1_0_MSG_COUNTER "ﾒｯｾｰｼﾞｶｳﾝﾀ
";
CM_ SG_ 1772 CECU6EC_0_0_CHECK_SUM "ﾁｪｯｸｻﾑ
";
CM_ SG_ 996 CECU3E4_7_0_SSM_COMM_INFO "SSM通信情報
";
CM_ SG_ 996 CECU3E4_6_0_CHARGE_LEVEL_ENG_RUN "エンジンRUN中充電レベル
";
CM_ SG_ 996 CECU3E4_6_4_CHARGE_LEVEL_IGN_ON "IG-ONエンスト中充電レベル
";
CM_ SG_ 996 CECU3E4_5_0_GENERATOR_OVER_FLG "発電機過大ﾌﾗｸﾞ
";
CM_ SG_ 996 CECU3E4_5_3_DIAG_COM_REQ "ﾃﾚﾏ診断通信要求
";
CM_ SG_ 996 CECU3E4_5_4_HEADS_UP_FLG "注意喚起ﾌﾗｸﾞ
";
CM_ SG_ 996 CECU3E4_3_0_WASH_CAR_MODE_STS "洗車モード状態
";
CM_ SG_ 996 CECU3E4_2_0_POW_ON_FIX_MODE_STS "電源ON固定モード状態
";
CM_ SG_ 996 CECU3E4_2_3_PET_MODE_STS "ペットモード状態
";
CM_ SG_ 996 CECU3E4_2_6_SHUT_DOWN_MODE_STS "シャットダウンモード遷移可否状態
";
CM_ SG_ 996 CECU3E4_2_7_OCCUPATION_CSTM "乗員検知設定値
";
CM_ SG_ 996 CECU3E4_1_0_MSG_COUNTER "ﾒｯｾｰｼﾞｶｳﾝﾀ
";
CM_ SG_ 996 CECU3E4_0_0_CHECK_SUM "ﾁｪｯｸｻﾑ
";
CM_ SG_ 1280 CGW500_1_4_ActiveWakeUpBit "Active Wakeup ﾌﾗｸﾞ
";
CM_ SG_ 1280 CGW500_0_0_SourceNodeID "送信元ID
";
CM_ SG_ 1633 CECU661_7_0_PRESENT_TIME_SEC "現在時刻(秒)
";
CM_ SG_ 1633 CECU661_6_0_PRESENT_TIME_MIN "現在時刻(分)
";
CM_ SG_ 1633 CECU661_5_0_PRESENT_TIME_HOUR "現在時刻(時)
";
CM_ SG_ 1633 CECU661_4_0_PRESENT_DAY "現在年月日(日)
";
CM_ SG_ 1633 CECU661_3_0_PRESENT_MONTH "現在年月日(月)
";
CM_ SG_ 1633 CECU661_2_0_PRESENT_YEAR "現在年月日(年)
";
CM_ SG_ 1632 CGW660_7_0_COUNT_TIME "時間ｶｳﾝﾀ
";
CM_ SG_ 1632 CGW660_3_0_COUNT_TRIP "Tripｶｳﾝﾀ
";
CM_ SG_ 1632 CGW660_1_0_SUB_ID "ｻﾌﾞID
";
CM_ SG_ 1752 DCM6D8_7_0_PRESENT_TIME_SEC "現在時刻情報(秒)
";
CM_ SG_ 1752 DCM6D8_6_0_PRESENT_TIME_MIN "現在時刻情報(分)
";
CM_ SG_ 1752 DCM6D8_5_0_PRESENT_TIME_HOUR "現在時刻情報(時)
";
CM_ SG_ 1752 DCM6D8_4_0_PRESENT_DAY "現在時刻情報(日)
";
CM_ SG_ 1752 DCM6D8_3_0_PRESENT_MONTH "現在時刻情報(月)
";
CM_ SG_ 1752 DCM6D8_2_0_DATA_COLLECT_INTERVAL "データ収集間隔設定
";
CM_ SG_ 1752 DCM6D8_1_0_MSG_COUNTER "ﾒｯｾｰｼﾞｶｳﾝﾀ
";
CM_ SG_ 1752 DCM6D8_1_4_PRESS_SOS_BUTTON "SOSﾎﾞﾀﾝ押下
";
CM_ SG_ 1752 DCM6D8_0_0_CHECK_SUM "ﾁｪｯｸｻﾑ
";
CM_ SG_ 1744 CECU6D0_4_0_OTA_ABORT "OTA中止
";
CM_ SG_ 1744 CECU6D0_4_1_OTA_SUSPEND "OTA中断
";
CM_ SG_ 1744 CECU6D0_4_2_OTA_SEQUENCE "OTA実行シーケンス
";
CM_ SG_ 1744 CECU6D0_1_0_MSG_COUNTER "ﾒｯｾｰｼﾞｶｳﾝﾀ
";
CM_ SG_ 1744 CECU6D0_1_4_OTA_STATUS_UPDATE "OTAステータス アップデート実行中
";
CM_ SG_ 1744 CECU6D0_0_0_CHECK_SUM "ﾁｪｯｸｻﾑ
";
CM_ SG_ 1743 DCM6CF_6_6_AACN_FLG "AACNフラグ
";
CM_ SG_ 1743 DCM6CF_5_0_EMERGENCY_CALL_ON_OFF "緊急通報ON/OFF
";
CM_ SG_ 1743 DCM6CF_4_2_STR_HEATER_ON_OFF "ｽﾃｱﾘﾝｸﾞﾋｰﾀｰ ON/OFF
";
CM_ SG_ 1743 DCM6CF_3_0_RES_CONTRACT_INFO "ﾘﾓｽﾀ契約情報
";
CM_ SG_ 1743 DCM6CF_3_1_REQ_ST_ON "Request ST ON
";
CM_ SG_ 1743 DCM6CF_3_3_ON_SIGN "E/G start signal
";
CM_ SG_ 1743 DCM6CF_3_5_REQ_PARKLIGHT_HORN "Request park light ＆Horn
";
CM_ SG_ 1743 DCM6CF_2_1_DCM_FAILURE_STATUS "DCM故障ｽﾃｰﾀｽ
";
CM_ SG_ 1743 DCM6CF_2_2_REQ_WINDOW_STATUS "窓&ｻﾝﾙｰﾌ開閉状態要求
";
CM_ SG_ 1743 DCM6CF_1_0_MSG_COUNTER "ﾒｯｾｰｼﾞｶｳﾝﾀ
";
CM_ SG_ 1743 DCM6CF_1_6_DKY_PROV_STS "DKCU向けDKY契約状態通知
";
CM_ SG_ 1743 DCM6CF_1_7_PNC_PROV_STS "EVCC向けPnC契約状態通知
";
CM_ SG_ 1743 DCM6CF_0_0_CHECK_SUM "ﾁｪｯｸｻﾑ
";
CM_ SG_ 1630 DCM65E_2_0_DATA2 "Immobilizer Data1
";
CM_ SG_ 1630 DCM65E_1_0_MSG_COUNTER "ﾒｯｾｰｼﾞｶｳﾝﾀ
";
CM_ SG_ 1630 DCM65E_1_4_DATA1 "Immobilizer Mode
";
CM_ SG_ 1630 DCM65E_0_0_CHECK_SUM "ﾁｪｯｸｻﾑ
";
CM_ SG_ 1301 DCM515_1_4_ActiveWakeUpBit "Active Wakeup ﾌﾗｸﾞ
";
CM_ SG_ 1301 DCM515_0_0_SourceNodeID "送信元ID
";
CM_ SG_ 1749 CECU6D5_6_0_CSTM_FMHD "ウェルカムランプ(降車)
";
CM_ SG_ 1749 CECU6D5_5_0_CSTM_WRH "ワイパ連動オートライト機能ON/OFF設定
";
CM_ SG_ 1749 CECU6D5_5_1_CSTM_LMHD "ウェルカムランプ(乗車)
";
CM_ SG_ 1749 CECU6D5_5_3 "北米ウェルカムランプ(リービング)（カスタマイズ）
";
CM_ SG_ 1749 CECU6D5_5_5_CSTM_HBA "HBA 有無設定
";
CM_ SG_ 1749 CECU6D5_5_7_ADB_ACTIVE "ADB有無設定
";
CM_ SG_ 1749 CECU6D5_4_0_JUDGE_ILL "照度判定
";
CM_ SG_ 1749 CECU6D5_4_1_HEADLAMP_AUTO_SW "ライティングAUTO SW 出力信号
";
CM_ SG_ 1749 CECU6D5_4_2_IND_ACTIVE_HBA "HBA 作動灯
";
CM_ SG_ 1749 CECU6D5_4_4_FGT_LGTOFF_WARNING "ライト消し忘れ警報
";
CM_ SG_ 1749 CECU6D5_3_0_CRN_R_REQ "コーナリングランプR 出力要求
";
CM_ SG_ 1749 CECU6D5_3_2_CRN_L_REQ "コーナリングランプL 出力要求
";
CM_ SG_ 1749 CECU6D5_3_4_FMH "フォローミーホーム出力情報
";
CM_ SG_ 1749 CECU6D5_3_5_LMH "リードミーホーム出力情報
";
CM_ SG_ 1749 CECU6D5_2_0_LGT_1 "ライティング1 リレー出力要求
";
CM_ SG_ 1749 CECU6D5_2_1_LGT_LO "ライティングLo リレー出力要求
";
CM_ SG_ 1749 CECU6D5_2_2_LGT_HI "ライティングHi リレー出力要求
";
CM_ SG_ 1749 CECU6D5_2_4_FFOG_RELAY_REQ "Fフォグランプリレー出力要求
";
CM_ SG_ 1749 CECU6D5_2_5_RFOG_RELAY_REQ "Rフォグランプリレー出力要求
";
CM_ SG_ 1749 CECU6D5_2_6_LGT_DRL "DRL リレー出力要求
";
CM_ SG_ 1749 CECU6D5_1_0_MSG_COUNTER "ﾒｯｾｰｼﾞｶｳﾝﾀ
";
CM_ SG_ 1749 CECU6D5_0_0_CHECK_SUM "ﾁｪｯｸｻﾑ
";
CM_ SG_ 1753 CECU6D9_2_0_RCC_DOOR_LOCK_REQ "RCC ドアロック要求
";
CM_ SG_ 1753 CECU6D9_2_1_RCC_KEY_SEARCH_REQ "RCC アクセスキー確認要求
";
CM_ SG_ 1753 CECU6D9_2_2_RCC_BWAM_SETTING "バッテリ温調設定
";
CM_ SG_ 1753 CECU6D9_1_0_MSG_COUNTER "ﾒｯｾｰｼﾞｶｳﾝﾀ
";
CM_ SG_ 1753 CECU6D9_1_4_RCC_FLG "RCC実行中フラグ
";
CM_ SG_ 1753 CECU6D9_0_0_CHECK_SUM "ﾁｪｯｸｻﾑ
";
CM_ SG_ 723 CECU2D3_2_0_IGA_ON_REQUEST "IGaON要求
";
CM_ SG_ 723 CECU2D3_2_1_IGA_OFF_REQUEST "IGaOFF要求
";
CM_ SG_ 723 CECU2D3_2_2_IGB_ON_REQUEST "IGbON要求
";
CM_ SG_ 723 CECU2D3_2_3_IGB_OFF_REQUEST "IGbOFF要求
";
CM_ SG_ 723 CECU2D3_2_4_READY_ON_REQUEST "ReadyON要求
";
CM_ SG_ 723 CECU2D3_2_5_IGA_STATE "IGa状態
";
CM_ SG_ 723 CECU2D3_2_6_IGB_STATE "IGb状態
";
CM_ SG_ 723 CECU2D3_2_7_FACT_MODE "電源遷移制限モード
";
CM_ SG_ 723 CECU2D3_1_0_MSG_COUNTER "ﾒｯｾｰｼﾞｶｳﾝﾀ
";
CM_ SG_ 723 CECU2D3_0_0_CHECK_SUM "ﾁｪｯｸｻﾑ
";
CM_ SG_ 1748 CECU6D4_4_0_TARGET_POS_PRG "PRG作動停止位置(目標位置)
";
CM_ SG_ 1748 CECU6D4_2_0_REQ_PRG_STOP "PRG作動停止要求
";
CM_ SG_ 1748 CECU6D4_2_1_REQ_PRG_ACT "PRG作動要求
";
CM_ SG_ 1748 CECU6D4_1_0_MSG_COUNTER "メッセージカウンタ
";
CM_ SG_ 1748 CECU6D4_0_0_CHECK_SUM "チェックサム
";
CM_ SG_ 1736 CECU6C8_5_0_RSRSST "ステータス値
";
CM_ SG_ 1736 CECU6C8_4_0_RSRSKID "キーID
";
CM_ SG_ 1736 CECU6C8_4_4_RSRSNT "コマンド通知・応答
";
CM_ SG_ 1736 CECU6C8_2_0_RSRS_SlotID "Slot ID設定値
";
CM_ SG_ 1736 CECU6C8_1_0_MSG_COUNT "メッセージカウンタ
";
CM_ SG_ 1736 CECU6C8_1_4_RSRSCOM "コマンド応答種類
";
CM_ SG_ 1736 CECU6C8_0_0_CHECKSUM "チェックサム
";
CM_ SG_ 1701 CECU6A5_10_0_DCM_SHUTDOWN_RESULT "リモートシャットダウン処理結果
";
CM_ SG_ 1701 CECU6A5_8_0_NOTIFICATION_REQ "うっかり通知要求
";
CM_ SG_ 1701 CECU6A5_6_0_VEHICLE_STATE_INFO "車両状態通知
";
CM_ SG_ 1701 CECU6A5_5_0_ALERT_FACTOR "注意喚起要因
";
CM_ SG_ 1701 CECU6A5_3_0_TARGET_FUNC "対象機能
";
CM_ SG_ 1701 CECU6A5_2_0_E2E_COUNTER "E2Eカウンタ
";
CM_ SG_ 1701 CECU6A5_1_0_E2E_CRC "CRC
";
CM_ SG_ 1739 DCM6CB_7_0 "Reserve
";
CM_ SG_ 1739 DCM6CB_5_0_DKY_SLOT_ID "Degital Key SlotID
";
CM_ SG_ 1739 DCM6CB_4_0_DKY_COM_REQ "Degital Keyコマンド要求
";
CM_ SG_ 1739 DCM6CB_3_5_PNC_SW_REQ_SRV "SVISからのPnCサービスOnOff切替要求
";
CM_ SG_ 1739 DCM6CB_2_0_SHUTDOWN_REQ "リモートシャットダウン要求
";
CM_ SG_ 1739 DCM6CB_2_3_IGB_OFF_REQUEST "IGb OFF電源遷移要求
";
CM_ SG_ 1739 DCM6CB_2_4_IGB_ON_REQUEST "IGb ON電源遷移要求
";
CM_ SG_ 1739 DCM6CB_2_5_REARGATE_UNLOCK_REQ "ﾘﾓｰﾄﾘｱｹﾞｰﾄｱﾝﾛｯｸ要求
";
CM_ SG_ 1739 DCM6CB_2_6_DOOR_UNLOCK_REQ "ﾘﾓｰﾄﾄﾞｱｱﾝﾛｯｸ要求
";
CM_ SG_ 1739 DCM6CB_2_7_DOOR_LOCK_REQUEST "ﾘﾓｰﾄﾄﾞｱﾛｯｸ要求
";
CM_ SG_ 1739 DCM6CB_1_0_MSG_COUNTER "ﾒｯｾｰｼﾞｶｳﾝﾀ
";
CM_ SG_ 1739 DCM6CB_1_4_REQ_SVR_HAZARD_ON "次世代盗難車両追跡用ハザード点滅要求
";
CM_ SG_ 1739 DCM6CB_1_5_HORNHZRD_DEACT_REQ "ﾘﾓｰﾄﾎｰﾝ&ﾊｻﾞｰﾄﾞ停止要求
";
CM_ SG_ 1739 DCM6CB_1_6_HAZARD_ACT_REQ "ﾘﾓｰﾄﾊｻﾞｰﾄﾞ動作要求
";
CM_ SG_ 1739 DCM6CB_1_7_HORNHAZARD_ACT_REQ "ﾘﾓｰﾄﾎｰﾝ&ﾊｻﾞｰﾄﾞ動作要求
";
CM_ SG_ 1739 DCM6CB_0_0_CHECK_SUM "ﾁｪｯｸｻﾑ
";
CM_ SG_ 1155 DCM483_18_0_DEP_TIM4_WEEKDAY_REQ "出発時刻プレコン曜日設定要求_ID4
";
CM_ SG_ 1155 DCM483_16_0_DEP_TIM4_ST_TIME_REQ "出発時刻プレコン開始時刻設定要求_ID4
";
CM_ SG_ 1155 DCM483_15_5_DEP_TIM4_SW_REQ "出発時刻プレコンオン・オフ状態設定要求_ID4
";
CM_ SG_ 1155 DCM483_15_7_DEP_TIM4_PERFLG_REQ "出発時刻プレコンパフォーマンスモードフラグ要求_ID4
";
CM_ SG_ 1155 DCM483_14_0_DEP_TIM3_WEEKDAY_REQ "出発時刻プレコン曜日設定要求_ID3
";
CM_ SG_ 1155 DCM483_12_0_DEP_TIM3_ST_TIME_REQ "出発時刻プレコン開始時刻設定要求_ID3
";
CM_ SG_ 1155 DCM483_11_5_DEP_TIM3_SW_REQ "出発時刻プレコンオン・オフ設定要求_ID3
";
CM_ SG_ 1155 DCM483_11_7_DEP_TIM3_PERFLG_REQ "出発時刻プレコンパフォーマンスモードフラグ要求_ID3
";
CM_ SG_ 1155 DCM483_10_0_DEP_TIM2_WEEKDAY_REQ "出発時刻プレコン曜日設定要求_ID2
";
CM_ SG_ 1155 DCM483_8_0_DEP_TIM2_ST_TIME_REQ "出発時刻プレコン開始時刻設定要求_ID2
";
CM_ SG_ 1155 DCM483_7_7_DEP_TIM2_PERFLG_REQ "出発時刻プレコンパフォーマンスモードフラグ要求_ID2
";
CM_ SG_ 1155 DCM483_7_5_DEP_TIM2_SW_REQ "出発時刻プレコンオン・オフ設定要求_ID2
";
CM_ SG_ 1155 DCM483_6_0_DEP_TIM1_WEEKDAY_REQ "出発時刻プレコン曜日設定要求_ID1
";
CM_ SG_ 1155 DCM483_4_0_DEP_TIM1_ST_TIME_REQ "出発時刻プレコン開始時刻設定要求_ID1
";
CM_ SG_ 1155 DCM483_3_5_DEP_TIM1_SW_REQ "出発時刻プレコンオン・オフ設定要求_ID1
";
CM_ SG_ 1155 DCM483_3_7_DEP_TIM1_PERFLG_REQ "出発時刻プレコンパフォーマンスモードフラグ要求_ID1
";
CM_ SG_ 1155 DCM483_2_0_E2E_COUNTER "E2Eカウンタ
";
CM_ SG_ 1155 DCM483_0_0_E2E_CRC "CRC
";
CM_ SG_ 1154 DCM482_30_0_CHG_BTN_SET_REQ "充電ボタン設定要求
";
CM_ SG_ 1154 DCM482_29_0_FED_LOLMT_REQ "給電量下限値変更要求
";
CM_ SG_ 1154 DCM482_28_0_ACCHG_CURUPLMT_REQ "AC充電電流上限設定値変更要求
";
CM_ SG_ 1154 DCM482_28_4_DCCHG_PWRUPLMT_REQ "DC充電電力上限設定値変更要求
";
CM_ SG_ 1154 DCM482_27_0_CHG_HILMT_REQ "充電量上限値変更要求
";
CM_ SG_ 1154 DCM482_26_0_TIM4_CHG_WEEKDAY_REQ "タイマー充電曜日変更要求_ID4
";
CM_ SG_ 1154 DCM482_24_0_TIM4_CHG_ENDTIME_REQ "タイマー充電終了時刻変更要求_ID4
";
CM_ SG_ 1154 DCM482_22_0_TIM4_CHG_SETTYPE_REQ "タイマー充電タイプ変更要求_ID4
";
CM_ SG_ 1154 DCM482_22_2_TIM4_CHG_ST_TIME_REQ "タイマー充電開始時刻変更要求_ID4
";
CM_ SG_ 1154 DCM482_21_5_TIM4_CHG_SW_REQ "タイマー充電オン/オフ設定要求_ID4
";
CM_ SG_ 1154 DCM482_20_0_TIM3_CHG_WEEKDAY_REQ "タイマー充電曜日変更要求_ID3
";
CM_ SG_ 1154 DCM482_18_0_TIM3_CHG_ENDTIME_REQ "タイマー充電終了時刻変更要求_ID3
";
CM_ SG_ 1154 DCM482_16_0_TIM3_CHG_SETTYPE_REQ "タイマー充電タイプ変更要求_ID3
";
CM_ SG_ 1154 DCM482_16_2_TIM3_CHG_ST_TIME_REQ "タイマー充電開始時刻変更要求_ID3
";
CM_ SG_ 1154 DCM482_15_5_TIM3_CHG_SW_REQ "タイマー充電オン/オフ設定要求_ID3
";
CM_ SG_ 1154 DCM482_14_0_TIM2_CHG_WEEKDAY_REQ "タイマー充電曜日変更要求_ID2
";
CM_ SG_ 1154 DCM482_12_0_TIM2_CHG_ENDTIME_REQ "タイマー充電終了時刻変更要求_ID2
";
CM_ SG_ 1154 DCM482_10_0_TIM2_CHG_SETTYPE_REQ "タイマー充電タイプ変更要求_ID2
";
CM_ SG_ 1154 DCM482_10_2_TIM2_CHG_ST_TIME_REQ "タイマー充電開始時刻変更要求_ID2
";
CM_ SG_ 1154 DCM482_9_5_TIM2_CHG_SW_REQ "タイマー充電オン/オフ設定要求_ID2
";
CM_ SG_ 1154 DCM482_8_0_TIM1_CHG_WEEKDAY_REQ "タイマー充電曜日変更要求_ID1
";
CM_ SG_ 1154 DCM482_6_0_TIM1_CHG_ENDTIME_REQ "タイマー充電終了時刻変更要求_ID1
";
CM_ SG_ 1154 DCM482_4_0_TIM1_CHG_SETTYPE_REQ "タイマー充電タイプ変更要求_ID1
";
CM_ SG_ 1154 DCM482_4_2_TIM1_CHG_ST_TIME_REQ "タイマー充電開始時刻変更要求_ID1
";
CM_ SG_ 1154 DCM482_3_5_TIM1_CHG_SW_REQ "タイマー充電オン/オフ設定要求_ID1
";
CM_ SG_ 1154 DCM482_2_0_E2E_COUNTER "E2Eカウンタ
";
CM_ SG_ 1154 DCM482_0_0_E2E_CRC "CRC
";
CM_ SG_ 1113 DCM459_7_0_BYTE5 "開発用変数5
";
CM_ SG_ 1113 DCM459_6_0_BYTE4 "開発用変数4
";
CM_ SG_ 1113 DCM459_5_0_BYTE3 "開発用変数3
";
CM_ SG_ 1113 DCM459_4_0_BYTE2 "開発用変数2
";
CM_ SG_ 1113 DCM459_3_0_BYTE1 "開発用変数1
";
CM_ SG_ 1113 DCM459_2_0_E2E_COUNTER "E2Eカウンタ
";
CM_ SG_ 1113 DCM459_0_0_E2E_CRC "CRC
";
CM_ SG_ 1107 DCM453_31_0_BYTE29 "開発用変数29
";
CM_ SG_ 1107 DCM453_30_0_BYTE28 "開発用変数28
";
CM_ SG_ 1107 DCM453_29_0_BYTE27 "開発用変数27
";
CM_ SG_ 1107 DCM453_28_0_BYTE26 "開発用変数26
";
CM_ SG_ 1107 DCM453_27_0_BYTE25 "開発用変数25
";
CM_ SG_ 1107 DCM453_26_0_BYTE24 "開発用変数24
";
CM_ SG_ 1107 DCM453_25_0_BYTE23 "開発用変数23
";
CM_ SG_ 1107 DCM453_24_0_BYTE22 "開発用変数22
";
CM_ SG_ 1107 DCM453_23_0_BYTE21 "開発用変数21
";
CM_ SG_ 1107 DCM453_22_0_BYTE20 "開発用変数20
";
CM_ SG_ 1107 DCM453_21_0_BYTE19 "開発用変数19
";
CM_ SG_ 1107 DCM453_20_0_BYTE18 "開発用変数18
";
CM_ SG_ 1107 DCM453_19_0_BYTE17 "開発用変数17
";
CM_ SG_ 1107 DCM453_18_0_BYTE16 "開発用変数16
";
CM_ SG_ 1107 DCM453_17_0_BYTE15 "開発用変数15
";
CM_ SG_ 1107 DCM453_16_0_BYTE14 "開発用変数14
";
CM_ SG_ 1107 DCM453_15_0_BYTE13 "開発用変数13
";
CM_ SG_ 1107 DCM453_14_0_BYTE12 "開発用変数12
";
CM_ SG_ 1107 DCM453_13_0_BYTE11 "開発用変数11
";
CM_ SG_ 1107 DCM453_12_0_BYTE10 "開発用変数10
";
CM_ SG_ 1107 DCM453_11_0_BYTE9 "開発用変数9
";
CM_ SG_ 1107 DCM453_10_0_BYTE8 "開発用変数8
";
CM_ SG_ 1107 DCM453_9_0_BYTE7 "開発用変数7
";
CM_ SG_ 1107 DCM453_8_0_BYTE6 "開発用変数6
";
CM_ SG_ 1107 DCM453_7_0_BYTE5 "開発用変数5
";
CM_ SG_ 1107 DCM453_6_0_BYTE4 "開発用変数4
";
CM_ SG_ 1107 DCM453_5_0_BYTE3 "開発用変数3
";
CM_ SG_ 1107 DCM453_4_0_BYTE2 "開発用変数2
";
CM_ SG_ 1107 DCM453_3_0_BYTE1 "開発用変数1
";
CM_ SG_ 1107 DCM453_2_0_E2E_COUNTER "E2Eカウンタ
";
CM_ SG_ 1107 DCM453_0_0_E2E_CRC "CRC
";
CM_ SG_ 1705 MVS6A9_6_0_CSTM_HITCHLINE_DSPREQ "ヒッチボールガイド線カスタマイズ表示要求
";
CM_ SG_ 1705 MVS6A9_6_2_CSTM_HITCHLINE "ヒッチボールガイド線ON/OFF情報
";
CM_ SG_ 1705 MVS6A9_5_0_RR_WIDE_VIEW_SW_STATE "リアワイドビューSW表示状態
";
CM_ SG_ 1705 MVS6A9_5_2_RR_NRW_VIEW_SW_STATE "リアナロービューSW表示状態
";
CM_ SG_ 1705 MVS6A9_5_4_HITCH_VIEW_SW_STATE "ヒッチボールビューSW表示状態
";
CM_ SG_ 1705 MVS6A9_4_0_FT_NRW_VIEW_SW_STATE "フロントナロービューSW表示状態
";
CM_ SG_ 1705 MVS6A9_4_2_FT_WIDE_VIEW_SW_STATE "フロントワイドビューSW表示状態
";
CM_ SG_ 1705 MVS6A9_4_4_SIDE_VIEW_SW_STATE "サイドビューSW表示状態
";
CM_ SG_ 1705 MVS6A9_4_6_3D_VIEW_SW_STATE "３DビューSW表示状態
";
CM_ SG_ 1705 MVS6A9_3_0_CSTM_AUTO_DISPLAY_SET "自動表示カスタマイズ機能有無
";
CM_ SG_ 1705 MVS6A9_3_1_CSTM_AUTO_DISPLAY "自動表示カスタマイズ設定
";
CM_ SG_ 1705 MVS6A9_3_2_VIEW_MODE "カメラ画面表示モード
";
CM_ SG_ 1705 MVS6A9_3_5_STOP_SWITCH "カメラ表示停止スイッチ操作可否
";
CM_ SG_ 1705 MVS6A9_3_6_CSTM_HITCH_VIEW "ヒッチボールビュー有無
";
CM_ SG_ 1705 MVS6A9_2_0_CURRENT_VIEW "映像出力情報
";
CM_ SG_ 1705 MVS6A9_2_5_HOLD_TIME "カメラ表示待ち時間(4カメラ用)
";
CM_ SG_ 1705 MVS6A9_1_0_MSG_COUNTER "ﾒｯｾｰｼﾞｶｳﾝﾀ
";
CM_ SG_ 1705 MVS6A9_1_4_FAIL_MVS "MVSﾌｪｰﾙﾌﾗｸﾞ
";
CM_ SG_ 1705 MVS6A9_1_5_FAIL_MVS_CAUSE "MVSﾌｪｰﾙ通知(FCTI向け)
";
CM_ SG_ 1705 MVS6A9_0_0_CHECK_SUM "ﾁｪｯｸｻﾑ
";
CM_ SG_ 930 MET3A2_7_0_FUEL_AMOUNT "残燃料表示
";
CM_ SG_ 930 MET3A2_6_0_SEATBELT_RR_RH "ｼｰﾄﾍﾞﾙﾄﾊﾞｯｸﾙSW　後席右
";
CM_ SG_ 930 MET3A2_6_1_SEATBELT_RR_CTR "ｼｰﾄﾍﾞﾙﾄﾊﾞｯｸﾙSW　後席中央
";
CM_ SG_ 930 MET3A2_6_2_SEATBELT_RR_LH "ｼｰﾄﾍﾞﾙﾄﾊﾞｯｸﾙSW　後席左
";
CM_ SG_ 930 MET3A2_6_3_SEATBELT_THIRD_RH "ｼｰﾄﾍﾞﾙﾄﾊﾞｯｸﾙSW　3rd後席右
";
CM_ SG_ 930 MET3A2_6_4_SEATBELT_THIRD_CTR "ｼｰﾄﾍﾞﾙﾄﾊﾞｯｸﾙSW　3rd後席中央
";
CM_ SG_ 930 MET3A2_6_5_SEATBELT_THIRD_LH "ｼｰﾄﾍﾞﾙﾄﾊﾞｯｸﾙSW　3rd後席左
";
CM_ SG_ 930 MET3A2_5_0_FLG_RR_REMINDER "幼児置き去り警報実施フラグ
";
CM_ SG_ 930 MET3A2_2_0_ODO_DETAIL "オドﾒｰﾀ値
";
CM_ SG_ 930 MET3A2_1_0_MSG_COUNTER "ﾒｯｾｰｼﾞｶｳﾝﾀ
";
CM_ SG_ 930 MET3A2_1_4_FAIL_DISP "MET表示フェールフラグ
";
CM_ SG_ 930 MET3A2_0_0_CHECK_SUM "ﾁｪｯｸｻﾑ
";
CM_ SG_ 1677 MET68D_7_0_STATUS_WASHER_LAMP "ｳｫｯｼｬ残量警告灯状態
";
CM_ SG_ 1677 MET68D_7_1_OILPRESSURE_SW "ｵｲﾙﾌﾟﾚｯｼｬSW状態
";
CM_ SG_ 1677 MET68D_7_2_FLG_EAM "EAM車両装備情報
";
CM_ SG_ 1677 MET68D_7_3_CSTM_IND_RED "ｱｲｻｲﾄﾓﾆﾀｰ変更設定赤色ｲﾝｼﾞｹｰﾀ
";
CM_ SG_ 1677 MET68D_7_4_CSTM_IND_YELLOW "ｱｲｻｲﾄﾓﾆﾀｰ変更設定黄色ｲﾝｼﾞｹｰﾀ
";
CM_ SG_ 1677 MET68D_7_5_CSTM_IND_GREEN "ｱｲｻｲﾄﾓﾆﾀｰ変更設定緑色ｲﾝｼﾞｹｰﾀ
";
CM_ SG_ 1677 MET68D_7_6_REQ_CSTM_SRH "SRHｶｽﾀﾏｲｽﾞ変更要求
";
CM_ SG_ 1677 MET68D_7_7_CSTM_SRH "SRHｶｽﾀﾏｲｽﾞ変更設定
";
CM_ SG_ 1677 MET68D_6_5_REQ_CHG_CSTM_RAB "RABｶｽﾀﾏｲｽﾞ要求変更
";
CM_ SG_ 1677 MET68D_6_6_CSTM_RAB "ｿﾅｰｶｽﾀﾏｲｽﾞ変更設定(RABON/OFF)
";
CM_ SG_ 1677 MET68D_6_7_CSTM_SONNER "ｿﾅｰｶｽﾀﾏｲｽﾞ変更設定(ｿﾅｰON/OFF)
";
CM_ SG_ 1677 MET68D_5_0_TEMP_FOR_PPA "歩行者保護A/B用温度
";
CM_ SG_ 1677 MET68D_2_0_ODO "ｵﾄﾞﾒｰﾀ値
";
CM_ SG_ 1677 MET68D_1_0_MSG_COUNTER "ﾒｯｾｰｼﾞｶｳﾝﾀ
";
CM_ SG_ 1677 MET68D_1_4_RESET_CSTM_TPMS_RAEB "ｶｽﾀﾏｲｽﾞﾘｾｯﾄ要求(TPMS/RAEB)
";
CM_ SG_ 1677 MET68D_1_5_REQ_CHG_CSTM_TPMS "TPMSｶｽﾀﾏｲｽﾞ要求変更
";
CM_ SG_ 1677 MET68D_1_6_CSTM_TIRE_UNIT "ﾀｲﾔ空気圧表示単位設定
";
CM_ SG_ 1677 MET68D_0_0_CHECK_SUM "ﾁｪｯｸｻﾑ
";
CM_ SG_ 1676 MET68C_7_0_CSTM_OUTTEMP "外気温ｶｽﾀﾏｲｽﾞ設定値
";
CM_ SG_ 1676 MET68C_4_6_UNIT_DEGREE "外気温単位設定値
";
CM_ SG_ 1676 MET68C_3_0_MET_SW_STATE "ﾒｰﾀSW操作状態ﾌﾗｸﾞ
";
CM_ SG_ 1676 MET68C_3_3_PERMIT_MFD_CSTM "MFDｶｽﾀﾏｲｽﾞ許可ﾌﾗｸﾞ
";
CM_ SG_ 1676 MET68C_3_5_FLG_RR_AC_PANEL "リアﾋｰｺﾝﾊﾟﾈﾙ装備
";
CM_ SG_ 1676 MET68C_3_6_FLG_SEAT_VENT "シート空調装備情報
";
CM_ SG_ 1676 MET68C_3_7_FLG_SEAT_HEAT "ｼｰﾄﾋｰﾀ装備情報
";
CM_ SG_ 1676 MET68C_2_0_CRUISING_RADIUS "航続可能距離表示値
";
CM_ SG_ 1676 MET68C_1_0_MSG_COUNTER "ﾒｯｾｰｼﾞｶｳﾝﾀ
";
CM_ SG_ 1676 MET68C_1_4_CSTM_HU "HU有無ﾌﾗｸﾞ
";
CM_ SG_ 1676 MET68C_1_5_CSTM_BRAND_NAME "ブランドフラグ
";
CM_ SG_ 1676 MET68C_0_0_CHECK_SUM "ﾁｪｯｸｻﾑ
";
CM_ SG_ 922 MET39A_7_0_SET_LANGUAGE "各国言語設定
";
CM_ SG_ 922 MET39A_7_5_ACTIVE_MET_CSTM "車両ｶｽﾀﾏｲｽﾞ実施状態ﾌﾗｸﾞ（ﾒｰﾀ）
";
CM_ SG_ 922 MET39A_7_6_MFD_SPEC "MFD判別ﾌﾗｸﾞ
";
CM_ SG_ 922 MET39A_7_7_ICY_ROAD_SURFACE "路面凍結警報状態
";
CM_ SG_ 922 MET39A_6_4_STATUS_TRIP_A_B "TRIP表示状態(A or B)
";
CM_ SG_ 922 MET39A_5_2_AVE_FUEL_ECONOMY "平均燃費
";
CM_ SG_ 922 MET39A_4_0_INSTANTANEOUS_FUEL "瞬間燃費
";
CM_ SG_ 922 MET39A_3_1_STATUS_FUEL_LAMP "燃料残量警告灯状態
";
CM_ SG_ 922 MET39A_3_3_TRANSIT_TIME "運転経過時間
";
CM_ SG_ 922 MET39A_2_0_AVE_VEHICLE_SPEED "平均車速表示
";
CM_ SG_ 922 MET39A_1_0_MSG_COUNTER "ﾒｯｾｰｼﾞｶｳﾝﾀ
";
CM_ SG_ 922 MET39A_1_4_SET_UNIT_OF_FUEL "燃費単位設定
";
CM_ SG_ 922 MET39A_1_6_WELCOME_TRIG "ｳｪﾙｶﾑ演出開始ﾄﾘｶﾞ
";
CM_ SG_ 922 MET39A_1_7_METER_DISPLAY_TYPE "ﾒｰﾀ液晶ﾀｲﾌﾟ
";
CM_ SG_ 922 MET39A_0_0_CHECK_SUM "ﾁｪｯｸｻﾑ
";
CM_ SG_ 915 MET393_7_0_REQ_CHG_CSTM_EYE "ｱｲｻｲﾄｶｽﾀﾏｲｽﾞ要求変更
";
CM_ SG_ 915 MET393_7_1_REQ_RESET_CSTM_EYE "ｱｲｻｲﾄｶｽﾀﾏｲｽﾞﾘｾｯﾄ要求
";
CM_ SG_ 915 MET393_7_2_CSTM_ALK "ｱｲｻｲﾄｶｽﾀﾏｲｽﾞ変更設定(車線中央維持)
";
CM_ SG_ 915 MET393_7_3_CSTM_HBA "ｱｲｻｲﾄｶｽﾀﾏｲｽﾞ変更設定値(HBA)
";
CM_ SG_ 915 MET393_7_4_CSTM_MIS_AT_BACK "ｱｲｻｲﾄｶｽﾀﾏｲｽﾞ変更設定(AT誤後進抑制制御)
";
CM_ SG_ 915 MET393_7_6_CSTM_ACC_CONT "ｱｲｻｲﾄｶｽﾀﾏｲｽﾞ変更設定(ACC加速特性)
";
CM_ SG_ 915 MET393_6_0_R_DIFF_TEMP "R.DIFF油温ｾﾝｻ
";
CM_ SG_ 915 MET393_5_2_WARN_R_DIFF_TEMP "R.DIFF油温警告灯
";
CM_ SG_ 915 MET393_5_4_ADAPTIVECC_NOALIVE "追従ｸﾙｺﾝ未着判定ﾌﾗｸﾞ
";
CM_ SG_ 915 MET393_5_5_DUAL_RANGE_LO "ﾃﾞｭｱﾙﾚﾝｼﾞLo
";
CM_ SG_ 915 MET393_5_6_CSTM_SPD_LIMITER "ｱｲｻｲﾄｶｽﾀﾏｲｽﾞ変更設定(SAS)
";
CM_ SG_ 915 MET393_5_7_CSTM_LANE_CONT "ｱｲｻｲﾄｶｽﾀﾏｲｽﾞ変更設定(通行車線)
";
CM_ SG_ 915 MET393_4_0_FUEL_LEVEL_RESIST "燃料ﾚﾍﾞﾙｾﾝｻ抵抗値
";
CM_ SG_ 915 MET393_3_5_SI_DRIVE_SW "SI-DRIVE SW情報
";
CM_ SG_ 915 MET393_2_0_OUTTEMP_FOR_DIAG "診断用外気温
";
CM_ SG_ 915 MET393_1_0_MSG_COUNTER "ﾒｯｾｰｼﾞｶｳﾝﾀ
";
CM_ SG_ 915 MET393_1_4_CSTM_IND_BLUE "ｱｲｻｲﾄﾓﾆﾀｰ変更設定青色ｲﾝｼﾞｹｰﾀ
";
CM_ SG_ 915 MET393_1_5_CSTM_AES_CONT "ｱｲｻｲﾄｶｽﾀﾏｲｽﾞ変更設定(AES)
";
CM_ SG_ 915 MET393_1_6_FLG_PEDESTRIAN_AIRBAG "歩行者保護A/B有無ﾌﾗｸﾞ
";
CM_ SG_ 915 MET393_0_0_CHECK_SUM "ﾁｪｯｸｻﾑ
";
CM_ SG_ 912 MET390_7_0_VDC_ON_OFF "VDC SW情報
";
CM_ SG_ 912 MET390_7_2_RR_DOOR_RECORD_L "後席ﾄﾞｱ開履歴送信（左）
";
CM_ SG_ 912 MET390_7_3_RR_DOOR_RECORD_R "後席ﾄﾞｱ開履歴送信（右）
";
CM_ SG_ 912 MET390_7_4_REQ_CHG_CSTM_PSM "PSMｶｽﾀﾏｲｽﾞ要求変更
";
CM_ SG_ 912 MET390_7_5_REQ_RESET_CSTM_PSM "PSM　ｶｽﾀﾏｲｽﾞﾘｾｯﾄ要求
";
CM_ SG_ 912 MET390_7_6_CSTM_MIR_AFOLD_CONT "ﾄﾞｱﾐﾗｰｶｽﾀﾏｲｽﾞ変更設定(ｵｰﾄ電動格納ﾐﾗｰ)
";
CM_ SG_ 912 MET390_7_7_CSTM_MIR_RTILT_CONT "ﾄﾞｱﾐﾗｰｶｽﾀﾏｲｽﾞ変更設定(ﾘﾊﾞｰｽ連動ﾐﾗｰ)
";
CM_ SG_ 912 MET390_6_0_SEATBELT_DRVR "ｼｰﾄﾍﾞﾙﾄﾊﾞｯｸﾙSW　D席
";
CM_ SG_ 912 MET390_6_1_SEATBELT_PASS "ｼｰﾄﾍﾞﾙﾄﾊﾞｯｸﾙSW　P席
";
CM_ SG_ 912 MET390_6_2_TURN_SIG_LEFT "ﾀｰﾝ左出力信号
";
CM_ SG_ 912 MET390_6_3_TURN_SIG_RIGHT "ﾀｰﾝ右出力信号
";
CM_ SG_ 912 MET390_6_4_BRIGHT_SW "ﾌﾞﾗｲﾄ信号
";
CM_ SG_ 912 MET390_6_5_FAIL_UART_WA_BOX "WA-BOX UART通信異常
";
CM_ SG_ 912 MET390_6_6_ISS_OFF_SW "ISS OFFｽｲｯﾁ状態
";
CM_ SG_ 912 MET390_6_7_FLG_DMS "DMS車両装備情報
";
CM_ SG_ 912 MET390_5_0_ILL_BRIGHTNESS "ｲﾙﾐ輝度値
";
CM_ SG_ 912 MET390_4_0_OUTTEMP_FOR_IND "表示用外気温
";
CM_ SG_ 912 MET390_3_0_UNIT_SPEED_TRIP "速度計/距離計表示単位
";
CM_ SG_ 912 MET390_3_1_FLG_EYESIGHT "EyeSightﾌﾗｸﾞ
";
CM_ SG_ 912 MET390_3_2_FLG_ISS "ISSﾌﾗｸﾞ
";
CM_ SG_ 912 MET390_3_3_FLG_HEV "HEVﾌﾗｸﾞ
";
CM_ SG_ 912 MET390_3_4_FLG_IMB "IMﾌﾗｸﾞ
";
CM_ SG_ 912 MET390_3_5_TIRE_SIZE "ﾀｲﾔ径情報
";
CM_ SG_ 912 MET390_3_6_FLG_XMODE "Xモード車両装備情報
";
CM_ SG_ 912 MET390_2_0_VEHICLE_SERIES "車型情報
";
CM_ SG_ 912 MET390_2_3_DESTINATION "仕向地情報
";
CM_ SG_ 912 MET390_2_7_PASS_DOOR_RECORD "助手席ﾄﾞｱ開履歴送信
";
CM_ SG_ 912 MET390_1_0_MSG_COUNTER "ﾒｯｾｰｼﾞｶｳﾝﾀ
";
CM_ SG_ 912 MET390_1_4_WAKE_UP_FRAME "ｳｪｲｸｱｯﾌﾟﾌﾚｰﾑ識別ﾌﾗｸﾞ
";
CM_ SG_ 912 MET390_1_5_REQ_COMM_CONT "通信継続要求ﾌﾗｸﾞ
";
CM_ SG_ 912 MET390_1_6_DMS_ID_SET "DMS ID設定完了ﾌﾗｸﾞ
";
CM_ SG_ 912 MET390_1_7_FAIL_EEPROM "EEPROMﾌｪｰﾙ
";
CM_ SG_ 912 MET390_0_0_CHECK_SUM "ﾁｪｯｸｻﾑ
";
BA_DEF_ SG_  "Fhi_SignalComment" STRING ;
BA_DEF_ SG_  "GenSigInactiveValue" INT 0 10000;
BA_DEF_ SG_  "GenSigStartValue" FLOAT 0 100000000000;
BA_DEF_ SG_  "GenSigSendType" ENUM  "Cyclic","OnWrite","OnWriteWithRepetition","OnChange","OnChangeWithRepetition","IfActive","IfActiveWithRepetition","NoSigSendType";
BA_DEF_ BO_  "MsgRoutingId" STRING ;
BA_DEF_ BO_  "DiagResponse" ENUM  "No","Yes";
BA_DEF_ BO_  "DiagRequest" ENUM  "No","Yes";
BA_DEF_ BO_  "DiagState" ENUM  "No","Yes";
BA_DEF_ BO_  "GenMsgILSupport" ENUM  "No","Yes";
BA_DEF_ BO_  "GenMsgNrOfRepetition" INT 0 999999;
BA_DEF_ BO_  "GenMsgDelayTime" INT 0 1000;
BA_DEF_ BO_  "GenMsgCycleTimeFast" INT 0 10000;
BA_DEF_ BO_  "GenMsgCycleTime" INT 0 10000;
BA_DEF_ BO_  "GenMsgSendType" ENUM  "Cyclic","NotUsed","NotUsed","NotUsed","NotUsed","Cyclic","NotUsed","IfActive","NoMsgSendType";
BA_DEF_ BO_  "CANFD_BRS" ENUM  "0","1";
BA_DEF_ BO_  "VFrameFormat" ENUM  "StandardCAN","ExtendedCAN","reserved","reserved","reserved","reserved","reserved","reserved","reserved","reserved","reserved","reserved","reserved","reserved","StandardCAN_FD","ExtendedCAN_FD";
BA_DEF_DEF_  "Fhi_SignalComment" "";
BA_DEF_DEF_  "GenSigInactiveValue" 0;
BA_DEF_DEF_  "GenSigStartValue" 0;
BA_DEF_DEF_  "GenSigSendType" "NoSigSendType";
BA_DEF_DEF_  "MsgRoutingId" "";
BA_DEF_DEF_  "DiagResponse" "No";
BA_DEF_DEF_  "DiagRequest" "No";
BA_DEF_DEF_  "DiagState" "No";
BA_DEF_DEF_  "GenMsgILSupport" "Yes";
BA_DEF_DEF_  "GenMsgNrOfRepetition" 0;
BA_DEF_DEF_  "GenMsgDelayTime" 0;
BA_DEF_DEF_  "GenMsgCycleTimeFast" 0;
BA_DEF_DEF_  "GenMsgCycleTime" 0;
BA_DEF_DEF_  "GenMsgSendType" "Cyclic";
BA_DEF_DEF_  "CANFD_BRS" "1";
BA_DEF_DEF_  "VFrameFormat" "StandardCAN";
BA_ "GenMsgCycleTime" BO_ 1546 1000;
BA_ "MsgRoutingId" BO_ 1546 "223 ";
BA_ "GenMsgILSupport" BO_ 1546 0;
BA_ "VFrameFormat" BO_ 1546 14;
BA_ "GenMsgCycleTime" BO_ 1680 1000;
BA_ "MsgRoutingId" BO_ 1680 "222 ";
BA_ "GenMsgILSupport" BO_ 1680 0;
BA_ "VFrameFormat" BO_ 1680 14;
BA_ "GenMsgCycleTime" BO_ 862 100;
BA_ "MsgRoutingId" BO_ 862 "221 ";
BA_ "GenMsgILSupport" BO_ 862 0;
BA_ "VFrameFormat" BO_ 862 14;
BA_ "GenMsgCycleTime" BO_ 861 100;
BA_ "MsgRoutingId" BO_ 861 "220 ";
BA_ "GenMsgILSupport" BO_ 861 0;
BA_ "VFrameFormat" BO_ 861 14;
BA_ "GenMsgCycleTime" BO_ 1685 1000;
BA_ "MsgRoutingId" BO_ 1685 "219 ";
BA_ "GenMsgILSupport" BO_ 1685 0;
BA_ "VFrameFormat" BO_ 1685 14;
BA_ "GenMsgCycleTime" BO_ 1539 1000;
BA_ "GenMsgDelayTime" BO_ 1539 10;
BA_ "GenMsgNrOfRepetition" BO_ 1539 1;
BA_ "MsgRoutingId" BO_ 1539 "218 ";
BA_ "GenMsgILSupport" BO_ 1539 0;
BA_ "VFrameFormat" BO_ 1539 14;
BA_ "GenMsgCycleTime" BO_ 1538 1000;
BA_ "GenMsgDelayTime" BO_ 1538 10;
BA_ "GenMsgNrOfRepetition" BO_ 1538 1;
BA_ "MsgRoutingId" BO_ 1538 "217 ";
BA_ "GenMsgILSupport" BO_ 1538 0;
BA_ "VFrameFormat" BO_ 1538 14;
BA_ "GenMsgCycleTime" BO_ 541 50;
BA_ "MsgRoutingId" BO_ 541 "216 ";
BA_ "GenMsgILSupport" BO_ 541 0;
BA_ "VFrameFormat" BO_ 541 14;
BA_ "GenMsgCycleTime" BO_ 269 20;
BA_ "MsgRoutingId" BO_ 269 "215 ";
BA_ "GenMsgILSupport" BO_ 269 0;
BA_ "VFrameFormat" BO_ 269 14;
BA_ "GenMsgCycleTime" BO_ 495 30;
BA_ "MsgRoutingId" BO_ 495 "213 ";
BA_ "GenMsgILSupport" BO_ 495 0;
BA_ "VFrameFormat" BO_ 495 14;
BA_ "GenMsgCycleTime" BO_ 494 30;
BA_ "MsgRoutingId" BO_ 494 "212 ";
BA_ "GenMsgILSupport" BO_ 494 0;
BA_ "VFrameFormat" BO_ 494 14;
BA_ "GenMsgCycleTime" BO_ 267 20;
BA_ "MsgRoutingId" BO_ 267 "211 ";
BA_ "GenMsgILSupport" BO_ 267 0;
BA_ "VFrameFormat" BO_ 267 14;
BA_ "GenMsgCycleTime" BO_ 117 10;
BA_ "MsgRoutingId" BO_ 117 "210 ";
BA_ "GenMsgILSupport" BO_ 117 0;
BA_ "VFrameFormat" BO_ 117 14;
BA_ "GenMsgCycleTime" BO_ 116 10;
BA_ "MsgRoutingId" BO_ 116 "209 ";
BA_ "GenMsgILSupport" BO_ 116 0;
BA_ "VFrameFormat" BO_ 116 14;
BA_ "GenMsgSendType" BO_ 2564481473 8;
BA_ "GenMsgNrOfRepetition" BO_ 2564481473 1;
BA_ "DiagResponse" BO_ 2564481473 1;
BA_ "GenMsgILSupport" BO_ 2564481473 0;
BA_ "VFrameFormat" BO_ 2564481473 15;
BA_ "GenMsgSendType" BO_ 2564473313 8;
BA_ "GenMsgNrOfRepetition" BO_ 2564473313 1;
BA_ "DiagRequest" BO_ 2564473313 1;
BA_ "GenMsgILSupport" BO_ 2564473313 0;
BA_ "VFrameFormat" BO_ 2564473313 15;
BA_ "VFrameFormat" BO_ 2564481217 1;
BA_ "GenMsgSendType" BO_ 2564481217 8;
BA_ "GenMsgNrOfRepetition" BO_ 2564481217 1;
BA_ "DiagResponse" BO_ 2564481217 1;
BA_ "GenMsgILSupport" BO_ 2564481217 0;
BA_ "MsgRoutingId" BO_ 2564481217 "204 ";
BA_ "VFrameFormat" BO_ 2564473312 1;
BA_ "GenMsgSendType" BO_ 2564473312 8;
BA_ "GenMsgNrOfRepetition" BO_ 2564473312 1;
BA_ "DiagRequest" BO_ 2564473312 1;
BA_ "GenMsgILSupport" BO_ 2564473312 0;
BA_ "MsgRoutingId" BO_ 2564473312 "203 ";
BA_ "VFrameFormat" BO_ 2564468769 1;
BA_ "GenMsgSendType" BO_ 2564468769 8;
BA_ "GenMsgNrOfRepetition" BO_ 2564468769 1;
BA_ "DiagResponse" BO_ 2564468769 1;
BA_ "GenMsgILSupport" BO_ 2564468769 0;
BA_ "MsgRoutingId" BO_ 2564468769 "160 ";
BA_ "VFrameFormat" BO_ 2564432304 1;
BA_ "GenMsgSendType" BO_ 2564432304 8;
BA_ "GenMsgNrOfRepetition" BO_ 2564432304 1;
BA_ "DiagRequest" BO_ 2564432304 1;
BA_ "GenMsgILSupport" BO_ 2564432304 0;
BA_ "MsgRoutingId" BO_ 2564432304 "159 ";
BA_ "GenMsgSendType" BO_ 2564481200 8;
BA_ "GenMsgNrOfRepetition" BO_ 2564481200 1;
BA_ "DiagResponse" BO_ 2564481200 1;
BA_ "GenMsgILSupport" BO_ 2564481200 0;
BA_ "MsgRoutingId" BO_ 2564481200 "158 ";
BA_ "VFrameFormat" BO_ 2564481200 15;
BA_ "GenMsgSendType" BO_ 2564468960 8;
BA_ "GenMsgNrOfRepetition" BO_ 2564468960 1;
BA_ "DiagRequest" BO_ 2564468960 1;
BA_ "GenMsgILSupport" BO_ 2564468960 0;
BA_ "MsgRoutingId" BO_ 2564468960 "157 ";
BA_ "VFrameFormat" BO_ 2564468960 15;
BA_ "VFrameFormat" BO_ 2564550625 1;
BA_ "GenMsgSendType" BO_ 2564550625 8;
BA_ "GenMsgNrOfRepetition" BO_ 2564550625 1;
BA_ "DiagState" BO_ 2564550625 1;
BA_ "GenMsgILSupport" BO_ 2564550625 0;
BA_ "VFrameFormat" BO_ 2564550624 1;
BA_ "GenMsgSendType" BO_ 2564550624 8;
BA_ "GenMsgNrOfRepetition" BO_ 2564550624 1;
BA_ "DiagState" BO_ 2564550624 1;
BA_ "GenMsgILSupport" BO_ 2564550624 0;
BA_ "MsgRoutingId" BO_ 2564550624 "125 ";
BA_ "GenMsgSendType" BO_ 1832 8;
BA_ "GenMsgNrOfRepetition" BO_ 1832 1;
BA_ "DiagState" BO_ 1832 1;
BA_ "GenMsgILSupport" BO_ 1832 0;
BA_ "MsgRoutingId" BO_ 1832 "124 ";
BA_ "GenMsgSendType" BO_ 2564481456 8;
BA_ "GenMsgNrOfRepetition" BO_ 2564481456 1;
BA_ "DiagResponse" BO_ 2564481456 1;
BA_ "GenMsgILSupport" BO_ 2564481456 0;
BA_ "VFrameFormat" BO_ 2564481456 15;
BA_ "GenMsgSendType" BO_ 2564468961 8;
BA_ "GenMsgNrOfRepetition" BO_ 2564468961 1;
BA_ "DiagRequest" BO_ 2564468961 1;
BA_ "GenMsgILSupport" BO_ 2564468961 0;
BA_ "VFrameFormat" BO_ 2564468961 15;
BA_ "GenMsgSendType" BO_ 2564481573 8;
BA_ "GenMsgNrOfRepetition" BO_ 2564481573 1;
BA_ "DiagResponse" BO_ 2564481573 1;
BA_ "GenMsgILSupport" BO_ 2564481573 0;
BA_ "VFrameFormat" BO_ 2564481573 15;
BA_ "GenMsgSendType" BO_ 2564433378 8;
BA_ "GenMsgNrOfRepetition" BO_ 2564433378 1;
BA_ "DiagRequest" BO_ 2564433378 1;
BA_ "GenMsgILSupport" BO_ 2564433378 0;
BA_ "VFrameFormat" BO_ 2564433378 15;
BA_ "GenMsgSendType" BO_ 1892 8;
BA_ "GenMsgNrOfRepetition" BO_ 1892 1;
BA_ "DiagRequest" BO_ 1892 1;
BA_ "GenMsgILSupport" BO_ 1892 0;
BA_ "MsgRoutingId" BO_ 1892 "120 ";
BA_ "GenMsgSendType" BO_ 1848 8;
BA_ "GenMsgNrOfRepetition" BO_ 1848 1;
BA_ "DiagResponse" BO_ 1848 1;
BA_ "GenMsgILSupport" BO_ 1848 0;
BA_ "MsgRoutingId" BO_ 1848 "119 ";
BA_ "GenMsgSendType" BO_ 1840 8;
BA_ "GenMsgNrOfRepetition" BO_ 1840 1;
BA_ "DiagRequest" BO_ 1840 1;
BA_ "GenMsgILSupport" BO_ 1840 0;
BA_ "MsgRoutingId" BO_ 1840 "118 ";
BA_ "GenMsgSendType" BO_ 1807 8;
BA_ "GenMsgNrOfRepetition" BO_ 1807 1;
BA_ "DiagResponse" BO_ 1807 1;
BA_ "GenMsgILSupport" BO_ 1807 0;
BA_ "GenMsgCycleTime" BO_ 1774 1000;
BA_ "VFrameFormat" BO_ 1774 14;
BA_ "GenMsgCycleTime" BO_ 1773 1000;
BA_ "VFrameFormat" BO_ 1773 14;
BA_ "GenMsgCycleTime" BO_ 1772 1000;
BA_ "VFrameFormat" BO_ 1772 14;
BA_ "GenMsgCycleTime" BO_ 996 500;
BA_ "GenMsgDelayTime" BO_ 996 10;
BA_ "GenMsgCycleTimeFast" BO_ 996 20;
BA_ "GenMsgNrOfRepetition" BO_ 996 5;
BA_ "VFrameFormat" BO_ 996 14;
BA_ "GenMsgCycleTime" BO_ 1280 1000;
BA_ "VFrameFormat" BO_ 1280 14;
BA_ "GenMsgCycleTime" BO_ 1633 1000;
BA_ "VFrameFormat" BO_ 1633 14;
BA_ "GenMsgCycleTime" BO_ 1632 500;
BA_ "VFrameFormat" BO_ 1632 14;
BA_ "GenMsgCycleTime" BO_ 1752 1200;
BA_ "GenMsgCycleTimeFast" BO_ 1752 100;
BA_ "GenMsgNrOfRepetition" BO_ 1752 1;
BA_ "MsgRoutingId" BO_ 1752 "117 ";
BA_ "VFrameFormat" BO_ 1752 14;
BA_ "GenMsgCycleTime" BO_ 1744 1200;
BA_ "GenMsgCycleTimeFast" BO_ 1744 100;
BA_ "GenMsgNrOfRepetition" BO_ 1744 1;
BA_ "VFrameFormat" BO_ 1744 14;
BA_ "GenMsgCycleTime" BO_ 1743 1200;
BA_ "GenMsgCycleTimeFast" BO_ 1743 100;
BA_ "GenMsgNrOfRepetition" BO_ 1743 1;
BA_ "MsgRoutingId" BO_ 1743 "116 ";
BA_ "VFrameFormat" BO_ 1743 14;
BA_ "GenMsgDelayTime" BO_ 1630 10;
BA_ "GenMsgSendType" BO_ 1630 8;
BA_ "GenMsgCycleTimeFast" BO_ 1630 20;
BA_ "GenMsgNrOfRepetition" BO_ 1630 1;
BA_ "MsgRoutingId" BO_ 1630 "115 ";
BA_ "VFrameFormat" BO_ 1630 14;
BA_ "GenMsgCycleTime" BO_ 1301 1000;
BA_ "VFrameFormat" BO_ 1301 14;
BA_ "GenMsgCycleTime" BO_ 1749 1000;
BA_ "GenMsgDelayTime" BO_ 1749 10;
BA_ "GenMsgCycleTimeFast" BO_ 1749 20;
BA_ "GenMsgNrOfRepetition" BO_ 1749 10;
BA_ "VFrameFormat" BO_ 1749 14;
BA_ "GenMsgCycleTime" BO_ 1753 1200;
BA_ "GenMsgDelayTime" BO_ 1753 10;
BA_ "GenMsgNrOfRepetition" BO_ 1753 1;
BA_ "VFrameFormat" BO_ 1753 14;
BA_ "GenMsgCycleTime" BO_ 723 50;
BA_ "GenMsgDelayTime" BO_ 723 10;
BA_ "GenMsgCycleTimeFast" BO_ 723 10;
BA_ "GenMsgNrOfRepetition" BO_ 723 3;
BA_ "VFrameFormat" BO_ 723 14;
BA_ "GenMsgCycleTime" BO_ 1748 1000;
BA_ "GenMsgDelayTime" BO_ 1748 10;
BA_ "GenMsgNrOfRepetition" BO_ 1748 1;
BA_ "VFrameFormat" BO_ 1748 14;
BA_ "GenMsgSendType" BO_ 1736 8;
BA_ "GenMsgNrOfRepetition" BO_ 1736 1;
BA_ "VFrameFormat" BO_ 1736 14;
BA_ "GenMsgCycleTime" BO_ 1701 1200;
BA_ "GenMsgDelayTime" BO_ 1701 10;
BA_ "GenMsgCycleTimeFast" BO_ 1701 120;
BA_ "GenMsgNrOfRepetition" BO_ 1701 4;
BA_ "VFrameFormat" BO_ 1701 14;
BA_ "GenMsgSendType" BO_ 1699 8;
BA_ "VFrameFormat" BO_ 1699 14;
BA_ "GenMsgDelayTime" BO_ 1739 10;
BA_ "GenMsgSendType" BO_ 1739 8;
BA_ "GenMsgCycleTimeFast" BO_ 1739 20;
BA_ "GenMsgNrOfRepetition" BO_ 1739 1;
BA_ "MsgRoutingId" BO_ 1739 "114 ";
BA_ "VFrameFormat" BO_ 1739 14;
BA_ "GenMsgSendType" BO_ 1155 8;
BA_ "GenMsgCycleTimeFast" BO_ 1155 100;
BA_ "GenMsgNrOfRepetition" BO_ 1155 1;
BA_ "VFrameFormat" BO_ 1155 14;
BA_ "GenMsgSendType" BO_ 1154 8;
BA_ "GenMsgCycleTimeFast" BO_ 1154 100;
BA_ "GenMsgNrOfRepetition" BO_ 1154 1;
BA_ "VFrameFormat" BO_ 1154 14;
BA_ "GenMsgCycleTime" BO_ 1113 100;
BA_ "MsgRoutingId" BO_ 1113 "113 ";
BA_ "VFrameFormat" BO_ 1113 14;
BA_ "GenMsgCycleTime" BO_ 1107 100;
BA_ "MsgRoutingId" BO_ 1107 "112 ";
BA_ "VFrameFormat" BO_ 1107 14;
BA_ "GenMsgCycleTime" BO_ 1705 1000;
BA_ "GenMsgDelayTime" BO_ 1705 10;
BA_ "GenMsgCycleTimeFast" BO_ 1705 200;
BA_ "GenMsgNrOfRepetition" BO_ 1705 5;
BA_ "MsgRoutingId" BO_ 1705 "111 ";
BA_ "GenMsgILSupport" BO_ 1705 0;
BA_ "VFrameFormat" BO_ 1705 14;
BA_ "GenMsgCycleTime" BO_ 930 100;
BA_ "GenMsgDelayTime" BO_ 930 10;
BA_ "GenMsgCycleTimeFast" BO_ 930 50;
BA_ "GenMsgNrOfRepetition" BO_ 930 4;
BA_ "MsgRoutingId" BO_ 930 "110 ";
BA_ "GenMsgILSupport" BO_ 930 0;
BA_ "VFrameFormat" BO_ 930 14;
BA_ "GenMsgCycleTime" BO_ 1677 1200;
BA_ "GenMsgDelayTime" BO_ 1677 10;
BA_ "GenMsgCycleTimeFast" BO_ 1677 200;
BA_ "GenMsgNrOfRepetition" BO_ 1677 5;
BA_ "MsgRoutingId" BO_ 1677 "109 ";
BA_ "GenMsgILSupport" BO_ 1677 0;
BA_ "VFrameFormat" BO_ 1677 14;
BA_ "GenMsgCycleTime" BO_ 1676 1200;
BA_ "GenMsgDelayTime" BO_ 1676 10;
BA_ "GenMsgCycleTimeFast" BO_ 1676 20;
BA_ "MsgRoutingId" BO_ 1676 "108 ";
BA_ "GenMsgILSupport" BO_ 1676 0;
BA_ "VFrameFormat" BO_ 1676 14;
BA_ "GenMsgCycleTime" BO_ 922 200;
BA_ "GenMsgDelayTime" BO_ 922 10;
BA_ "GenMsgCycleTimeFast" BO_ 922 20;
BA_ "GenMsgNrOfRepetition" BO_ 922 5;
BA_ "MsgRoutingId" BO_ 922 "107 ";
BA_ "GenMsgILSupport" BO_ 922 0;
BA_ "VFrameFormat" BO_ 922 14;
BA_ "GenMsgCycleTime" BO_ 915 100;
BA_ "GenMsgDelayTime" BO_ 915 10;
BA_ "GenMsgCycleTimeFast" BO_ 915 20;
BA_ "GenMsgNrOfRepetition" BO_ 915 2;
BA_ "MsgRoutingId" BO_ 915 "106 ";
BA_ "GenMsgILSupport" BO_ 915 0;
BA_ "VFrameFormat" BO_ 915 14;
BA_ "GenMsgCycleTime" BO_ 912 100;
BA_ "GenMsgDelayTime" BO_ 912 10;
BA_ "GenMsgCycleTimeFast" BO_ 912 50;
BA_ "GenMsgNrOfRepetition" BO_ 912 4;
BA_ "MsgRoutingId" BO_ 912 "105 ";
BA_ "GenMsgILSupport" BO_ 912 0;
BA_ "VFrameFormat" BO_ 912 14;
BA_ "GenSigStartValue" SG_ 1680 BAT690_3_0_CHG_REMTI_GRF 3;
BA_ "GenSigStartValue" SG_ 861 BAT35D_28_5_HVB_ACTCHGWIN 65534;
BA_ "GenSigStartValue" SG_ 861 BAT35D_27_2_HVB_TEMPAVE 100;
BA_ "GenSigStartValue" SG_ 861 BAT35D_18_2_HVB_DISPSOHODO 2097150;
BA_ "GenSigStartValue" SG_ 861 BAT35D_17_0_HVB_DISPSOH_PERC 254;
BA_ "GenSigStartValue" SG_ 861 BAT35D_15_7_HVB_DISPSOH_R_AH 510;
BA_ "GenSigStartValue" SG_ 861 BAT35D_14_6_HVB_DISPSOH_AH 510;
BA_ "GenSigStartValue" SG_ 861 BAT35D_13_0_CHG_REMTI_UPS_ACN 16382;
BA_ "GenSigStartValue" SG_ 861 BAT35D_11_2_CHG_REMTI_UPS 16382;
BA_ "GenSigStartValue" SG_ 861 BAT35D_3_0_HVB_DISPSOC_PERC 254;
BA_ "GenSigStartValue" SG_ 1539 BEV603_13_0_BATTEMP_DISP 254;
BA_ "GenSigStartValue" SG_ 1539 BEV603_12_0_RR_MTRTEMP_DISP 254;
BA_ "GenSigStartValue" SG_ 1539 BEV603_11_0_FR_MTRTEMP_DISP 254;
BA_ "GenSigSendType" SG_ 1539 BEV603_10_2_TRQFLCREQ 3;
BA_ "GenSigSendType" SG_ 1539 BEV603_10_4_TRQFLCNG 3;
BA_ "GenSigSendType" SG_ 1539 BEV603_10_5_TRQFLCSTATE 3;
BA_ "GenSigSendType" SG_ 1539 BEV603_10_6_TRQFLCDISP 3;
BA_ "GenSigSendType" SG_ 1539 BEV603_10_7_TRQVIBREQ 3;
BA_ "GenSigSendType" SG_ 1539 BEV603_9_4_PADL_INHBUZ 3;
BA_ "GenSigSendType" SG_ 1539 BEV603_9_5_PADL_LVL 3;
BA_ "GenSigSendType" SG_ 1539 BEV603_8_1_XMODE_INH 3;
BA_ "GenSigSendType" SG_ 1539 BEV603_8_2_SIDRIVE_INH 3;
BA_ "GenSigSendType" SG_ 1539 BEV603_8_3_SIDRIVE_INHBUZ 3;
BA_ "GenSigSendType" SG_ 1539 BEV603_8_4_ARBIT_SIDR 3;
BA_ "GenSigSendType" SG_ 1539 BEV603_8_5_SIDRIVE_DISP 3;
BA_ "GenSigSendType" SG_ 1539 BEV603_7_4_ADPDEC_INHBUZ 3;
BA_ "GenSigSendType" SG_ 1539 BEV603_7_5_ADPDEC_INH_ALL 3;
BA_ "GenSigSendType" SG_ 1539 BEV603_7_6_ADPDEC_DISP 3;
BA_ "GenSigSendType" SG_ 1539 BEV603_7_7_ADPDEC_EQ 3;
BA_ "GenSigSendType" SG_ 1539 BEV603_6_0_AWD_MODE 3;
BA_ "GenSigSendType" SG_ 1539 BEV603_6_3_AWD_STS_DISP 3;
BA_ "GenSigSendType" SG_ 1539 BEV603_6_4_DECSEL_INHMSG 3;
BA_ "GenSigSendType" SG_ 1539 BEV603_6_7_AWD_MODE_EQUIP 3;
BA_ "GenSigSendType" SG_ 1539 BEV603_5_0_PDLBZR 3;
BA_ "GenSigSendType" SG_ 1539 BEV603_5_1_SFTDN_PERM 3;
BA_ "GenSigSendType" SG_ 1539 BEV603_5_2_SFTUP_PERM 3;
BA_ "GenSigSendType" SG_ 1539 BEV603_5_3_GEARSFT_MODE 3;
BA_ "GenSigSendType" SG_ 1539 BEV603_5_4_DECSEL_INH_INDI 3;
BA_ "GenSigSendType" SG_ 1539 BEV603_5_5_DECSEL_INH_B 3;
BA_ "GenSigSendType" SG_ 1539 BEV603_5_6_DECSEL_INH_D 3;
BA_ "GenSigSendType" SG_ 1539 BEV603_5_7_DECSEL_INH_ALL 3;
BA_ "GenSigSendType" SG_ 1539 BEV603_4_1_DECSEL_DISP_INDI 3;
BA_ "GenSigSendType" SG_ 1539 BEV603_4_2_DECSEL_DISP_B 3;
BA_ "GenSigSendType" SG_ 1539 BEV603_4_4_DECLV_DECSEL 3;
BA_ "GenSigSendType" SG_ 1539 BEV603_4_6_DECSEL_DISP_ALL 3;
BA_ "GenSigSendType" SG_ 1539 BEV603_3_0_GEARLV_MANU 3;
BA_ "GenSigSendType" SG_ 1539 BEV603_3_1_DECSEL_EQ_INDI 3;
BA_ "GenSigSendType" SG_ 1539 BEV603_3_2_DECSEL_EQ_B 3;
BA_ "GenSigSendType" SG_ 1539 BEV603_3_4_GEARLV_AUTO 3;
BA_ "GenSigSendType" SG_ 1539 BEV603_3_6_DECSEL_EQ_ALL 3;
BA_ "GenSigSendType" SG_ 1538 BEV602_18_0_V2L_OUTLET_VOLTAGE 3;
BA_ "GenSigSendType" SG_ 1538 BEV602_16_0_LV_SYS_STATUS 3;
BA_ "GenSigSendType" SG_ 1538 BEV602_15_0_DCM_REMOTE_INFO 3;
BA_ "GenSigSendType" SG_ 1538 BEV602_14_4_DISPMSG_SC_SGLPH 3;
BA_ "GenSigSendType" SG_ 1538 BEV602_14_2_CERT2_MODE 3;
BA_ "GenSigStartValue" SG_ 1538 BEV602_14_0_SW_PWR_SPL 2;
BA_ "GenSigSendType" SG_ 1538 BEV602_14_0_SW_PWR_SPL 3;
BA_ "GenSigSendType" SG_ 1538 BEV602_13_0_TCSLMP_REQ 3;
BA_ "GenSigSendType" SG_ 1538 BEV602_13_1_AWDLMP_REQ 3;
BA_ "GenSigSendType" SG_ 1538 BEV602_13_3_AWDWRNMSG_REQ 3;
BA_ "GenSigSendType" SG_ 1538 BEV602_12_0_BOSLMP_REQ 3;
BA_ "GenSigSendType" SG_ 1538 BEV602_11_3_LVB_ABN 3;
BA_ "GenSigSendType" SG_ 1538 BEV602_11_6_CERT4_MODE 3;
BA_ "GenSigSendType" SG_ 1538 BEV602_11_7_CERT2_MODE 3;
BA_ "GenSigSendType" SG_ 1538 BEV602_10_0_FACT_CERT_MODE 3;
BA_ "GenSigSendType" SG_ 1538 BEV602_10_1_FACT_MODE 3;
BA_ "GenSigSendType" SG_ 1538 BEV602_10_2_EVBATLO_CAU 3;
BA_ "GenSigSendType" SG_ 1538 BEV602_10_5_PWRLMT_ID 3;
BA_ "GenSigSendType" SG_ 1538 BEV602_9_1_DCRCHK_DSP_REQ 3;
BA_ "GenSigSendType" SG_ 1538 BEV602_9_4_LVB_FNCLMT_MSG 3;
BA_ "GenSigSendType" SG_ 1538 BEV602_9_7_CHG_MSG 3;
BA_ "GenSigSendType" SG_ 1538 BEV602_8_0_LVB_ABN_DCDC 3;
BA_ "GenSigSendType" SG_ 1538 BEV602_8_4_LVB_ABN_LIB 3;
BA_ "GenSigSendType" SG_ 1538 BEV602_8_7_CHG_CAU 3;
BA_ "GenSigSendType" SG_ 1538 BEV602_7_0_V2L_STOP_MSG 3;
BA_ "GenSigStartValue" SG_ 1538 BEV602_6_0_V2L_SOC_LOWLMT 2000;
BA_ "GenSigSendType" SG_ 1538 BEV602_6_0_V2L_SOC_LOWLMT 3;
BA_ "GenSigSendType" SG_ 1538 BEV602_5_0_V2L_OUTSTS_2 3;
BA_ "GenSigSendType" SG_ 1538 BEV602_5_1_V2L_OUTSTS_1 3;
BA_ "GenSigSendType" SG_ 1538 BEV602_5_2_ACCHCAU 3;
BA_ "GenSigSendType" SG_ 1538 BEV602_5_3_EVIND 3;
BA_ "GenSigSendType" SG_ 1538 BEV602_4_0_BEV_OBD_CAU 3;
BA_ "GenSigSendType" SG_ 1538 BEV602_4_3_EV_CAU 3;
BA_ "GenSigSendType" SG_ 1538 BEV602_4_5_PIROFF_MSG 3;
BA_ "GenSigSendType" SG_ 1538 BEV602_3_0_DRVRDY 3;
BA_ "GenSigStartValue" SG_ 1538 BEV602_3_2_RANGE_POS 6;
BA_ "GenSigSendType" SG_ 1538 BEV602_3_2_RANGE_POS 3;
BA_ "GenSigStartValue" SG_ 269 BEV10D_12_0_V_RZRPM_DISP 255;
BA_ "GenSigStartValue" SG_ 269 BEV10D_3_0_LVB_SOC_LIB 255;
BA_ "GenSigStartValue" SG_ 116 BEV074_3_0_RANGE_POS 6;
BA_ "GenSigSendType" SG_ 2564481473 DCM18DAE1C1_DIAG_DATA_EXT7 2;
BA_ "GenSigSendType" SG_ 2564481473 DCM18DAE1C1_DIAG_DATA_EXT6 2;
BA_ "GenSigSendType" SG_ 2564481473 DCM18DAE1C1_DIAG_DATA_EXT5 2;
BA_ "GenSigSendType" SG_ 2564481473 DCM18DAE1C1_DIAG_DATA_EXT4 2;
BA_ "GenSigSendType" SG_ 2564481473 DCM18DAE1C1_DIAG_DATA_EXT3 2;
BA_ "GenSigSendType" SG_ 2564481473 DCM18DAE1C1_DIAG_DATA_EXT2 2;
BA_ "GenSigSendType" SG_ 2564481473 DCM18DAE1C1_DIAG_DATA_EXT1 2;
BA_ "GenSigSendType" SG_ 2564481473 DCM18DAE1C1_DIAG_DATA 2;
BA_ "GenSigSendType" SG_ 2564473313 CECU18DAC1E1_DIAG_DATA_EXT7 2;
BA_ "GenSigSendType" SG_ 2564473313 CECU18DAC1E1_DIAG_DATA_EXT6 2;
BA_ "GenSigSendType" SG_ 2564473313 CECU18DAC1E1_DIAG_DATA_EXT5 2;
BA_ "GenSigSendType" SG_ 2564473313 CECU18DAC1E1_DIAG_DATA_EXT4 2;
BA_ "GenSigSendType" SG_ 2564473313 CECU18DAC1E1_DIAG_DATA_EXT3 2;
BA_ "GenSigSendType" SG_ 2564473313 CECU18DAC1E1_DIAG_DATA_EXT2 2;
BA_ "GenSigSendType" SG_ 2564473313 CECU18DAC1E1_DIAG_DATA_EXT1 2;
BA_ "GenSigSendType" SG_ 2564473313 CECU18DAC1E1_DIAG_DATA 2;
BA_ "GenSigSendType" SG_ 2564481217 DCM18DAE0C1_DIAG_DATA 2;
BA_ "GenSigSendType" SG_ 2564473312 DNT18DAC1E0_DIAG_DATA 2;
BA_ "GenSigSendType" SG_ 2564468769 BIU18DAB021_DIAG_DATA 2;
BA_ "GenSigSendType" SG_ 2564432304 AVN18DA21B0_DIAG_DATA 2;
BA_ "GenSigSendType" SG_ 2564481200 AVN18DAE0B0_DIAG_DATA_EXT7 2;
BA_ "GenSigSendType" SG_ 2564481200 AVN18DAE0B0_DIAG_DATA_EXT6 2;
BA_ "GenSigSendType" SG_ 2564481200 AVN18DAE0B0_DIAG_DATA_EXT5 2;
BA_ "GenSigSendType" SG_ 2564481200 AVN18DAE0B0_DIAG_DATA_EXT4 2;
BA_ "GenSigSendType" SG_ 2564481200 AVN18DAE0B0_DIAG_DATA_EXT3 2;
BA_ "GenSigSendType" SG_ 2564481200 AVN18DAE0B0_DIAG_DATA_EXT2 2;
BA_ "GenSigSendType" SG_ 2564481200 AVN18DAE0B0_DIAG_DATA_EXT1 2;
BA_ "GenSigSendType" SG_ 2564481200 AVN18DAE0B0_DIAG_DATA 2;
BA_ "GenSigSendType" SG_ 2564468960 DNT18DAB0E0_DIAG_DATA_EXT7 2;
BA_ "GenSigSendType" SG_ 2564468960 DNT18DAB0E0_DIAG_DATA_EXT6 2;
BA_ "GenSigSendType" SG_ 2564468960 DNT18DAB0E0_DIAG_DATA_EXT5 2;
BA_ "GenSigSendType" SG_ 2564468960 DNT18DAB0E0_DIAG_DATA_EXT4 2;
BA_ "GenSigSendType" SG_ 2564468960 DNT18DAB0E0_DIAG_DATA_EXT3 2;
BA_ "GenSigSendType" SG_ 2564468960 DNT18DAB0E0_DIAG_DATA_EXT2 2;
BA_ "GenSigSendType" SG_ 2564468960 DNT18DAB0E0_DIAG_DATA_EXT1 2;
BA_ "GenSigSendType" SG_ 2564468960 DNT18DAB0E0_DIAG_DATA 2;
BA_ "GenSigSendType" SG_ 2564550625 CECU18DBEFE1_DIAG_DATA 2;
BA_ "GenSigSendType" SG_ 2564550624 DNT18DBEFE0_DIAG_DATA 2;
BA_ "GenSigSendType" SG_ 1832 DNT728_7_0_DIAG_DATA 2;
BA_ "GenSigSendType" SG_ 1832 DNT728_2_0_DIAG_N_PCI_OR_DATA 2;
BA_ "GenSigSendType" SG_ 1832 DNT728_1_0_DIAG_N_PCI_OR_DATA 2;
BA_ "GenSigSendType" SG_ 1832 DNT728_0_0_DIAG_N_PCI 2;
BA_ "GenSigSendType" SG_ 2564481456 AVN18DAE1B0_DIAG_DATA_EXT7 2;
BA_ "GenSigSendType" SG_ 2564481456 AVN18DAE1B0_DIAG_DATA_EXT6 2;
BA_ "GenSigSendType" SG_ 2564481456 AVN18DAE1B0_DIAG_DATA_EXT5 2;
BA_ "GenSigSendType" SG_ 2564481456 AVN18DAE1B0_DIAG_DATA_EXT4 2;
BA_ "GenSigSendType" SG_ 2564481456 AVN18DAE1B0_DIAG_DATA_EXT3 2;
BA_ "GenSigSendType" SG_ 2564481456 AVN18DAE1B0_DIAG_DATA_EXT2 2;
BA_ "GenSigSendType" SG_ 2564481456 AVN18DAE1B0_DIAG_DATA_EXT1 2;
BA_ "GenSigSendType" SG_ 2564481456 AVN18DAE1B0_DIAG_DATA 2;
BA_ "GenSigSendType" SG_ 2564468961 CECU18DAB0E1_DIAG_DATA_EXT7 2;
BA_ "GenSigSendType" SG_ 2564468961 CECU18DAB0E1_DIAG_DATA_EXT6 2;
BA_ "GenSigSendType" SG_ 2564468961 CECU18DAB0E1_DIAG_DATA_EXT5 2;
BA_ "GenSigSendType" SG_ 2564468961 CECU18DAB0E1_DIAG_DATA_EXT4 2;
BA_ "GenSigSendType" SG_ 2564468961 CECU18DAB0E1_DIAG_DATA_EXT3 2;
BA_ "GenSigSendType" SG_ 2564468961 CECU18DAB0E1_DIAG_DATA_EXT2 2;
BA_ "GenSigSendType" SG_ 2564468961 CECU18DAB0E1_DIAG_DATA_EXT1 2;
BA_ "GenSigSendType" SG_ 2564468961 CECU18DAB0E1_DIAG_DATA 2;
BA_ "GenSigSendType" SG_ 2564481573 CECU18DAE225_DIAG_DATA_EXT7 2;
BA_ "GenSigSendType" SG_ 2564481573 CECU18DAE225_DIAG_DATA_EXT6 2;
BA_ "GenSigSendType" SG_ 2564481573 CECU18DAE225_DIAG_DATA_EXT5 2;
BA_ "GenSigSendType" SG_ 2564481573 CECU18DAE225_DIAG_DATA_EXT4 2;
BA_ "GenSigSendType" SG_ 2564481573 CECU18DAE225_DIAG_DATA_EXT3 2;
BA_ "GenSigSendType" SG_ 2564481573 CECU18DAE225_DIAG_DATA_EXT2 2;
BA_ "GenSigSendType" SG_ 2564481573 CECU18DAE225_DIAG_DATA_EXT1 2;
BA_ "GenSigSendType" SG_ 2564481573 CECU18DAE225_DIAG_DATA 2;
BA_ "GenSigSendType" SG_ 2564433378 DCM18DA25E2_DIAG_DATA_EXT7 2;
BA_ "GenSigSendType" SG_ 2564433378 DCM18DA25E2_DIAG_DATA_EXT6 2;
BA_ "GenSigSendType" SG_ 2564433378 DCM18DA25E2_DIAG_DATA_EXT5 2;
BA_ "GenSigSendType" SG_ 2564433378 DCM18DA25E2_DIAG_DATA_EXT4 2;
BA_ "GenSigSendType" SG_ 2564433378 DCM18DA25E2_DIAG_DATA_EXT3 2;
BA_ "GenSigSendType" SG_ 2564433378 DCM18DA25E2_DIAG_DATA_EXT2 2;
BA_ "GenSigSendType" SG_ 2564433378 DCM18DA25E2_DIAG_DATA_EXT1 2;
BA_ "GenSigSendType" SG_ 2564433378 DCM18DA25E2_DIAG_DATA 2;
BA_ "GenSigSendType" SG_ 1892 DCM764_7_0_DIAG_DATA 2;
BA_ "GenSigSendType" SG_ 1892 DCM764_2_0_DIAG_N_PCI_OR_DATA 2;
BA_ "GenSigSendType" SG_ 1892 DCM764_1_0_DIAG_N_PCI_OR_DATA 2;
BA_ "GenSigSendType" SG_ 1892 DCM764_0_0_DIAG_N_PCI 2;
BA_ "GenSigSendType" SG_ 1848 VDC738_7_0_DIAG_DATA 2;
BA_ "GenSigSendType" SG_ 1848 VDC738_2_0_DIAG_N_PCI_OR_DATA 2;
BA_ "GenSigSendType" SG_ 1848 VDC738_1_0_DIAG_N_PCI_OR_DATA 2;
BA_ "GenSigSendType" SG_ 1848 VDC738_0_0_DIAG_N_PCI 2;
BA_ "GenSigSendType" SG_ 1840 DCM730_7_0_DIAG_DATA 2;
BA_ "GenSigSendType" SG_ 1840 DCM730_2_0_DIAG_N_PCI_OR_DATA 2;
BA_ "GenSigSendType" SG_ 1840 DCM730_1_0_DIAG_N_PCI_OR_DATA 2;
BA_ "GenSigSendType" SG_ 1840 DCM730_0_0_DIAG_N_PCI 2;
BA_ "GenSigSendType" SG_ 1807 CGW70F_7_0_DIAG_DATA 2;
BA_ "GenSigSendType" SG_ 1807 CGW70F_2_0_DIAG_N_PCI_OR_DATA 2;
BA_ "GenSigSendType" SG_ 1807 CGW70F_1_0_DIAG_N_PCI_OR_DATA 2;
BA_ "GenSigSendType" SG_ 1807 CGW70F_0_0_DIAG_N_PCI 2;
BA_ "GenSigStartValue" SG_ 996 CECU3E4_6_0_CHARGE_LEVEL_ENG_RUN 3;
BA_ "GenSigStartValue" SG_ 996 CECU3E4_6_4_CHARGE_LEVEL_IGN_ON 3;
BA_ "GenSigStartValue" SG_ 1632 CGW660_1_0_SUB_ID 65535;
BA_ "GenSigSendType" SG_ 1630 DCM65E_2_0_DATA2 4;
BA_ "GenSigSendType" SG_ 1630 DCM65E_1_4_DATA1 4;
BA_ "GenSigSendType" SG_ 1753 CECU6D9_2_0_RCC_DOOR_LOCK_REQ 3;
BA_ "GenSigSendType" SG_ 1753 CECU6D9_2_1_RCC_KEY_SEARCH_REQ 3;
BA_ "GenSigSendType" SG_ 1753 CECU6D9_2_2_RCC_BWAM_SETTING 3;
BA_ "GenSigSendType" SG_ 1753 CECU6D9_1_4_RCC_FLG 3;
BA_ "GenSigSendType" SG_ 1753 CECU6D9_0_0_CHECK_SUM 3;
BA_ "GenSigSendType" SG_ 1748 CECU6D4_4_0_TARGET_POS_PRG 3;
BA_ "GenSigSendType" SG_ 1748 CECU6D4_2_0_REQ_PRG_STOP 3;
BA_ "GenSigSendType" SG_ 1748 CECU6D4_2_1_REQ_PRG_ACT 3;
BA_ "GenSigSendType" SG_ 1736 CECU6C8_5_0_RSRSST 2;
BA_ "GenSigSendType" SG_ 1736 CECU6C8_4_0_RSRSKID 2;
BA_ "GenSigSendType" SG_ 1736 CECU6C8_4_4_RSRSNT 2;
BA_ "GenSigSendType" SG_ 1736 CECU6C8_2_0_RSRS_SlotID 2;
BA_ "GenSigSendType" SG_ 1736 CECU6C8_1_0_MSG_COUNT 2;
BA_ "GenSigSendType" SG_ 1736 CECU6C8_1_4_RSRSCOM 2;
BA_ "GenSigSendType" SG_ 1736 CECU6C8_0_0_CHECKSUM 2;
BA_ "GenSigSendType" SG_ 1739 DCM6CB_5_0_DKY_SLOT_ID 4;
BA_ "GenSigSendType" SG_ 1739 DCM6CB_4_0_DKY_COM_REQ 4;
BA_ "GenSigSendType" SG_ 1739 DCM6CB_3_5_PNC_SW_REQ_SRV 4;
BA_ "GenSigSendType" SG_ 1739 DCM6CB_2_0_SHUTDOWN_REQ 4;
BA_ "GenSigSendType" SG_ 1739 DCM6CB_2_3_IGB_OFF_REQUEST 4;
BA_ "GenSigSendType" SG_ 1739 DCM6CB_2_4_IGB_ON_REQUEST 4;
BA_ "GenSigSendType" SG_ 1739 DCM6CB_2_5_REARGATE_UNLOCK_REQ 4;
BA_ "GenSigSendType" SG_ 1739 DCM6CB_2_6_DOOR_UNLOCK_REQ 4;
BA_ "GenSigSendType" SG_ 1739 DCM6CB_2_7_DOOR_LOCK_REQUEST 4;
BA_ "GenSigSendType" SG_ 1739 DCM6CB_1_4_REQ_SVR_HAZARD_ON 4;
BA_ "GenSigSendType" SG_ 1739 DCM6CB_1_5_HORNHZRD_DEACT_REQ 4;
BA_ "GenSigSendType" SG_ 1739 DCM6CB_1_6_HAZARD_ACT_REQ 4;
BA_ "GenSigSendType" SG_ 1739 DCM6CB_1_7_HORNHAZARD_ACT_REQ 4;
BA_ "GenSigSendType" SG_ 1155 DCM483_18_0_DEP_TIM4_WEEKDAY_REQ 4;
BA_ "GenSigStartValue" SG_ 1155 DCM483_16_0_DEP_TIM4_ST_TIME_REQ 2046;
BA_ "GenSigSendType" SG_ 1155 DCM483_16_0_DEP_TIM4_ST_TIME_REQ 4;
BA_ "GenSigSendType" SG_ 1155 DCM483_15_5_DEP_TIM4_SW_REQ 4;
BA_ "GenSigSendType" SG_ 1155 DCM483_15_7_DEP_TIM4_PERFLG_REQ 4;
BA_ "GenSigSendType" SG_ 1155 DCM483_14_0_DEP_TIM3_WEEKDAY_REQ 4;
BA_ "GenSigStartValue" SG_ 1155 DCM483_12_0_DEP_TIM3_ST_TIME_REQ 2046;
BA_ "GenSigSendType" SG_ 1155 DCM483_12_0_DEP_TIM3_ST_TIME_REQ 4;
BA_ "GenSigSendType" SG_ 1155 DCM483_11_5_DEP_TIM3_SW_REQ 4;
BA_ "GenSigSendType" SG_ 1155 DCM483_11_7_DEP_TIM3_PERFLG_REQ 4;
BA_ "GenSigSendType" SG_ 1155 DCM483_10_0_DEP_TIM2_WEEKDAY_REQ 4;
BA_ "GenSigStartValue" SG_ 1155 DCM483_8_0_DEP_TIM2_ST_TIME_REQ 2046;
BA_ "GenSigSendType" SG_ 1155 DCM483_8_0_DEP_TIM2_ST_TIME_REQ 4;
BA_ "GenSigSendType" SG_ 1155 DCM483_7_7_DEP_TIM2_PERFLG_REQ 4;
BA_ "GenSigSendType" SG_ 1155 DCM483_7_5_DEP_TIM2_SW_REQ 4;
BA_ "GenSigSendType" SG_ 1155 DCM483_6_0_DEP_TIM1_WEEKDAY_REQ 4;
BA_ "GenSigStartValue" SG_ 1155 DCM483_4_0_DEP_TIM1_ST_TIME_REQ 2046;
BA_ "GenSigSendType" SG_ 1155 DCM483_4_0_DEP_TIM1_ST_TIME_REQ 4;
BA_ "GenSigSendType" SG_ 1155 DCM483_3_5_DEP_TIM1_SW_REQ 4;
BA_ "GenSigSendType" SG_ 1155 DCM483_3_7_DEP_TIM1_PERFLG_REQ 4;
BA_ "GenSigSendType" SG_ 1154 DCM482_30_0_CHG_BTN_SET_REQ 4;
BA_ "GenSigStartValue" SG_ 1154 DCM482_29_0_FED_LOLMT_REQ 20;
BA_ "GenSigSendType" SG_ 1154 DCM482_29_0_FED_LOLMT_REQ 4;
BA_ "GenSigStartValue" SG_ 1154 DCM482_28_0_ACCHG_CURUPLMT_REQ 14;
BA_ "GenSigSendType" SG_ 1154 DCM482_28_0_ACCHG_CURUPLMT_REQ 4;
BA_ "GenSigStartValue" SG_ 1154 DCM482_28_4_DCCHG_PWRUPLMT_REQ 14;
BA_ "GenSigSendType" SG_ 1154 DCM482_28_4_DCCHG_PWRUPLMT_REQ 4;
BA_ "GenSigStartValue" SG_ 1154 DCM482_27_0_CHG_HILMT_REQ 126;
BA_ "GenSigSendType" SG_ 1154 DCM482_27_0_CHG_HILMT_REQ 4;
BA_ "GenSigSendType" SG_ 1154 DCM482_26_0_TIM4_CHG_WEEKDAY_REQ 4;
BA_ "GenSigStartValue" SG_ 1154 DCM482_24_0_TIM4_CHG_ENDTIME_REQ 2046;
BA_ "GenSigSendType" SG_ 1154 DCM482_24_0_TIM4_CHG_ENDTIME_REQ 4;
BA_ "GenSigSendType" SG_ 1154 DCM482_22_0_TIM4_CHG_SETTYPE_REQ 4;
BA_ "GenSigStartValue" SG_ 1154 DCM482_22_2_TIM4_CHG_ST_TIME_REQ 2046;
BA_ "GenSigSendType" SG_ 1154 DCM482_22_2_TIM4_CHG_ST_TIME_REQ 4;
BA_ "GenSigStartValue" SG_ 1154 DCM482_21_5_TIM4_CHG_SW_REQ 3;
BA_ "GenSigSendType" SG_ 1154 DCM482_21_5_TIM4_CHG_SW_REQ 4;
BA_ "GenSigSendType" SG_ 1154 DCM482_20_0_TIM3_CHG_WEEKDAY_REQ 4;
BA_ "GenSigStartValue" SG_ 1154 DCM482_18_0_TIM3_CHG_ENDTIME_REQ 2046;
BA_ "GenSigSendType" SG_ 1154 DCM482_18_0_TIM3_CHG_ENDTIME_REQ 4;
BA_ "GenSigSendType" SG_ 1154 DCM482_16_0_TIM3_CHG_SETTYPE_REQ 4;
BA_ "GenSigStartValue" SG_ 1154 DCM482_16_2_TIM3_CHG_ST_TIME_REQ 2046;
BA_ "GenSigSendType" SG_ 1154 DCM482_16_2_TIM3_CHG_ST_TIME_REQ 4;
BA_ "GenSigStartValue" SG_ 1154 DCM482_15_5_TIM3_CHG_SW_REQ 3;
BA_ "GenSigSendType" SG_ 1154 DCM482_15_5_TIM3_CHG_SW_REQ 4;
BA_ "GenSigSendType" SG_ 1154 DCM482_14_0_TIM2_CHG_WEEKDAY_REQ 4;
BA_ "GenSigStartValue" SG_ 1154 DCM482_12_0_TIM2_CHG_ENDTIME_REQ 2046;
BA_ "GenSigSendType" SG_ 1154 DCM482_12_0_TIM2_CHG_ENDTIME_REQ 4;
BA_ "GenSigSendType" SG_ 1154 DCM482_10_0_TIM2_CHG_SETTYPE_REQ 4;
BA_ "GenSigStartValue" SG_ 1154 DCM482_10_2_TIM2_CHG_ST_TIME_REQ 2046;
BA_ "GenSigSendType" SG_ 1154 DCM482_10_2_TIM2_CHG_ST_TIME_REQ 4;
BA_ "GenSigStartValue" SG_ 1154 DCM482_9_5_TIM2_CHG_SW_REQ 3;
BA_ "GenSigSendType" SG_ 1154 DCM482_9_5_TIM2_CHG_SW_REQ 4;
BA_ "GenSigSendType" SG_ 1154 DCM482_8_0_TIM1_CHG_WEEKDAY_REQ 4;
BA_ "GenSigStartValue" SG_ 1154 DCM482_6_0_TIM1_CHG_ENDTIME_REQ 2046;
BA_ "GenSigSendType" SG_ 1154 DCM482_6_0_TIM1_CHG_ENDTIME_REQ 4;
BA_ "GenSigSendType" SG_ 1154 DCM482_4_0_TIM1_CHG_SETTYPE_REQ 4;
BA_ "GenSigStartValue" SG_ 1154 DCM482_4_2_TIM1_CHG_ST_TIME_REQ 2046;
BA_ "GenSigSendType" SG_ 1154 DCM482_4_2_TIM1_CHG_ST_TIME_REQ 4;
BA_ "GenSigStartValue" SG_ 1154 DCM482_3_5_TIM1_CHG_SW_REQ 3;
BA_ "GenSigSendType" SG_ 1154 DCM482_3_5_TIM1_CHG_SW_REQ 4;
BA_ "GenSigStartValue" SG_ 930 MET3A2_7_0_FUEL_AMOUNT 254;
BA_ "GenSigStartValue" SG_ 1677 MET68D_5_0_TEMP_FOR_PPA 8191;
BA_ "Fhi_SignalComment" SG_ 1677 MET68D_2_0_ODO "000000h～98967Fh：正常

989680h～FFFFFEh：未使用

FFFFFFh：異常

";
BA_ "GenSigStartValue" SG_ 1676 MET68C_2_0_CRUISING_RADIUS 254;
BA_ "GenSigStartValue" SG_ 922 MET39A_5_2_AVE_FUEL_ECONOMY 1022;
BA_ "GenSigStartValue" SG_ 922 MET39A_4_0_INSTANTANEOUS_FUEL 1022;
BA_ "Fhi_SignalComment" SG_ 922 MET39A_3_1_STATUS_FUEL_LAMP "IGN_OFF時：IGN_OFF直前の値

";
BA_ "GenSigStartValue" SG_ 915 MET393_6_0_R_DIFF_TEMP 253;
BA_ "Fhi_SignalComment" SG_ 915 MET393_6_0_R_DIFF_TEMP "IGN-ON初回送信時はFEhを送信する。

";
BA_ "GenSigStartValue" SG_ 915 MET393_4_0_FUEL_LEVEL_RESIST 1022;
BA_ "Fhi_SignalComment" SG_ 915 MET393_3_5_SI_DRIVE_SW "IGN　ON時の初期値は各SIドライブとXモードの組み合わせにより異なる。

";
BA_ "GenSigStartValue" SG_ 915 MET393_2_0_OUTTEMP_FOR_DIAG 8191;
BA_ "Fhi_SignalComment" SG_ 912 MET390_6_0_SEATBELT_DRVR "IGN-OFF中は0送信

";
BA_ "Fhi_SignalComment" SG_ 912 MET390_6_1_SEATBELT_PASS "IGN-OFF中は0送信

";
BA_ "GenSigStartValue" SG_ 912 MET390_4_0_OUTTEMP_FOR_IND 254;
BA_ "Fhi_SignalComment" SG_ 912 MET390_4_0_OUTTEMP_FOR_IND "IGN-OFF中は初期値：FEh送信

";
BA_ "Fhi_SignalComment" SG_ 912 MET390_2_0_VEHICLE_SERIES "GW:ID390-B2b2~b0→ID2BE-B5b2~b0

";
BA_ "Fhi_SignalComment" SG_ 912 MET390_2_3_DESTINATION "GW:ID390-B2b6~b3→ID2BE-B5b6~b3

";
VAL_ 862 BAT35E_4_4_HVB_CONDCHK_FLG 3 "NONE" 2 "NONE" 1 "ON" 0 "OFF" ;
VAL_ 862 BAT35E_3_0_HVB_WRN_TEMP 3 "NONE" 2 "LOW_TEMP" 1 "HI_TEMP" 0 "NO_REQ" ;
VAL_ 1539 BEV603_15_0_BATTEMPSTS_DISP 5 "Hi" 4 "Hi-数字" 3 "Mid" 2 "Lo-数字" 1 "Lo" 0 "NOT ACTIVE" ;
VAL_ 1539 BEV603_14_0_RR_MTRTEMPSTS_DISP 5 "Hi" 4 "Hi-数字" 3 "Mid" 2 "Lo-数字" 1 "Lo" 0 "NOT ACTIVE" ;
VAL_ 1539 BEV603_14_3_FR_MTRTEMPSTS_DISP 5 "Hi" 4 "Hi-数字" 3 "Mid" 2 "Lo-数字" 1 "Lo" 0 "NOT ACTIVE" ;
VAL_ 1539 BEV603_10_2_TRQFLCREQ 3 "NONE" 2 "ON#2" 1 "ON#1" 0 "OFF" ;
VAL_ 1539 BEV603_10_4_TRQFLCNG 1 "INHIBIT" 0 "PERMIT" ;
VAL_ 1539 BEV603_10_5_TRQFLCSTATE 1 "ON" 0 "OFF" ;
VAL_ 1539 BEV603_10_6_TRQFLCDISP 1 "ON" 0 "OFF" ;
VAL_ 1539 BEV603_10_7_TRQVIBREQ 1 "REQ" 0 "NON_REQ" ;
VAL_ 1539 BEV603_9_4_PADL_INHBUZ 1 "REQ" 0 "NON_REQ" ;
VAL_ 1539 BEV603_8_1_XMODE_INH 1 "INHIBIT" 0 "PERMIT" ;
VAL_ 1539 BEV603_8_2_SIDRIVE_INH 1 "INHIBIT" 0 "PERMIT" ;
VAL_ 1539 BEV603_8_3_SIDRIVE_INHBUZ 1 "REQ" 0 "NON_REQ" ;
VAL_ 1539 BEV603_8_4_ARBIT_SIDR 1 "PERMIT" 0 "INHIBIT" ;
VAL_ 1539 BEV603_8_5_SIDRIVE_DISP 7 "PreS#" 6 "S#_TADAN" 5 "X(MUD･SAND･GRAVEL)" 4 "X(SNOW･DART)" 3 "S" 2 "I" 1 "S#" 0 "TURN_OFF" ;
VAL_ 1539 BEV603_7_4_ADPDEC_INHBUZ 1 "REQ" 0 "NON_REQ" ;
VAL_ 1539 BEV603_7_5_ADPDEC_INH_ALL 1 "INHIBIT" 0 "PERMIT" ;
VAL_ 1539 BEV603_7_6_ADPDEC_DISP 1 "ON" 0 "OFF" ;
VAL_ 1539 BEV603_7_7_ADPDEC_EQ 1 "EQUIP" 0 "NON" ;
VAL_ 1539 BEV603_6_0_AWD_MODE 7 "AWD MODE #Fail" 4 "AWD MODE #4" 3 "AWD MODE #3" 2 "AWD MODE #2" 1 "AWD MODE #1" 0 "AWD MODE #0" ;
VAL_ 1539 BEV603_6_3_AWD_STS_DISP 7 "REQ #7" 6 "REQ #6" 5 "REQ #5" 4 "REQ #4" 3 "REQ #3" 2 "REQ #2" 1 "REQ #1" 0 "NON REQ" ;
VAL_ 1539 BEV603_6_4_DECSEL_INHMSG 15 "MSG#15" 14 "MSG#14" 13 "MSG#13" 12 "MSG#12" 11 "MSG#11" 10 "MSG#10" 9 "MSG#9" 8 "MSG#8" 7 "MSG#7" 6 "MSG#6" 5 "MSG#5" 4 "MSG#4" 3 "MSG#3" 2 "MSG#2" 1 "MSG#1" 0 "NO_MSG" ;
VAL_ 1539 BEV603_6_7_AWD_MODE_EQUIP 1 "AWD MODE" 0 "NON AWD MODE" ;
VAL_ 1539 BEV603_5_0_PDLBZR 1 "ON" 0 "OFF" ;
VAL_ 1539 BEV603_5_1_SFTDN_PERM 1 "PERMIT" 0 "INHIBIT" ;
VAL_ 1539 BEV603_5_2_SFTUP_PERM 1 "PERMIT" 0 "INHIBIT" ;
VAL_ 1539 BEV603_5_3_GEARSFT_MODE 3 "TADAN_MANUAL" 2 "TADAN_AUTO" 1 "DEC_SELECT" 0 "NOT ACTIVE" ;
VAL_ 1539 BEV603_5_4_DECSEL_INH_INDI 1 "INHIBIT" 0 "PERMIT" ;
VAL_ 1539 BEV603_5_5_DECSEL_INH_B 1 "INHIBIT" 0 "PERMIT" ;
VAL_ 1539 BEV603_5_6_DECSEL_INH_D 1 "INHIBIT" 0 "PERMIT" ;
VAL_ 1539 BEV603_5_7_DECSEL_INH_ALL 1 "INHIBIT" 0 "PERMIT" ;
VAL_ 1539 BEV603_4_1_DECSEL_DISP_INDI 1 "INHIBIT" 0 "PERMIT" ;
VAL_ 1539 BEV603_4_2_DECSEL_DISP_B 3 "Blank" 2 "Hi" 1 "Mid,Standard" 0 "Lo" ;
VAL_ 1539 BEV603_4_4_DECLV_DECSEL 8 "8" 7 "7" 6 "6" 5 "5" 4 "4" 3 "3" 2 "2" 1 "1" 0 "NOT ACTIVE" ;
VAL_ 1539 BEV603_4_6_DECSEL_DISP_ALL 3 "Blank" 2 "Hi" 1 "Mid,Standard" 0 "Lo" ;
VAL_ 1539 BEV603_3_0_GEARLV_MANU 8 "8" 7 "7" 6 "6" 5 "5" 4 "4" 3 "3" 2 "2" 1 "1" 0 "NOT ACTIVE" ;
VAL_ 1539 BEV603_3_1_DECSEL_EQ_INDI 1 "EQUIP" 0 "NON" ;
VAL_ 1539 BEV603_3_2_DECSEL_EQ_B 3 "BLANK" 2 "3TYPE" 1 "2TYPE" 0 "NON" ;
VAL_ 1539 BEV603_3_4_GEARLV_AUTO 8 "8" 7 "7" 6 "6" 5 "5" 4 "4" 3 "3" 2 "2" 1 "1" 0 "NOT ACTIVE" ;
VAL_ 1539 BEV603_3_6_DECSEL_EQ_ALL 3 "BLANK" 2 "3TYPE" 1 "2TYPE" 0 "NON" ;
VAL_ 1538 BEV602_16_0_LV_SYS_STATUS 3 "未定義" 2 "異常/低下LV2" 1 "異常/低下LV1" 0 "正常" ;
VAL_ 1538 BEV602_15_0_DCM_REMOTE_INFO 7 "Error Notification" 6 "Battery alert notification" 5 "Power supply end notification" 4 "Power supply start notification" 3 "Charging end notification" 2 "Charging status data feed" 1 "Charging start notification" 0 "No notification" ;
VAL_ 1538 BEV602_14_7_RR_DISPMSG_RES_UNADJ 1 "REQ" 0 "NON_REQ" ;
VAL_ 1538 BEV602_14_6_FR_DISPMSG_RES_UNADJ 1 "REQ" 0 "NON_REQ" ;
VAL_ 1538 BEV602_14_4_DISPMSG_SC_SGLPH 3 "Message_3" 2 "Message_2" 1 "Message_1" 0 "No_Message" ;
VAL_ 1538 BEV602_14_2_CERT2_MODE 2 "active(rear-wheel drive)" 1 "active(front-wheel drive)" 0 "Not active" ;
VAL_ 1538 BEV602_14_0_SW_PWR_SPL 3 "fail" 2 "OFF" 1 "ON" 0 "first" ;
VAL_ 1538 BEV602_13_0_TCSLMP_REQ 1 "REQ" 0 "NON_REQ" ;
VAL_ 1538 BEV602_13_1_AWDLMP_REQ 3 "TURN_ON" 2 "BLINK#2" 1 "BLINK#1" 0 "TURN_OFF" ;
VAL_ 1538 BEV602_13_3_AWDWRNMSG_REQ 2 "MSG#2" 1 "MSG#1" 0 "NO_MSG" ;
VAL_ 1538 BEV602_12_0_BOSLMP_REQ 3 "NON" 2 "NON" 1 "REQ" 0 "NON_REQ" ;
VAL_ 1538 BEV602_11_3_LVB_ABN 4 "12V充電システム通信異常" 3 "再始動不可" 2 "補機LIB故障" 1 "充電不足" 0 "表示要求なし" ;
VAL_ 1538 BEV602_11_6_CERT4_MODE 1 "ON" 0 "OFF" ;
VAL_ 1538 BEV602_10_0_FACT_CERT_MODE 1 "ON" 0 "OFF" ;
VAL_ 1538 BEV602_10_1_FACT_MODE 1 "ON" 0 "OFF" ;
VAL_ 1538 BEV602_10_2_EVBATLO_CAU 7 "Undegined" 6 "Undegined" 5 "Undegined" 4 "Undegined" 3 "Message3" 2 "Message2" 1 "Message1" 0 "No_Message" ;
VAL_ 1538 BEV602_10_5_PWRLMT_ID 3 "Message_3" 2 "Message_2" 1 "Message_1" 0 "No_Message" ;
VAL_ 1538 BEV602_9_1_DCRCHK_DSP_REQ 4 "charging system check complete" 3 "charging system fail (not clothing lid )" 2 "charging system check act" 1 "charging system fail" 0 "default" ;
VAL_ 1538 BEV602_9_4_LVB_FNCLMT_MSG 3 "抑制レベル2" 2 "抑制レベル1" 1 "逼迫状態" 0 "表示要求なし" ;
VAL_ 1538 BEV602_8_0_LVB_ABN_DCDC 2 "DCDCコンバータ出力停止中" 1 "DCDCコンバータ出力制限中" 0 "表示要求なし" ;
VAL_ 1538 BEV602_8_4_LVB_ABN_LIB 3 "補機LiB交換通知" 2 "補機LiB発熱レベル2" 1 "補機LiB発熱レベル1" 0 "表示要求なし" ;
VAL_ 1538 BEV602_8_7_CHG_CAU 1 "点灯要求あり" 0 "点灯要求なし" ;
VAL_ 1538 BEV602_7_0_V2L_STOP_MSG 8 "display8" 7 "display7" 6 "display6" 5 "display5" 4 "display4" 3 "display3" 2 "display2" 1 "display1" 0 "nondisplay" ;
VAL_ 1538 BEV602_5_0_V2L_OUTSTS_2 1 "V2L ACT" 0 "V2L OFF" ;
VAL_ 1538 BEV602_5_1_V2L_OUTSTS_1 1 "V2L ACT" 0 "V2L OFF" ;
VAL_ 1538 BEV602_5_2_ACCHCAU 1 "ON" 0 "OFF" ;
VAL_ 1538 BEV602_5_3_EVIND 49 "Undefined" 48 "Undefined" 41 "Undefined" 40 "Undefined" 39 "Undefined" 38 "Undefined" 37 "Undefined" 36 "Undefined" 35 "Undefined" 34 "Undefined" 33 "Undefined" 32 "Undefined" 25 "Undefined" 24 "Undefined" 23 "Undefined" 22 "Undefined" 21 "Undefined" 20 "Undefined" 19 "Undefined" 18 "Undefined" 17 "Undefined" 16 "Undefined" 9 "Message_9" 8 "Message_8" 7 "Message_7" 6 "Message_6" 5 "Message_5" 4 "Message_4" 3 "Message_3" 2 "Message_2" 1 "Message_1" 0 "No_Message" ;
VAL_ 1538 BEV602_4_0_BEV_OBD_CAU 7 "Undefine" 6 "Undefine" 5 "Undefine" 4 "Initial_Check" 3 "Flash_3Hz" 2 "Flash_1Hz" 1 "Turn_On" 0 "Turn_Off" ;
VAL_ 1538 BEV602_4_3_EV_CAU 3 "Undefine" 2 "Flash" 1 "Turn_On" 0 "Turn_Off" ;
VAL_ 1538 BEV602_4_5_PIROFF_MSG 1 "display" 0 "nondisplay" ;
VAL_ 1538 BEV602_3_0_DRVRDY 3 "Undefine" 2 "Turn_ON" 1 "Flash" 0 "Turn_Off" ;
VAL_ 1538 BEV602_3_2_RANGE_POS 7 "未定義" 6 "blank" 5 "未定義" 4 "B" 3 "D" 2 "N" 1 "R" 0 "P" ;
VAL_ 269 BEV10D_15_6_ENGON_SND 1 "ON" 0 "OFF" ;
VAL_ 269 BEV10D_15_7_BKF_SND 1 "ON" 0 "OFF" ;
VAL_ 269 BEV10D_11_6_SNDOUT_SET 1 "ON" 0 "OFF" ;
VAL_ 269 BEV10D_7_2_DCLLO_DISP 3 "NONE" 2 "NONE" 1 "MSG#A" 0 "NO_MSG" ;
VAL_ 269 BEV10D_7_4_PMINPWRLMTSTS 1 "ON" 0 "OFF" ;
VAL_ 269 BEV10D_7_5_PMOUTPWRLMTSTS 1 "ON" 0 "OFF" ;
VAL_ 495 BEV1EF_6_0_RRMOTROT_BK 3 "FS固定値" 2 "FSバックアップ値(符号無し)" 1 "FSバックアップ値" 0 "センサ値" ;
VAL_ 495 BEV1EF_6_2_FRMOTROT_BK 3 "FS固定値" 2 "FSバックアップ値(符号無し)" 1 "FSバックアップ値" 0 "センサ値" ;
VAL_ 267 BEV10B_6_7_SPEC8 1 "PERMIT" 0 "INHIBIT" ;
VAL_ 267 BEV10B_6_6_SPEC7 1 "PERMIT" 0 "INHIBIT" ;
VAL_ 267 BEV10B_6_5_SPEC6 1 "PERMIT" 0 "INHIBIT" ;
VAL_ 267 BEV10B_6_4_SPEC5 1 "PERMIT" 0 "INHIBIT" ;
VAL_ 267 BEV10B_6_3_SPEC4 1 "PERMIT" 0 "INHIBIT" ;
VAL_ 267 BEV10B_6_2_SPEC3 1 "PERMIT" 0 "INHIBIT" ;
VAL_ 267 BEV10B_6_1_SPEC2 1 "PERMIT" 0 "INHIBIT" ;
VAL_ 267 BEV10B_6_0_SPEC1 1 "PERMIT" 0 "INHIBIT" ;
VAL_ 267 BEV10B_5_2_DENO 1 "PERMIT" 0 "INHIBIT" ;
VAL_ 267 BEV10B_5_1_PROHIBIT_INC 1 "INHIBIT" 0 "PERMIT" ;
VAL_ 267 BEV10B_5_0_PERMIT_INC 1 "PERMIT" 0 "INHIBIT" ;
VAL_ 267 BEV10B_3_2_OBDRDY 1 "OBDReady-ON" 0 "OBDReady-OFF" ;
VAL_ 267 BEV10B_3_0_DRVRDY 3 "Undefine" 2 "Turn_ON" 1 "Flash" 0 "Turn_Off" ;
VAL_ 116 BEV074_7_0_LVPWRDWN 3 "抑制レベル3" 2 "抑制レベル2" 1 "抑制レベル1" 0 "抑制要求なし" ;
VAL_ 116 BEV074_7_6_CHRCONSTA 1 "Connected" 0 "NotConnected" ;
VAL_ 116 BEV074_7_7_VEHICLE_IGN 1 "ON" 0 "OFF" ;
VAL_ 116 BEV074_6_0_EV_CAU 3 "Undefine" 2 "Flash" 1 "Turn_On" 0 "Turn_Off" ;
VAL_ 116 BEV074_6_2_BEV_OBD_CAU 7 "Undefine" 6 "Undefine" 5 "Undefine" 4 "Initial_Check" 3 "Flash_3Hz" 2 "Flash_1Hz" 1 "Turn_On" 0 "Turn_Off" ;
VAL_ 116 BEV074_6_5_SIDRIVE_DISP 7 "PreS#" 6 "S#_TADAN" 5 "X(DEEP SNOW・MUD)" 4 "X(SNOW･DIRT)" 3 "S" 2 "I" 1 "S#" 0 "TURN_OFF" ;
VAL_ 116 BEV074_5_0_ACCHG_STATE 1 "充電実施中" 0 "充電未実施" ;
VAL_ 116 BEV074_5_1_DCCHG_STATE 1 "DC充電実施中" 0 "DC充電未実施" ;
VAL_ 116 BEV074_5_2_RANGE_DG 1 "異常" 0 "正常" ;
VAL_ 116 BEV074_5_3_ACCP_DG 1 "ON" 0 "OFF" ;
VAL_ 116 BEV074_5_4_REZ_SPD_BK 3 "FS固定値" 2 "FSバックアップ値(符号無し)" 1 "FSバックアップ値" 0 "センサ値" ;
VAL_ 116 BEV074_5_6_OBDRDY 1 "Ready-ON" 0 "Ready-OFF" ;
VAL_ 116 BEV074_5_7_FHVB 1 "ON" 0 "OFF" ;
VAL_ 116 BEV074_3_0_RANGE_POS 7 "未定義" 6 "blank" 5 "未定義" 4 "B" 3 "D" 2 "N" 1 "R" 0 "P" ;
VAL_ 116 BEV074_3_3_DRVRDY 3 "Undefine" 2 "Turn_ON" 1 "Flash" 0 "Turn_Off" ;
VAL_ 116 BEV074_3_5_HVSYSTS 3 "停止処理中" 2 "起動処理中" 1 "起動" 0 "停止" ;
VAL_ 116 BEV074_1_4_RANGE_DG2 1 "異常" 0 "正常" ;
VAL_ 116 BEV074_1_5_REZ_SPD_BK 5 "FS固定値" 4 "RrFSバックアップ値(符号無し)" 3 "FrFSバックアップ値(符号無し)" 2 "Rrセンサ値" 1 "Frセンサ値" 0 "FrRrセンサ値" ;
VAL_ 1774 CECU6EE_7_0_DESTINATION_INFO 3 "EUROPE_LH" 2 "EUROPE_RH" 1 "DOMESTIC" 0 "US_CANADA" ;
VAL_ 1774 CECU6EE_7_4_VEHICLE_SERIES 7 "NON" 6 "VEHICLE_W" 5 "VEHICLE_V" 4 "VEHICLE_Z" 3 "VEHICLE_S" 2 "VEHICLE_G" 1 "VEHICLE_B" 0 "DEFAULT" ;
VAL_ 1774 CECU6EE_6_0_DESTINATION_CODE 37 "NON" 36 "KR" 35 "KF" 34 "K2" 33 "C6" 32 "U7" 31 "E5" 30 "KG" 29 "E1" 28 "KE" 27 "KP" 26 "EH" 25 "E9" 24 "C4" 23 "KC" 22 "KV" 21 "KY" 20 "KA" 19 "EN" 18 "ER" 17 "EP" 16 "KS" 15 "K4" 14 "E3" 13 "EA" 12 "E7" 11 "ES" 10 "E2" 9 "EE" 8 "EK" 7 "C5" 6 "U5" 5 "EC" 4 "CO" 3 "U4" 2 "JPN" 1 "NON" 0 "DEFAULT" ;
VAL_ 1774 CECU6EE_5_0_EYE_VERSION_INFO 3 "VER4_HEIGHT_DRIVING_ASSIST" 2 "VER4" 1 "NO_EYE" 0 "DEFAULT" ;
VAL_ 1774 CECU6EE_5_4_VEHICLE_TYPE 1 "WGN" 0 "SDN" ;
VAL_ 1774 CECU6EE_5_6_PRODUCTION_BASE 1 "SIA" 0 "DOMESTIC" ;
VAL_ 1774 CECU6EE_4_2_WHEEL_DRIVE_TYPE 1 "4WD" 0 "FF" ;
VAL_ 1774 CECU6EE_4_3_3RD_SHEAT_EQUIPMENT 1 "EQUIPPED" 0 "NO_EQUIPPED" ;
VAL_ 1774 CECU6EE_4_4_FLG_XMODE 3 "X_MODE_2_MODE" 2 "X_MODE_1_MODE" 1 "NO_X_MODE" 0 "DEFAULT" ;
VAL_ 1774 CECU6EE_4_6_ISS_EQUIPMENT 1 "EQUIPPED" 0 "NO_EQUIPPED" ;
VAL_ 1773 CECU6ED_7_0_VEHICLE_TYPE_DETAIL 15 "NON" 14 "NON" 13 "NON" 12 "NON" 11 "NON" 10 "NON" 9 "NON" 8 "NON" 7 "COUPE" 6 "3RD_ROW_SUV" 5 "XUV" 4 "5D" 3 "OUTBACK" 2 "WGN" 1 "SD" 0 "DEFAULT" ;
VAL_ 1773 CECU6ED_5_0_TRANSMISSION_TYPE 1 "MT" 0 "CVT" ;
VAL_ 1773 CECU6ED_5_4_HANDLE 1 "RHD" 0 "LHD" ;
VAL_ 1773 CECU6ED_4_0_VEHICLE_HEIGHT 7 "NON" 6 "LIFT4" 5 "LIFT3" 4 "LIFT2" 3 "Wilderness" 2 "LIFT" 1 "STANDARD" 0 "DEFAULT" ;
VAL_ 1773 CECU6ED_4_4_SEATHEATER_EQUIPMENT 3 "SEAT_HEATER_D_P_REAR" 2 "SEAT_HEATER_D_P" 1 "NOT_SEAT_HEATER" 0 "DEFAULT" ;
VAL_ 1773 CECU6ED_3_0_YEAR_CHANGE 15 "NON" 14 "NON" 13 "NON" 12 "NON" 11 "NON" 10 "9" 9 "8" 8 "7" 7 "6" 6 "5" 5 "4" 4 "3" 3 "2" 2 "1" 1 "0" 0 "DEFAULT" ;
VAL_ 1773 CECU6ED_3_4_HEV_INFO 7 "NON" 6 "NON" 5 "BEV" 4 "SHEV" 3 "MHEV" 2 "PHEV" 1 "CONVE" 0 "DEFAULT" ;
VAL_ 1772 CECU6EC_6_0_SMT_EQUIPMENT 1 "EQUIPPED" 0 "NO_EQUIPPED" ;
VAL_ 1772 CECU6EC_6_1_DCCD_EQUIPMENT 1 "EQUIPPED" 0 "NO_EQUIPPED" ;
VAL_ 1772 CECU6EC_5_0_CCU_EQUIPMENT 1 "EQUIPPED" 0 "NO_EQUIPPED" ;
VAL_ 1772 CECU6EC_5_1_EAM_EQUIPMENT 1 "EQUIPPED" 0 "NO_EQUIPPED" ;
VAL_ 1772 CECU6EC_5_2_RCR_L_EQUIPMENT 1 "EQUIPPED" 0 "NO_EQUIPPED" ;
VAL_ 1772 CECU6EC_5_3_RCR_R_EQUIPMENT 1 "EQUIPPED" 0 "NO_EQUIPPED" ;
VAL_ 1772 CECU6EC_5_4_FCR_L_EQUIPMENT 1 "EQUIPPED" 0 "NO_EQUIPPED" ;
VAL_ 1772 CECU6EC_5_5_FCR_R_EQUIPMENT 1 "EQUIPPED" 0 "NO_EQUIPPED" ;
VAL_ 1772 CECU6EC_5_6_VSS_EQUIPMENT 1 "EQUIPPED" 0 "NO_EQUIPPED" ;
VAL_ 1772 CECU6EC_5_7_RES_EQUIPMENT 1 "EQUIPPED" 0 "NO_EQUIPPED" ;
VAL_ 1772 CECU6EC_4_0_LCT_EQUIPMENT 1 "EQUIPPED" 0 "NO_EQUIPPED" ;
VAL_ 1772 CECU6EC_4_1_DAM_EQUIPMENT 1 "EQUIPPED" 0 "NO_EQUIPPED" ;
VAL_ 1772 CECU6EC_4_2_MVS_EQUIPMENT 1 "EQUIPPED" 0 "NO_EQUIPPED" ;
VAL_ 1772 CECU6EC_4_3_TCU_EQUIPMENT 1 "EQUIPPED" 0 "NO_EQUIPPED" ;
VAL_ 1772 CECU6EC_4_4_TPM_EQUIPMENT 1 "EQUIPPED" 0 "NO_EQUIPPED" ;
VAL_ 1772 CECU6EC_4_5_DCM_EQUIPMENT 1 "EQUIPPED" 0 "NO_EQUIPPED" ;
VAL_ 1772 CECU6EC_4_6_MED_EQUIPMENT 1 "EQUIPPED" 0 "NO_EQUIPPED" ;
VAL_ 1772 CECU6EC_4_7_MEP_EQUIPMENT 1 "EQUIPPED" 0 "NO_EQUIPPED" ;
VAL_ 1772 CECU6EC_3_0_DATA_STATE 1 "ABNORMAL" 0 "NORMAL" ;
VAL_ 1772 CECU6EC_3_1_EYE_EQUIPMENT 1 "EQUIPPED" 0 "NO_EQUIPPED" ;
VAL_ 1772 CECU6EC_3_2_HEV_EQUIPMENT 1 "EQUIPPED" 0 "NO_EQUIPPED" ;
VAL_ 1772 CECU6EC_3_3_SNR_EQUIPMENT 1 "EQUIPPED" 0 "NO_EQUIPPED" ;
VAL_ 1772 CECU6EC_3_4_EPB_EQUIPMENT 1 "EQUIPPED" 0 "NO_EQUIPPED" ;
VAL_ 1772 CECU6EC_3_5_DMS_EQUIPMENT 1 "EQUIPPED" 0 "NO_EQUIPPED" ;
VAL_ 1772 CECU6EC_3_6_BST_EQUIPMENT 1 "EQUIPPED" 0 "NO_EQUIPPED" ;
VAL_ 1772 CECU6EC_3_7_MCA_EQUIPMENT 1 "EQUIPPED" 0 "NO_EQUIPPED" ;
VAL_ 996 CECU3E4_7_0_SSM_COMM_INFO 1 "COMM_ON" 0 "COMM_OFF" ;
VAL_ 996 CECU3E4_6_0_CHARGE_LEVEL_ENG_RUN 9 "level10" 8 "level9" 7 "level8" 6 "level7" 5 "level6" 4 "level5" 3 "level4" 2 "level3" 1 "level2" 0 "level1" ;
VAL_ 996 CECU3E4_6_4_CHARGE_LEVEL_IGN_ON 9 "level10" 8 "level9" 7 "level8" 6 "level7" 5 "level6" 4 "level5" 3 "level4" 2 "level3" 1 "level2" 0 "level1" ;
VAL_ 996 CECU3E4_5_0_GENERATOR_OVER_FLG 3 "EvLoadRestrain2" 2 "EvLoadRestrain1" 1 "Overloaded" 0 "NormalState" ;
VAL_ 996 CECU3E4_5_3_DIAG_COM_REQ 1 "Diag_Com_Request" 0 "No_Request" ;
VAL_ 996 CECU3E4_5_4_HEADS_UP_FLG 1 "ChargeRequest" 0 "Normal" ;
VAL_ 996 CECU3E4_2_7_OCCUPATION_CSTM 1 "D_SEAT" 0 "ALL_SEATS" ;
VAL_ 1280 CGW500_1_4_ActiveWakeUpBit 1 "active wakeup" 0 "passive wakeup" ;
VAL_ 1632 CGW660_1_0_SUB_ID 65535 "NORMAL" ;
VAL_ 1752 DCM6D8_1_4_PRESS_SOS_BUTTON 1 "ON" 0 "OFF" ;
VAL_ 1744 CECU6D0_4_0_OTA_ABORT 1 "OTA中止" 0 "OTA中止でない" ;
VAL_ 1744 CECU6D0_4_1_OTA_SUSPEND 1 "OTA中断" 0 "OTA中断でない" ;
VAL_ 1744 CECU6D0_4_2_OTA_SEQUENCE 33170 "予備" 16534 "予備" 8264 "Campaignなし" 4132 "OTA完了" 1298 "SWID照合中" 598 "電源ON待ち" 296 "電源OFF待ち" 100 "Activate中(Dual)" 50 "Install中(Single)" 22 "アップデート適用開始待ち" 8 "アップデート適用承諾待ち" 4 "Install中(Dual)" 2 "Download中" 1 "Campaign情報取得中" 0 "未実施" ;
VAL_ 1743 DCM6CF_6_6_AACN_FLG 1 "AACN有" 0 "AACN無" ;
VAL_ 1743 DCM6CF_5_0_EMERGENCY_CALL_ON_OFF 1 "Emergency_call_ON" 0 "Emergency_call_OFF" ;
VAL_ 1743 DCM6CF_4_2_STR_HEATER_ON_OFF 1 "Steering_heater_ON" 0 "Steering_heater_OFF" ;
VAL_ 1743 DCM6CF_3_0_RES_CONTRACT_INFO 1 "ON" 0 "OFF" ;
VAL_ 1743 DCM6CF_3_1_REQ_ST_ON 1 "ON" 0 "OFF" ;
VAL_ 1743 DCM6CF_3_3_ON_SIGN 1 "ON" 0 "OFF" ;
VAL_ 1743 DCM6CF_3_5_REQ_PARKLIGHT_HORN 7 "NOT REQUEST" 6 "NOT REQUEST" 5 "NOT REQUEST" 4 "PARK LIGHT ON&HORN OFF" 3 "PARK LIGHT&HORN ANSWER BACK 3 TIME" 2 "PARK LIGHT&HORN ANSWER BACK 2 TIME" 1 "PARK LIGHT&HORN ANSWER BACK 1 TIME" 0 "NOT REQUEST" ;
VAL_ 1743 DCM6CF_2_1_DCM_FAILURE_STATUS 1 "at least one failure is detected" 0 "no failure is detected" ;
VAL_ 1743 DCM6CF_2_2_REQ_WINDOW_STATUS 1 "REQUEST" 0 "NOT_REQUEST" ;
VAL_ 1743 DCM6CF_1_6_DKY_PROV_STS 1 "ON" 0 "OFF" ;
VAL_ 1743 DCM6CF_1_7_PNC_PROV_STS 1 "ON" 0 "OFF" ;
VAL_ 1301 DCM515_1_4_ActiveWakeUpBit 1 "active wakeup" 0 "passive wakeup" ;
VAL_ 1749 CECU6D5_6_0_CSTM_FMHD 7 "Undefined" 6 "Undefined" 5 "90sec" 4 "60sec" 3 "30sec" 2 "20sec" 1 "10sec" 0 "OFF" ;
VAL_ 1749 CECU6D5_5_0_CSTM_WRH 1 "ON" 0 "OFF" ;
VAL_ 1749 CECU6D5_5_1_CSTM_LMHD 3 "30sec" 2 "20sec" 1 "10sec" 0 "OFF" ;
VAL_ 1749 CECU6D5_5_5_CSTM_HBA 3 "Undefined" 2 "Undefined" 1 "ON" 0 "OFF" ;
VAL_ 1749 CECU6D5_5_7_ADB_ACTIVE 1 "ON" 0 "OFF" ;
VAL_ 1749 CECU6D5_4_0_JUDGE_ILL 1 "YES" 0 "NO" ;
VAL_ 1749 CECU6D5_4_1_HEADLAMP_AUTO_SW 1 "ON" 0 "OFF" ;
VAL_ 1749 CECU6D5_4_2_IND_ACTIVE_HBA 3 "Undefined" 2 "Blink" 1 "ON" 0 "OFF" ;
VAL_ 1749 CECU6D5_4_4_FGT_LGTOFF_WARNING 1 "ON" 0 "OFF" ;
VAL_ 1749 CECU6D5_3_0_CRN_R_REQ 3 "Undefined" 2 "ON" 1 "Faded OFF" 0 "OFF" ;
VAL_ 1749 CECU6D5_3_2_CRN_L_REQ 3 "Undefined" 2 "ON" 1 "Faded OFF" 0 "OFF" ;
VAL_ 1749 CECU6D5_3_4_FMH 1 "ON" 0 "OFF" ;
VAL_ 1749 CECU6D5_3_5_LMH 1 "ON" 0 "OFF" ;
VAL_ 1749 CECU6D5_2_0_LGT_1 1 "ON" 0 "OFF" ;
VAL_ 1749 CECU6D5_2_1_LGT_LO 1 "ON" 0 "OFF" ;
VAL_ 1749 CECU6D5_2_2_LGT_HI 1 "ON" 0 "OFF" ;
VAL_ 1749 CECU6D5_2_4_FFOG_RELAY_REQ 1 "ON" 0 "OFF" ;
VAL_ 1749 CECU6D5_2_5_RFOG_RELAY_REQ 1 "ON" 0 "OFF" ;
VAL_ 1749 CECU6D5_2_6_LGT_DRL 1 "ON" 0 "OFF" ;
VAL_ 1753 CECU6D9_2_2_RCC_BWAM_SETTING 1 "ON" 0 "OFF" ;
VAL_ 1753 CECU6D9_1_4_RCC_FLG 1 "RCC実行中" 0 "RCC停止中" ;
VAL_ 723 CECU2D3_2_5_IGA_STATE 1 "ON" 0 "OFF" ;
VAL_ 723 CECU2D3_2_6_IGB_STATE 1 "ON" 0 "OFF" ;
VAL_ 1748 CECU6D4_2_0_REQ_PRG_STOP 1 "STOP_REQUEST" 0 "NO_REQUEST" ;
VAL_ 1748 CECU6D4_2_1_REQ_PRG_ACT 5 "$5-15Reserved" 4 "RELEASE_REQUEST" 3 "OPEN_REQUEST_(MEMORY_ON)" 2 "CLOSE_REQUEST" 1 "OPEN_REQUEST_(MEMORY_OFF)" 0 "NO_REQUEST" ;
VAL_ 1736 CECU6C8_5_0_RSRSST 255 "NG4" 254 "NG3" 209 "NG2" 193 "NG1" 1 "OK" ;
VAL_ 1736 CECU6C8_4_4_RSRSNT 1 "1" 0 "0" ;
VAL_ 1736 CECU6C8_1_4_RSRSCOM 14 "Pattern8" 7 "Pattern7" 6 "Pattern6" 5 "Pattern5" 4 "Pattern4" 3 "Pattern3" 2 "Pattern2" 1 "Pattern1" ;
VAL_ 1701 CECU6A5_10_0_DCM_SHUTDOWN_RESULT 3 "Failed" 2 "Received" 1 "Completed" 0 "No_Action" ;
VAL_ 1701 CECU6A5_6_0_VEHICLE_STATE_INFO 17 "RCC_STOP_ERROR" 16 "USER_RIDING" 9 "TIMER_EXPIRATION" 8 "RCC_ERROR" 7 "DOOR_LOCK_ERROR" 6 "EV_BATTERY_LOW" 5 "CLIMATE_PROHIBITION" 4 "ALARM_SYS_ERROR" 3 "IGA_ON" 2 "OTA_SELF_REPROG" 1 "COMM_ERROR" 0 "NOMAL" ;
VAL_ 1701 CECU6A5_3_0_TARGET_FUNC 4 "RCC_STOP_BY_VEHICLE" 3 "RCC_STOP" 2 "RCC_START" 1 "WARNING_NOTICE" 0 "NO_OPERATION" ;
VAL_ 1739 DCM6CB_4_0_DKY_COM_REQ 18 "Friend device key deletion request" 6 "Vehicle PK/SK update request" 5 "Owner device key deletion request" 4 "Friend device key deletion request" 2 "Digital key deletion request" 0 "No request" ;
VAL_ 1739 DCM6CB_3_5_PNC_SW_REQ_SRV 5 "Certificate deletion request" 4 "Key unlock request" 3 "Key lock request" 2 "ON request" 1 "OFF request" 0 "No request" ;
VAL_ 1739 DCM6CB_2_0_SHUTDOWN_REQ 1 "ON" 0 "OFF" ;
VAL_ 1739 DCM6CB_2_3_IGB_OFF_REQUEST 1 "REQUEST" 0 "NOT_REQUEST" ;
VAL_ 1739 DCM6CB_2_4_IGB_ON_REQUEST 1 "REQUEST" 0 "NOT_REQUEST" ;
VAL_ 1155 DCM483_15_5_DEP_TIM4_SW_REQ 3 "Reserve" 2 "OFF" 1 "ON" 0 "Initial value" ;
VAL_ 1155 DCM483_15_7_DEP_TIM4_PERFLG_REQ 1 "Performance mode" 0 "Normal mode" ;
VAL_ 1155 DCM483_11_5_DEP_TIM3_SW_REQ 3 "Reserve" 2 "OFF" 1 "ON" 0 "Initial value" ;
VAL_ 1155 DCM483_11_7_DEP_TIM3_PERFLG_REQ 1 "Performance mode" 0 "Normal mode" ;
VAL_ 1155 DCM483_7_7_DEP_TIM2_PERFLG_REQ 1 "Performance mode" 0 "Normal mode" ;
VAL_ 1155 DCM483_7_5_DEP_TIM2_SW_REQ 3 "Reserve" 2 "OFF" 1 "ON" 0 "Initial value" ;
VAL_ 1155 DCM483_3_5_DEP_TIM1_SW_REQ 3 "Reserve" 2 "OFF" 1 "ON" 0 "Initial value" ;
VAL_ 1155 DCM483_3_7_DEP_TIM1_PERFLG_REQ 1 "Performance mode" 0 "Normal mode" ;
VAL_ 1154 DCM482_30_0_CHG_BTN_SET_REQ 3 "Preconditioning Requests" 2 "Charge Now Request" 1 "Charging Stop Request" 0 "No Request" ;
VAL_ 1154 DCM482_28_0_ACCHG_CURUPLMT_REQ 15 "Outlier" 14 "Initial value" 6 "8A" 5 "12A" 4 "16A" 3 "24A" 2 "32A" 1 "40A" 0 "MAX" ;
VAL_ 1154 DCM482_28_4_DCCHG_PWRUPLMT_REQ 15 "Outlier" 14 "Initial value" 8 "50KW" 7 "75KW" 6 "100KW" 5 "125KW" 4 "150KW" 3 "175KW" 2 "200KW" 1 "225KW" 0 "MAX" ;
VAL_ 1154 DCM482_22_0_TIM4_CHG_SETTYPE_REQ 2 "Time zone type setting" 1 "Start time type setting" 0 "Initial value" ;
VAL_ 1154 DCM482_21_5_TIM4_CHG_SW_REQ 3 "Initial value" 2 "ON" 1 "OFF" 0 "No timer setting" ;
VAL_ 1154 DCM482_16_0_TIM3_CHG_SETTYPE_REQ 2 "Time zone type setting" 1 "Start time type setting" 0 "Initial value" ;
VAL_ 1154 DCM482_15_5_TIM3_CHG_SW_REQ 3 "Initial value" 2 "ON" 1 "OFF" 0 "No timer setting" ;
VAL_ 1154 DCM482_10_0_TIM2_CHG_SETTYPE_REQ 2 "Time zone type setting" 1 "Start time type setting" 0 "Initial value" ;
VAL_ 1154 DCM482_9_5_TIM2_CHG_SW_REQ 3 "Initial value" 2 "ON" 1 "OFF" 0 "No timer setting" ;
VAL_ 1154 DCM482_4_0_TIM1_CHG_SETTYPE_REQ 2 "Time zone type setting" 1 "Start time type setting" 0 "Initial value" ;
VAL_ 1154 DCM482_3_5_TIM1_CHG_SW_REQ 3 "Initial value" 2 "ON" 1 "OFF" 0 "No timer setting" ;
VAL_ 1705 MVS6A9_6_0_CSTM_HITCHLINE_DSPREQ 3 "Reserved" 2 "Disp(Gray out)" 1 "Disp(Normal)" 0 "No Disp" ;
VAL_ 1705 MVS6A9_6_2_CSTM_HITCHLINE 1 "ON" 0 "OFF" ;
VAL_ 1705 MVS6A9_5_0_RR_WIDE_VIEW_SW_STATE 3 "Reserved" 2 "Selected" 1 "Not Selectable" 0 "Selectable" ;
VAL_ 1705 MVS6A9_5_2_RR_NRW_VIEW_SW_STATE 3 "Reserved" 2 "Selected" 1 "Not Selectable" 0 "Selectable" ;
VAL_ 1705 MVS6A9_5_4_HITCH_VIEW_SW_STATE 3 "Reserved" 2 "Selected" 1 "Not Selectable" 0 "Selectable" ;
VAL_ 1705 MVS6A9_4_0_FT_NRW_VIEW_SW_STATE 3 "Reserved" 2 "Selected" 1 "Not Selectable" 0 "Selectable" ;
VAL_ 1705 MVS6A9_4_2_FT_WIDE_VIEW_SW_STATE 3 "Reserved" 2 "Selected" 1 "Not Selectable" 0 "Selectable" ;
VAL_ 1705 MVS6A9_4_4_SIDE_VIEW_SW_STATE 3 "Reserved" 2 "Selected" 1 "Not Selectable" 0 "Selectable" ;
VAL_ 1705 MVS6A9_4_6_3D_VIEW_SW_STATE 3 "Reserved" 2 "Selected" 1 "Not Selectable" 0 "Selectable" ;
VAL_ 1705 MVS6A9_3_0_CSTM_AUTO_DISPLAY_SET 1 "Apply" 0 "No_Apply" ;
VAL_ 1705 MVS6A9_3_1_CSTM_AUTO_DISPLAY 1 "ON" 0 "OFF" ;
VAL_ 1705 MVS6A9_3_2_VIEW_MODE 3 "Other Mode" 2 "Parking Mode" 1 "Forward Mode" 0 "Backward Mode" ;
VAL_ 1705 MVS6A9_3_5_STOP_SWITCH 1 "Enable" 0 "Disable" ;
VAL_ 1705 MVS6A9_3_6_CSTM_HITCH_VIEW 1 "Available" 0 "Not Available" ;
VAL_ 1705 MVS6A9_2_0_CURRENT_VIEW 31 "Reserved" 30 "Reserved" 29 "Reserved" 28 "Reserved" 27 "Reserved" 26 "Reserved" 25 "Hitch Ball View" 24 "Top+3D View (FRONT)" 23 "Top View+Side and Side View" 22 "Top View+Front Narrow" 21 "Top View+Front Wide" 20 "Top View+Rear Narrow" 19 "Top View+Rear Wide" 18 "Left Side View Corresponded Regulation (reverse)" 17 "Left Side View Corresponded Regulation (Forward)" 16 "Top View (REAR)" 15 "3D Bird's View" 14 "Top and Rear View (RIGHT)" 13 "Top and Rear View (LEFT)" 12 "Top and Front View (RIGHT)" 11 "Top and Front View (LEFT)" 10 "Top View (FRONT)" 9 "Side and Side View" 8 "Front View and Side View (RIGHT)" 7 "Front View and Side View (LEFT)" 6 "Rear View and Side View (RIGHT)" 5 "Rear View and Side View (LEFT)" 4 "Side View (RIGHT)" 3 "Side View (LEFT)" 2 "Front View" 1 "Rear View" 0 "Black Display" ;
VAL_ 1705 MVS6A9_2_5_HOLD_TIME 1 "Short" 0 "Long" ;
VAL_ 1705 MVS6A9_1_4_FAIL_MVS 1 "FAIL" 0 "NORMAL" ;
VAL_ 1705 MVS6A9_1_5_FAIL_MVS_CAUSE 7 "No_Definition" 6 "No_Definition" 5 "No_Definition" 4 "EYE-MVS_CAN" 3 "Switch" 2 "Front_Camera" 1 "MVS" 0 "NORMAL" ;
VAL_ 930 MET3A2_6_0_SEATBELT_RR_RH 1 "ON_BeltOFF" 0 "OFF_BeltON" ;
VAL_ 930 MET3A2_6_1_SEATBELT_RR_CTR 1 "ON_BeltOFF" 0 "OFF_BeltON" ;
VAL_ 930 MET3A2_6_2_SEATBELT_RR_LH 1 "ON_BeltOFF" 0 "OFF_BeltON" ;
VAL_ 930 MET3A2_6_3_SEATBELT_THIRD_RH 1 "ON_BeltOFF" 0 "OFF_BeltON" ;
VAL_ 930 MET3A2_6_4_SEATBELT_THIRD_CTR 1 "ON_BeltOFF" 0 "OFF_BeltON" ;
VAL_ 930 MET3A2_6_5_SEATBELT_THIRD_LH 1 "ON_BeltOFF" 0 "OFF_BeltON" ;
VAL_ 930 MET3A2_5_0_FLG_RR_REMINDER 1 "REAR REMINDER ON" 0 "OFF" ;
VAL_ 930 MET3A2_1_4_FAIL_DISP 3 "Reserve" 2 "Reserve" 1 "MET_FAIL_DISP" 0 "NORMAL" ;
VAL_ 1677 MET68D_7_0_STATUS_WASHER_LAMP 1 "ON" 0 "OFF" ;
VAL_ 1677 MET68D_7_1_OILPRESSURE_SW 1 "SW_GND" 0 "SW_OPEN" ;
VAL_ 1677 MET68D_7_2_FLG_EAM 1 "EAM" 0 "NOT_EAM" ;
VAL_ 1677 MET68D_7_3_CSTM_IND_RED 1 "ON" 0 "OFF" ;
VAL_ 1677 MET68D_7_4_CSTM_IND_YELLOW 1 "ON" 0 "OFF" ;
VAL_ 1677 MET68D_7_5_CSTM_IND_GREEN 1 "ON" 0 "OFF" ;
VAL_ 1677 MET68D_7_6_REQ_CSTM_SRH 1 "required" 0 "NOT required" ;
VAL_ 1677 MET68D_7_7_CSTM_SRH 1 "ON" 0 "OFF" ;
VAL_ 1677 MET68D_6_5_REQ_CHG_CSTM_RAB 1 "required" 0 "NOT required" ;
VAL_ 1677 MET68D_6_6_CSTM_RAB 1 "ON" 0 "OFF" ;
VAL_ 1677 MET68D_6_7_CSTM_SONNER 1 "ON" 0 "OFF" ;
VAL_ 1677 MET68D_1_4_RESET_CSTM_TPMS_RAEB 1 "REQUIRED" 0 "NOT REQUIRED" ;
VAL_ 1677 MET68D_1_5_REQ_CHG_CSTM_TPMS 1 "required" 0 "NOT required" ;
VAL_ 1677 MET68D_1_6_CSTM_TIRE_UNIT 3 "未定義" 2 "bar" 1 "kPa" 0 "psi" ;
VAL_ 1676 MET68C_7_0_CSTM_OUTTEMP 15 "NONE" 14 "NONE" 13 "-5" 12 "-4" 11 "-3" 10 "-2" 9 "-1" 8 "-0" 7 "NONE" 6 "NONE" 5 "+5" 4 "+4" 3 "+3" 2 "+2" 1 "+1" 0 "+0" ;
VAL_ 1676 MET68C_4_6_UNIT_DEGREE 3 "reserved" 2 "deg F" 1 "deg C" 0 "Invalid" ;
VAL_ 1676 MET68C_3_0_MET_SW_STATE 3 "▼SW ON" 2 "i/SET SW ON" 1 "▲ SW ON" 0 "no SW input" ;
VAL_ 1676 MET68C_3_3_PERMIT_MFD_CSTM 1 "OK" 0 "NG" ;
VAL_ 1676 MET68C_3_5_FLG_RR_AC_PANEL 1 "REAR_AC_PANEL" 0 "NOT_REAR_AC_PANEL" ;
VAL_ 1676 MET68C_3_6_FLG_SEAT_VENT 1 "SEAT_VENT" 0 "NOT_SEAT_VENT" ;
VAL_ 1676 MET68C_3_7_FLG_SEAT_HEAT 1 "SEAT_HEATER" 0 "NOT_SEAT_HEATER" ;
VAL_ 1676 MET68C_1_4_CSTM_HU 1 "with HU" 0 "without HU" ;
VAL_ 1676 MET68C_1_5_CSTM_BRAND_NAME 1 "SBR" 0 "TMC" ;
VAL_ 922 MET39A_7_0_SET_LANGUAGE 21 "Norsk" 20 "Svenska" 19 "Dansk" 18 "Suomi" 17 "Ελληνικ?" 16 "Polski" 15 "Укра?нська" 14 "Turkce" 13 "Magyar" 12 "Ceske" 11 "Slovensky" 10 "Romana" 9 "China" 8 "Русский" 7 "Francais" 6 "Deutsh" 5 "Nederlands" 4 "Espanol" 3 "Portuges" 2 "Italiano" 1 "English" 0 "Japanese" ;
VAL_ 922 MET39A_7_5_ACTIVE_MET_CSTM 1 "ACTIVE" 0 "PASSIVE" ;
VAL_ 922 MET39A_7_6_MFD_SPEC 1 "color MFD" 0 "segment MFD" ;
VAL_ 922 MET39A_7_7_ICY_ROAD_SURFACE 2 "ON" 1 "OFF" ;
VAL_ 922 MET39A_6_4_STATUS_TRIP_A_B 1 "TRIP_B" 0 "TRIP_A" ;
VAL_ 922 MET39A_3_1_STATUS_FUEL_LAMP 3 "BLINK_SHORT/OPEN" 2 "TURN_ON_LFW" 1 "INITIAL_CHECK" 0 "TURN_OFF" ;
VAL_ 922 MET39A_3_3_TRANSIT_TIME 1 "1H" 0 "OFF" ;
VAL_ 922 MET39A_1_4_SET_UNIT_OF_FUEL 3 "MPG(英国ｶﾞﾛﾝ)" 2 "MPG(米国ｶﾞﾛﾝ)" 1 "l/100km" 0 "km/ｌ" ;
VAL_ 922 MET39A_1_6_WELCOME_TRIG 2 "ON" 1 "OFF" ;
VAL_ 922 MET39A_1_7_METER_DISPLAY_TYPE 2 "color TFT" 1 "segment LCD" ;
VAL_ 915 MET393_7_0_REQ_CHG_CSTM_EYE 1 "required" 0 "NOT required" ;
VAL_ 915 MET393_7_1_REQ_RESET_CSTM_EYE 1 "REQUIRED" 0 "NOT REQUIRED" ;
VAL_ 915 MET393_7_2_CSTM_ALK 1 "ON" 0 "OFF" ;
VAL_ 915 MET393_7_3_CSTM_HBA 1 "SAE_Mode" 0 "Normal" ;
VAL_ 915 MET393_7_4_CSTM_MIS_AT_BACK 3 "ON_FAST" 2 "ON_MIDDLE" 1 "ON_SLOW" 0 "OFF" ;
VAL_ 915 MET393_7_6_CSTM_ACC_CONT 3 "LEV4" 2 "LEV3" 1 "LEV2" 0 "LEV1" ;
VAL_ 915 MET393_5_2_WARN_R_DIFF_TEMP 3 "Turn_ON_Initial_Check" 2 "BLINK" 1 "Turn_ON" 0 "Turn_OFF" ;
VAL_ 915 MET393_5_4_ADAPTIVECC_NOALIVE 1 "NO_ALIVE" 0 "ALIVE" ;
VAL_ 915 MET393_5_5_DUAL_RANGE_LO 1 "SW GND" 0 "SW OPEN" ;
VAL_ 915 MET393_5_6_CSTM_SPD_LIMITER 1 "Control_ON" 0 "Control_OFF" ;
VAL_ 915 MET393_5_7_CSTM_LANE_CONT 1 "LEFT" 0 "RIGHT" ;
VAL_ 915 MET393_3_5_SI_DRIVE_SW 7 "BLANK_NoInput" 6 "I_Input" 5 "ECO-C_Input" 4 "I_Input" 3 "X_MUD_SAND_or_GRAVEL_Input" 2 "S#_Input" 1 "X_SNOW_DIRT_Input" 0 "BLANK_NoInput" ;
VAL_ 915 MET393_1_4_CSTM_IND_BLUE 1 "ON" 0 "OFF" ;
VAL_ 915 MET393_1_5_CSTM_AES_CONT 1 "ON" 0 "OFF" ;
VAL_ 915 MET393_1_6_FLG_PEDESTRIAN_AIRBAG 1 "OEDESTRIAN AIRBAG" 0 "OTHER" ;
VAL_ 912 MET390_7_0_VDC_ON_OFF 3 "BLANK_NoInput" 2 "VDC ON_Input" 1 "VDC OFF_Input" 0 "Neutral" ;
VAL_ 912 MET390_7_2_RR_DOOR_RECORD_L 1 "OPEN" 0 "CLOSE" ;
VAL_ 912 MET390_7_3_RR_DOOR_RECORD_R 1 "OPEN" 0 "CLOSE" ;
VAL_ 912 MET390_7_4_REQ_CHG_CSTM_PSM 1 "required" 0 "NOT required" ;
VAL_ 912 MET390_7_5_REQ_RESET_CSTM_PSM 1 "REQUIRED" 0 "NOT　REQUIRED" ;
VAL_ 912 MET390_7_6_CSTM_MIR_AFOLD_CONT 1 "ON" 0 "OFF" ;
VAL_ 912 MET390_7_7_CSTM_MIR_RTILT_CONT 1 "ON" 0 "OFF" ;
VAL_ 912 MET390_6_0_SEATBELT_DRVR 1 "ON" 0 "OFF" ;
VAL_ 912 MET390_6_1_SEATBELT_PASS 1 "ON" 0 "OFF" ;
VAL_ 912 MET390_6_2_TURN_SIG_LEFT 1 "Turn_L_OutPut" 0 "OFF" ;
VAL_ 912 MET390_6_3_TURN_SIG_RIGHT 1 "Turn_R_OutPut" 0 "OFF" ;
VAL_ 912 MET390_6_4_BRIGHT_SW 1 "ON" 0 "OFF" ;
VAL_ 912 MET390_6_5_FAIL_UART_WA_BOX 1 "FAIL" 0 "NORMAL" ;
VAL_ 912 MET390_6_6_ISS_OFF_SW 1 "While SW is being pushed down." 0 "While SW is not being pushed down." ;
VAL_ 912 MET390_6_7_FLG_DMS 1 "DMS" 0 "NOT_DMS" ;
VAL_ 912 MET390_3_0_UNIT_SPEED_TRIP 1 "MPH、miles" 0 "km/h、km" ;
VAL_ 912 MET390_3_1_FLG_EYESIGHT 1 "EYESIGHT" 0 "OTHER" ;
VAL_ 912 MET390_3_2_FLG_ISS 1 "ISS" 0 "OTHER" ;
VAL_ 912 MET390_3_3_FLG_HEV 1 "HEV" 0 "OTHER" ;
VAL_ 912 MET390_3_4_FLG_IMB 1 "IMB_ACTIVE" 0 "NON_IMB" ;
VAL_ 912 MET390_3_5_TIRE_SIZE 1 "SPECIAL_SIZE" 0 "STANDARD_SIZE" ;
VAL_ 912 MET390_3_6_FLG_XMODE 3 "X_2MODE(GRAVEL)" 2 "X_2MODE" 1 "X_1MODE" 0 "NOT_X" ;
VAL_ 912 MET390_2_0_VEHICLE_SERIES 7 "VEHICLE_Z" 6 "VEHICLE_W" 5 "VEHICLE_V" 4 "VEHICLE_B" 3 "VEHICLE_Y" 2 "VEHICLE_S" 1 "VEHICLE_G" 0 "NON" ;
VAL_ 912 MET390_2_3_DESTINATION 12 "KC" 11 "Korea_C6" 10 "China_EHETES" 9 "Australia_KA" 8 "Singapore_ERENKYKEKVKP" 7 "England_EK" 6 "SaudiArabia_KSKG" 5 "STANDARD_LH_K4E3E5C4" 4 "Europe_LH_ECEAE2EEEPE9E7E1" 3 "CANADA_C5C0" 2 "US_U4U5U6" 1 "DOM" 0 "NON" ;
VAL_ 912 MET390_2_7_PASS_DOOR_RECORD 1 "OPEN" 0 "CLOSE" ;
VAL_ 912 MET390_1_4_WAKE_UP_FRAME 1 "WakeUP_FRAME" 0 "Normal_FRAME" ;
VAL_ 912 MET390_1_5_REQ_COMM_CONT 1 "REQ" 0 "NON_REQ" ;
VAL_ 912 MET390_1_6_DMS_ID_SET 1 "REQUIRED" 0 "NOT REQUIRED" ;
VAL_ 912 MET390_1_7_FAIL_EEPROM 1 "FAIL" 0 "NORMAL" ;
